VERSION "HNNBNNNYNNNNNNNNNNNNNNNNNNNNNNNNNNNNNNNNNN/4/%%%/4/'%**4NNN///"

NS_ :

BS_:

BU_: BAP_Tester BedienDisp_vo BedienSG_hi CGS DDA Gateway Gateway_PAG GurtMikrofon OTA_FC ZR_High ZR_LIMU ZR_MIB_TOP_ab_Gen3 ZR_Standard

BO_ 1891 ISO_Gurtmikro_Req: 8 Gateway
 SG_ ISO_Gurtmikro_Req_Data : 0|64@1+ (1.0,0.0) [0.0|18446744073709551615] ""  GurtMikrofon

BO_ 1997 ISO_Gurtmikro_Resp: 8 GurtMikrofon
 SG_ ISO_Gurtmikro_Resp_Data : 0|64@1+ (1.0,0.0) [0.0|18446744073709551615] ""  Gateway,Gateway_PAG

BO_ 1907 ISO_Info_El_Req: 8 Gateway
 SG_ ISO_Info_El_Req_Data : 0|64@1+ (1.0,0.0) [0.0|18446744073709551615] ""  ZR_High,ZR_LIMU,ZR_MIB_TOP_ab_Gen3,ZR_Standard

BO_ 2013 ISO_Info_El_Resp: 8 ZR_High
 SG_ ISO_Info_El_Resp_Data : 0|64@1+ (1.0,0.0) [0.0|18446744073709551615] ""  Gateway,Gateway_PAG

BO_ 1904 ISO_Laufwerke_Req: 8 Gateway
 SG_ ISO_Laufwerke_Req_Data : 0|64@1+ (1.0,0.0) [0.0|18446744073709551615] ""  ZR_High,ZR_MIB_TOP_ab_Gen3,ZR_Standard

BO_ 2010 ISO_Laufwerke_Resp: 8 ZR_High
 SG_ ISO_Laufwerke_Resp_Data : 0|64@1+ (1.0,0.0) [0.0|18446744073709551615] ""  Gateway,Gateway_PAG

BO_ 1901 ISO_TV_Tuner_Req: 8 Gateway
 SG_ ISO_TV_Tuner_Req_Data : 0|64@1+ (1.0,0.0) [0.0|18446744073709551615] ""  ZR_High,ZR_MIB_TOP_ab_Gen3,ZR_Standard

BO_ 2007 ISO_TV_Tuner_Resp: 8 ZR_High
 SG_ ISO_TV_Tuner_Resp_Data : 0|64@1+ (1.0,0.0) [0.0|18446744073709551615] ""  Gateway,Gateway_PAG

BO_ 2549874830 ISOx_BedienDisp_vo_Req: 8 Gateway
 SG_ ISOx_BedienDisp_vo_Req_Data : 0|64@1+ (1.0,0.0) [0.0|18446744073709551615] ""  BedienDisp_vo

BO_ 2550005902 ISOx_BedienDisp_vo_Resp: 8 BedienDisp_vo
 SG_ ISOx_BedienDisp_vo_Resp_Data : 0|64@1+ (1.0,0.0) [0.0|18446744073709551615] ""  Gateway,Gateway_PAG

BO_ 2549874835 ISOx_BedienSG_hi_Req: 8 Gateway
 SG_ ISOx_BedienSG_hi_Req_Data : 0|64@1+ (1.0,0.0) [0.0|18446744073709551615] ""  BedienSG_hi

BO_ 2550005907 ISOx_BedienSG_hi_Resp: 8 BedienSG_hi
 SG_ ISOx_BedienSG_hi_Resp_Data : 0|64@1+ (1.0,0.0) [0.0|18446744073709551615] ""  Gateway,Gateway_PAG

BO_ 2549874874 ISOx_DDA_Req: 8 Gateway
 SG_ ISOx_DDA_Req_Data : 0|64@1+ (1.0,0.0) [0.0|18446744073709551615] ""  DDA

BO_ 2550005946 ISOx_DDA_Resp: 8 DDA
 SG_ ISOx_DDA_Resp_Data : 0|64@1+ (1.0,0.0) [0.0|18446744073709551615] ""  Gateway,Gateway_PAG

BO_ 2549874858 ISOx_SCC1_Req: 8 Gateway
 SG_ ISOx_SCC1_Req_Data : 0|64@1+ (1.0,0.0) [0.0|18446744073709551615] ""  ZR_High,ZR_MIB_TOP_ab_Gen3

BO_ 2550005930 ISOx_SCC1_Resp: 8 ZR_High
 SG_ ISOx_SCC1_Resp_Data : 0|64@1+ (1.0,0.0) [0.0|18446744073709551615] ""  Gateway,Gateway_PAG

BO_ 2549874859 ISOx_SCC2_Req: 8 Gateway
 SG_ ISOx_SCC2_Req_Data : 0|64@1+ (1.0,0.0) [0.0|18446744073709551615] ""  ZR_High,ZR_MIB_TOP_ab_Gen3

BO_ 2550005931 ISOx_SCC2_Resp: 8 ZR_High
 SG_ ISOx_SCC2_Resp_Data : 0|64@1+ (1.0,0.0) [0.0|18446744073709551615] ""  Gateway,Gateway_PAG

BO_ 2549874855 ISOx_SDC1_Req: 8 Gateway
 SG_ ISOx_SDC1_Req_Data : 0|64@1+ (1.0,0.0) [0.0|18446744073709551615] ""  ZR_High,ZR_MIB_TOP_ab_Gen3

BO_ 2550005927 ISOx_SDC1_Resp: 8 ZR_High
 SG_ ISOx_SDC1_Resp_Data : 0|64@1+ (1.0,0.0) [0.0|18446744073709551615] ""  Gateway,Gateway_PAG

BO_ 2549874856 ISOx_SDC2_Req: 8 Gateway
 SG_ ISOx_SDC2_Req_Data : 0|64@1+ (1.0,0.0) [0.0|18446744073709551615] ""  ZR_High,ZR_MIB_TOP_ab_Gen3

BO_ 2550005928 ISOx_SDC2_Resp: 8 ZR_High
 SG_ ISOx_SDC2_Resp_Data : 0|64@1+ (1.0,0.0) [0.0|18446744073709551615] ""  Gateway,Gateway_PAG

BO_ 2549874853 ISOx_WLC1_Req: 8 Gateway
 SG_ ISOx_WLC1_Req_Data : 0|64@1+ (1.0,0.0) [0.0|18446744073709551615] ""  ZR_High,ZR_MIB_TOP_ab_Gen3,ZR_Standard

BO_ 2550005925 ISOx_WLC1_Resp: 8 ZR_High
 SG_ ISOx_WLC1_Resp_Data : 0|64@1+ (1.0,0.0) [0.0|18446744073709551615] ""  Gateway,Gateway_PAG

BO_ 2549874854 ISOx_WLC2_Req: 8 Gateway
 SG_ ISOx_WLC2_Req_Data : 0|64@1+ (1.0,0.0) [0.0|18446744073709551615] ""  ZR_High,ZR_MIB_TOP_ab_Gen3

BO_ 2550005926 ISOx_WLC2_Resp: 8 ZR_High
 SG_ ISOx_WLC2_Resp_Data : 0|64@1+ (1.0,0.0) [0.0|18446744073709551615] ""  Gateway,Gateway_PAG

BO_ 497 Kessy_11: 8 Gateway
 SG_ KY_IDG_in_Reichweite : 12|1@1+ (1.0,0.0) [0.0|1] ""  Vector__XXX
 SG_ KY_Auf_Taste : 13|1@1+ (1.0,0.0) [0.0|1] ""  Vector__XXX
 SG_ KY_HDF_Taste : 14|1@1+ (1.0,0.0) [0.0|1] ""  Vector__XXX
 SG_ KY_Panik_Taste : 15|1@1+ (1.0,0.0) [0.0|1] ""  Vector__XXX
 SG_ KY_Zu_Taste : 16|1@1+ (1.0,0.0) [0.0|1] ""  Vector__XXX
 SG_ KY_FT_Entriegelung_Autorisiert : 17|1@1+ (1.0,0.0) [0.0|1] ""  ZR_High
 SG_ KY_FT_Verriegelung_Autorisiert : 18|1@1+ (1.0,0.0) [0.0|1] ""  ZR_High
 SG_ KY_BT_Entriegelung_Autorisiert : 19|1@1+ (1.0,0.0) [0.0|1] ""  ZR_High
 SG_ KY_BT_Verriegelung_Autorisiert : 20|1@1+ (1.0,0.0) [0.0|1] ""  ZR_High
 SG_ KY_HFS_Entriegelung_Autorisiert : 21|1@1+ (1.0,0.0) [0.0|1] ""  ZR_High
 SG_ KY_HFS_Verriegelung_Autorisiert : 22|1@1+ (1.0,0.0) [0.0|1] ""  ZR_High
 SG_ KY_HBFS_Entriegelung_Autorisiert : 23|1@1+ (1.0,0.0) [0.0|1] ""  ZR_High
 SG_ KY_HBFS_Verriegelung_Autorisiert : 24|1@1+ (1.0,0.0) [0.0|1] ""  ZR_High
 SG_ KY_Front_Entr_Autorisiert : 25|1@1+ (1.0,0.0) [0.0|1] ""  ZR_High
 SG_ KY_Front_Verr_Autorisiert : 26|1@1+ (1.0,0.0) [0.0|1] ""  ZR_High
 SG_ KY_HD_Entriegelung_Autorisiert : 27|1@1+ (1.0,0.0) [0.0|1] ""  ZR_High
 SG_ KY_HD_Verriegelung_Autorisiert : 28|1@1+ (1.0,0.0) [0.0|1] ""  ZR_High
 SG_ KY_Bereich : 29|3@1+ (1.0,0.0) [0.0|7] ""  Vector__XXX
 SG_ KY_Position : 32|3@1+ (1.0,0.0) [0.0|7] ""  Vector__XXX
 SG_ KY_ZV_Signatur : 35|11@1+ (1,0) [0|2047] "Unit_None"  Vector__XXX
 SG_ Schluesselnr_Personalisierung : 46|4@1+ (1.0,0.0) [0.0|15] ""  BedienSG_hi,ZR_High
 SG_ FFB_FDF_Taste : 50|1@1+ (1.0,0.0) [0.0|1] ""  Vector__XXX
 SG_ FFB_Joker_Taste : 51|1@1+ (1.0,0.0) [0.0|1] ""  ZR_High
 SG_ FFB_Park_Taste : 52|1@1+ (1.0,0.0) [0.0|1] ""  Vector__XXX
 SG_ FFB_Remotestart_Taste : 53|1@1+ (1.0,0.0) [0.0|1] ""  Vector__XXX
 SG_ FBS_Aktivierung_Pilot_Parken : 54|1@1+ (1.0,0.0) [0.0|1] ""  ZR_High
 SG_ KY_Schluessel_im_Fzg : 55|1@1+ (1.0,0.0) [0.0|1] ""  Vector__XXX
 SG_ KY_EasyClose_Abbruch : 56|1@1+ (1.0,0.0) [0.0|1] ""  Vector__XXX
 SG_ KY_EasyClose_Status : 57|3@1+ (1.0,0.0) [0.0|7] ""  ZR_High
 SG_ KY_HD_Auffahrt : 60|1@1+ (1.0,0.0) [0.0|1] ""  ZR_High
 SG_ KY_HD_Zufahrt : 61|1@1+ (1.0,0.0) [0.0|1] ""  ZR_High
 SG_ KY_LKL_1_Autorisierung : 62|1@1+ (1.0,0.0) [0.0|1] ""  Vector__XXX
 SG_ KY_LKL_2_Autorisierung : 63|1@1+ (1.0,0.0) [0.0|1] ""  Vector__XXX

BO_ 1424 Kessy_12: 8 Gateway
 SG_ FBS_Warn_Schluessel_Batt : 12|1@1+ (1.0,0.0) [0.0|1] ""  Vector__XXX
 SG_ KY_FFB_Frequenz : 13|2@1+ (1.0,0.0) [0.0|3] ""  Vector__XXX
 SG_ KY_HF_Aktiv : 15|1@1+ (1.0,0.0) [0.0|1] ""  Vector__XXX
 SG_ KY_LF_Aktiv : 16|1@1+ (1.0,0.0) [0.0|1] ""  ZR_High,ZR_LIMU,ZR_MIB_TOP_ab_Gen3,ZR_Standard
 SG_ KY_KYL_Fahrer_Hinweise : 17|3@1+ (1.0,0.0) [0.0|7] ""  Vector__XXX
 SG_ KY_StartStopp_Info : 20|2@1+ (1.0,0.0) [0.0|3] ""  Vector__XXX
 SG_ KY_Keyless_Verbau : 22|1@1+ (1.0,0.0) [0.0|1] ""  ZR_High
 SG_ KY_Keyless_Go_Verbau : 23|1@1+ (1.0,0.0) [0.0|1] ""  ZR_High
 SG_ KY_Transponder_aktiv : 24|1@1+ (1.0,0.0) [0.0|1] ""  Vector__XXX
 SG_ KYL_Warn_kein_Schluessel : 25|1@1+ (1.0,0.0) [0.0|1] ""  Vector__XXX
 SG_ KYL_Warn_Kessy_defekt : 26|1@1+ (1.0,0.0) [0.0|1] ""  Vector__XXX
 SG_ KYL_Warn_Notzuendschloss : 27|1@1+ (1.0,0.0) [0.0|1] ""  Vector__XXX
 SG_ KY_Fzg_Verlassen_erkannt : 28|1@1+ (1.0,0.0) [0.0|1] ""  Vector__XXX
 SG_ KY_Fzg_Zugang_erkannt : 29|1@1+ (1.0,0.0) [0.0|1] ""  Vector__XXX
 SG_ KY_Indikator_Mehrere_Schluessel : 30|1@1+ (1.0,0.0) [0.0|1] ""  ZR_High
 SG_ KY_NFC_Fahrer_Hinweise : 41|3@1+ (1.0,0.0) [0.0|7] ""  Vector__XXX
 SG_ KST_Wegstrecke_Challenge : 44|20@1+ (1.0,0.0) [0.0|1048575] ""  Vector__XXX

BO_ 960 Klemmen_Status_01: 4 Gateway
 SG_ Klemmen_Status_01_CRC : 0|8@1+ (1,0) [0|255] ""  ZR_High,ZR_LIMU,ZR_MIB_TOP_ab_Gen3,ZR_Standard
 SG_ Klemmen_Status_01_BZ : 8|4@1+ (1,0) [0|15] ""  ZR_High,ZR_LIMU,ZR_MIB_TOP_ab_Gen3,ZR_Standard
 SG_ RSt_Fahrerhinweise : 12|4@1+ (1.0,0.0) [0.0|15] ""  ZR_High,ZR_LIMU,ZR_MIB_TOP_ab_Gen3,ZR_Standard
 SG_ ZAS_Kl_S : 16|1@1+ (1.0,0.0) [0.0|1] ""  BedienDisp_vo,BedienSG_hi,GurtMikrofon,OTA_FC,ZR_High,ZR_LIMU,ZR_MIB_TOP_ab_Gen3,ZR_Standard
 SG_ ZAS_Kl_15 : 17|1@1+ (1.0,0.0) [0.0|1] ""  BedienDisp_vo,BedienSG_hi,DDA,GurtMikrofon,OTA_FC,ZR_High,ZR_LIMU,ZR_MIB_TOP_ab_Gen3,ZR_Standard
 SG_ ZAS_Kl_X : 18|1@1+ (1.0,0.0) [0.0|1] ""  ZR_High,ZR_LIMU,ZR_MIB_TOP_ab_Gen3,ZR_Standard
 SG_ ZAS_Kl_50_Startanforderung : 19|1@1+ (1.0,0.0) [0.0|1] ""  BedienDisp_vo,BedienSG_hi,OTA_FC,ZR_High,ZR_LIMU,ZR_MIB_TOP_ab_Gen3,ZR_Standard
 SG_ BCM_Remotestart_Betrieb : 20|1@1+ (1.0,0.0) [0.0|1] ""  BedienSG_hi,ZR_High,ZR_LIMU,ZR_MIB_TOP_ab_Gen3,ZR_Standard
 SG_ ZAS_Kl_Infotainment : 21|1@1+ (1.0,0.0) [0.0|1] ""  BedienDisp_vo,BedienSG_hi,ZR_High,ZR_LIMU,ZR_MIB_TOP_ab_Gen3,ZR_Standard
 SG_ BCM_Remotestart_KL15_Anf : 22|1@1+ (1.0,0.0) [0.0|1] ""  ZR_High,ZR_LIMU,ZR_MIB_TOP_ab_Gen3,ZR_Standard
 SG_ BCM_Remotestart_MO_Start : 23|1@1+ (1.0,0.0) [0.0|1] ""  ZR_High,ZR_LIMU,ZR_MIB_TOP_ab_Gen3,ZR_Standard
 SG_ KST_Warn_P1_ZST_def : 24|1@1+ (1.0,0.0) [0.0|1] ""  ZR_High,ZR_LIMU,ZR_MIB_TOP_ab_Gen3,ZR_Standard
 SG_ KST_Warn_P2_ZST_def : 25|1@1+ (1.0,0.0) [0.0|1] ""  ZR_High,ZR_LIMU,ZR_MIB_TOP_ab_Gen3,ZR_Standard
 SG_ KST_Fahrerhinweis_1 : 26|1@1+ (1.0,0.0) [0.0|1] ""  ZR_High,ZR_LIMU,ZR_MIB_TOP_ab_Gen3,ZR_Standard
 SG_ KST_Fahrerhinweis_2 : 27|1@1+ (1.0,0.0) [0.0|1] ""  ZR_High,ZR_LIMU,ZR_MIB_TOP_ab_Gen3,ZR_Standard
 SG_ BCM_Ausparken_Betrieb : 28|1@1+ (1.0,0.0) [0.0|1] ""  ZR_High,ZR_LIMU,ZR_MIB_TOP_ab_Gen3,ZR_Standard
 SG_ KST_Fahrerhinweis_4 : 29|1@1+ (1.0,0.0) [0.0|1] ""  ZR_High,ZR_LIMU,ZR_MIB_TOP_ab_Gen3,ZR_Standard
 SG_ KST_Fahrerhinweis_5 : 30|1@1+ (1.0,0.0) [0.0|1] ""  ZR_High,ZR_LIMU,ZR_MIB_TOP_ab_Gen3,ZR_Standard
 SG_ KST_Fahrerhinweis_6 : 31|1@1+ (1.0,0.0) [0.0|1] ""  ZR_High,ZR_LIMU,ZR_MIB_TOP_ab_Gen3,ZR_Standard

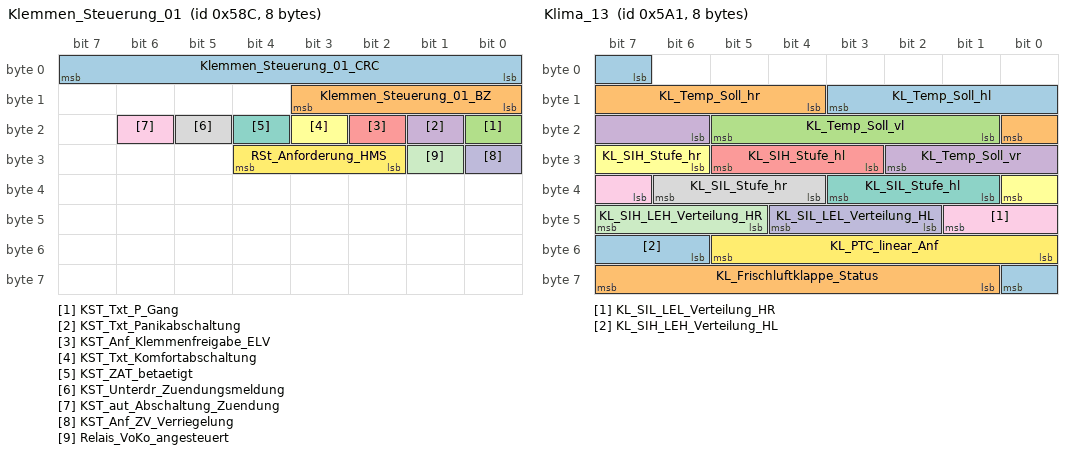
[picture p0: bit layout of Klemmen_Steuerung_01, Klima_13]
BO_ 1420 Klemmen_Steuerung_01: 8 Gateway
 SG_ Klemmen_Steuerung_01_CRC : 0|8@1+ (1,0) [0|255] ""  Vector__XXX
 SG_ Klemmen_Steuerung_01_BZ : 8|4@1+ (1,0) [0|15] ""  Vector__XXX
 SG_ KST_Txt_P_Gang : 16|1@1+ (1.0,0.0) [0.0|1] ""  Vector__XXX
 SG_ KST_Txt_Panikabschaltung : 17|1@1+ (1.0,0.0) [0.0|1] ""  Vector__XXX
 SG_ KST_Anf_Klemmenfreigabe_ELV : 18|1@1+ (1.0,0.0) [0.0|1] ""  Vector__XXX
 SG_ KST_Txt_Komfortabschaltung : 19|1@1+ (1.0,0.0) [0.0|1] ""  Vector__XXX
 SG_ KST_ZAT_betaetigt : 20|1@1+ (1.0,0.0) [0.0|1] ""  ZR_High
 SG_ KST_Unterdr_Zuendungsmeldung : 21|1@1+ (1.0,0.0) [0.0|1] ""  Vector__XXX
 SG_ KST_aut_Abschaltung_Zuendung : 22|1@1+ (1.0,0.0) [0.0|1] ""  Vector__XXX
 SG_ KST_Anf_ZV_Verriegelung : 24|1@1+ (1.0,0.0) [0.0|1] ""  Vector__XXX
 SG_ Relais_VoKo_angesteuert : 25|1@1+ (1.0,0.0) [0.0|1] ""  Vector__XXX
 SG_ RSt_Anforderung_HMS : 26|3@1+ (1.0,0.0) [0.0|7] ""  Vector__XXX

BO_ 1646 Klima_03: 8 Gateway
 SG_ KL_STL_aktiv : 0|1@1+ (1.0,0.0) [0.0|1] ""  ZR_High
 SG_ KL_STH_aktiv : 1|1@1+ (1.0,0.0) [0.0|1] ""  ZR_High
 SG_ KL_Solarluefter_aktiv : 2|1@1+ (1.0,0.0) [0.0|1] ""  ZR_High
 SG_ KL_Umluft_Taste : 3|1@1+ (1.0,0.0) [0.0|1] ""  OTA_FC,ZR_High
 SG_ KL_Geblaese_Fond_Status : 4|4@1+ (1.0,0.0) [0.0|15] ""  ZR_High
 SG_ KL_STH_Ansteuerung : 8|2@1+ (1.0,0.0) [0.0|3] ""  ZR_High
 SG_ KL_STH_Betriebsdauer : 10|6@1+ (1,0) [0|60] "Unit_Minut"  ZR_High
 SG_ KL_Magnetventil : 16|1@1+ (1.0,0.0) [0.0|1] ""  Vector__XXX
 SG_ KL_WaPu : 17|1@1+ (1.0,0.0) [0.0|1] ""  Vector__XXX
 SG_ KL_Geblaese_Status : 18|4@1+ (1.0,0.0) [0.0|15] ""  OTA_FC,ZR_High
 SG_ KL_Restwaerme_aktiv : 22|1@1+ (1.0,0.0) [0.0|1] ""  Vector__XXX
 SG_ KL_Kompressorkupplung : 23|1@1+ (1.0,0.0) [0.0|1] ""  Vector__XXX
 SG_ KL_BCmE_Livetip_Freigabe : 24|1@1+ (1.0,0.0) [0.0|1] ""  Vector__XXX
 SG_ KL_HYB_ASV_hinten_schliessen_Anf : 25|1@1+ (1.0,0.0) [0.0|1] ""  Vector__XXX
 SG_ KL_HYB_ASV_vorne_schliessen_Anf : 26|1@1+ (1.0,0.0) [0.0|1] ""  Vector__XXX
 SG_ KL_ErwVK_Zusatzrelais : 27|1@1+ (1.0,0.0) [0.0|1] ""  Vector__XXX
 SG_ KL_Status_Beduftung : 28|1@1+ (1.0,0.0) [0.0|1] ""  Vector__XXX
 SG_ KL_Status_Ionisator_Front : 29|1@1+ (1.0,0.0) [0.0|1] ""  Vector__XXX
 SG_ KL_STH_Timer_Status : 30|1@1+ (1.0,0.0) [0.0|1] ""  Vector__XXX
 SG_ KL_ErwVK_Anf : 31|1@1+ (1.0,0.0) [0.0|1] ""  OTA_FC
 SG_ KL_Innen_Temp : 32|8@1+ (0.5,-50) [-50.0|76.0] "Unit_DegreCelsi"  BedienSG_hi,OTA_FC,ZR_High
 SG_ KL_I_Geblaese_Fond : 40|8@1+ (0.25,0) [0.00|63.50] "Unit_Amper"  Vector__XXX
 SG_ KL_Anf_AussenspiegelHzg : 48|1@1+ (1.0,0.0) [0.0|1] ""  ZR_High
 SG_ KL_Heizkreisventilstellung : 49|2@1+ (1.0,0.0) [0.0|3] ""  Vector__XXX
 SG_ KL_FSH_Automatikbetrieb : 51|1@1+ (1.0,0.0) [0.0|1] ""  Vector__XXX
 SG_ KL_SIH_LEH_Verteilung_VL : 52|3@1+ (1.0,0.0) [0.0|7] ""  ZR_High
 SG_ KL_SIH_LEL_Verteilung_VL : 55|3@1+ (1.0,0.0) [0.0|7] ""  ZR_High
 SG_ KL_SIH_LEH_Verteilung_VR : 58|3@1+ (1.0,0.0) [0.0|7] ""  ZR_High
 SG_ KL_SIH_LEL_Verteilung_VR : 61|3@1+ (1.0,0.0) [0.0|7] ""  ZR_High

BO_ 1663 Klima_05: 8 Gateway
 SG_ KL_Mod_Display_li : 0|4@1+ (1.0,0.0) [0.0|15] ""  ZR_High
 SG_ KL_Mod_Display_re : 4|4@1+ (1.0,0.0) [0.0|15] ""  ZR_High
 SG_ KL_Fondbed_vorne_aktiv : 8|1@1+ (1.0,0.0) [0.0|1] ""  Vector__XXX
 SG_ KL_Fond_re_reduziert : 9|1@1+ (1.0,0.0) [0.0|1] ""  Vector__XXX
 SG_ KL_Fond_li_reduziert : 10|1@1+ (1.0,0.0) [0.0|1] ""  Vector__XXX
 SG_ KL_Absperrventil_Fond : 11|1@1+ (1.0,0.0) [0.0|1] ""  Vector__XXX
 SG_ KL_SH_HL_Lastabschaltung : 12|2@1+ (1.0,0.0) [0.0|3] ""  Vector__XXX
 SG_ KL_SH_HR_Lastabschaltung : 14|2@1+ (1.0,0.0) [0.0|3] ""  Vector__XXX
 SG_ KL_Sollausblastemp_HL : 16|10@1+ (0.1,0) [0.0|102.2] "Unit_DegreCelsi"  Vector__XXX
 SG_ KL_Einheiten : 26|1@1+ (1.0,0.0) [0.0|1] ""  ZR_High
 SG_ KL_Kindersicherung : 27|1@1+ (1.0,0.0) [0.0|1] ""  Vector__XXX
 SG_ KL_Heizverbraucher_aus : 28|1@1+ (1.0,0.0) [0.0|1] ""  Vector__XXX
 SG_ KL_Heizverbraucher_Notaus : 29|1@1+ (1.0,0.0) [0.0|1] ""  Vector__XXX
 SG_ KL_Gebl_Verst_Abs_Modus : 30|1@1+ (1.0,0.0) [0.0|1] ""  Vector__XXX
 SG_ KL_Sollausblastemp_HR : 32|10@1+ (0.1,0) [0.0|102.2] "Unit_DegreCelsi"  Vector__XXX
 SG_ KL_ICO2_Sensor_defekt : 42|2@1+ (1.0,0.0) [0.0|3] ""  ZR_High
 SG_ KL_Umluft : 48|8@1+ (0.5,0) [0.0|100.0] "Unit_PerCent"  ZR_High
 SG_ KL_Geblaesespg_Fond : 56|8@1+ (0.1,0) [0.0|25.5] "Unit_Volt"  Vector__XXX

BO_ 1608 Klima_07: 8 Gateway
 SG_ KL_AUTO_HL_Soll : 0|1@1+ (1.0,0.0) [0.0|1] ""  ZR_High
 SG_ KL_AUTO_HR_Soll : 1|1@1+ (1.0,0.0) [0.0|1] ""  ZR_High
 SG_ KL_AC_Fond_Soll : 2|1@1+ (1.0,0.0) [0.0|1] ""  Vector__XXX
 SG_ KL_Fondbedienung_aktiv : 3|1@1+ (1.0,0.0) [0.0|1] ""  ZR_High
 SG_ KL_Status_Soll : 4|1@1+ (1.0,0.0) [0.0|1] ""  ZR_High
 SG_ KL_Befehlszaehler_FH : 5|3@1+ (1,0) [0|7] ""  ZR_High
 SG_ KL_Luftmenge_HR_Soll : 8|4@1+ (1,0) [0|12] ""  ZR_High
 SG_ KL_Luftmenge_HL_Soll : 12|4@1+ (1,0) [0|12] ""  ZR_High
 SG_ KL_Luftverteilung_HR_Soll : 16|4@1+ (1.0,0.0) [0.0|15] ""  ZR_High
 SG_ KL_Luftverteilung_HL_Soll : 20|4@1+ (1.0,0.0) [0.0|15] ""  ZR_High
 SG_ KL_SL_HL_Soll : 24|3@1+ (1,0) [0|6] ""  ZR_High
 SG_ KL_SL_HR_Soll : 27|3@1+ (1,0) [0|6] ""  ZR_High
 SG_ KL_SH_HR_Soll : 30|3@1+ (1,0) [0|6] ""  ZR_High
 SG_ KL_SH_HL_Soll : 33|3@1+ (1,0) [0|6] ""  ZR_High
 SG_ KL_Temp_HL_Soll : 36|5@1+ (0.5,15.5) [15.5|30.0] "Unit_DegreCelsi"  ZR_High
 SG_ KL_Temp_HR_Soll : 41|5@1+ (0.5,15.5) [15.5|30.0] "Unit_DegreCelsi"  ZR_High
 SG_ KL_Luftmenge_HR_max : 46|4@1+ (1,0) [0|12] ""  ZR_High
 SG_ KL_Luftmenge_HL_max : 50|4@1+ (1,0) [0|12] ""  ZR_High
 SG_ KL_Luftmenge_HR_offset : 54|5@1+ (1,-12) [-12|12] ""  ZR_High
 SG_ KL_Luftmenge_HL_offset : 59|5@1+ (1,-12) [-12|12] ""  ZR_High

BO_ 949 Klima_11: 8 Gateway
 SG_ KL_Drehz_Anh : 0|1@1+ (1.0,0.0) [0.0|1] ""  Vector__XXX
 SG_ KL_Vorwarn_Komp_ein : 1|1@1+ (1.0,0.0) [0.0|1] ""  Vector__XXX
 SG_ KL_AC_Schalter : 2|1@1+ (1.0,0.0) [0.0|1] ""  OTA_FC,ZR_High
 SG_ KL_Komp_Moment_alt : 3|1@1+ (1.0,0.0) [0.0|1] ""  Vector__XXX
 SG_ KL_Vorwarn_Zuheizer_ein : 6|1@1+ (1.0,0.0) [0.0|1] ""  Vector__XXX
 SG_ KL_Zustand : 7|1@1+ (1.0,0.0) [0.0|1] ""  OTA_FC
 SG_ KL_Kompressorkupplung_linear : 8|8@1+ (20,0) [0|4000] "Unit_MilliAmper"  Vector__XXX
 SG_ KL_Charisma_FahrPr : 16|4@1+ (1.0,0.0) [0.0|15] ""  OTA_FC
 SG_ KL_Charisma_Status : 20|2@1+ (1.0,0.0) [0.0|3] ""  Vector__XXX
 SG_ KL_nachtr_Stopp_Anf : 22|1@1+ (1.0,0.0) [0.0|1] ""  Vector__XXX
 SG_ KL_T_Charge : 23|1@1+ (1.0,0.0) [0.0|1] ""  Vector__XXX
 SG_ KL_Last_Kompr : 24|8@1+ (0.25,0) [0.00|63.50] "Unit_NewtoMeter"  Vector__XXX
 SG_ KL_Spannungs_Anf : 32|2@1+ (1.0,0.0) [0.0|3] ""  Vector__XXX
 SG_ KL_Thermomanagement : 34|2@1+ (1.0,0.0) [0.0|3] ""  Vector__XXX
 SG_ KL_StartStopp_Info : 36|2@1+ (1.0,0.0) [0.0|3] ""  Vector__XXX
 SG_ KL_Freilauf_Info : 38|2@1+ (1.0,0.0) [0.0|3] ""  Vector__XXX
 SG_ KL_Anf_KL : 40|8@1+ (0.4,0) [0.0|101.6] "Unit_PerCent"  Vector__XXX
 SG_ KL_el_Zuheizer_Stufe : 48|3@1+ (1.0,0.0) [0.0|7] ""  Vector__XXX
 SG_ KL_Ausstattung_Klima : 51|3@1+ (1.0,0.0) [0.0|7] ""  Vector__XXX
 SG_ KL_Variante_Standheizung : 54|2@1+ (1.0,0.0) [0.0|3] ""  Vector__XXX

BO_ 1640 Klima_12: 8 Gateway
 SG_ KL_LRH_Taster : 0|1@1+ (1.0,0.0) [0.0|1] ""  OTA_FC,ZR_High
 SG_ KL_LRH_Stufe : 1|2@1+ (1.0,0.0) [0.0|3] ""  ZR_High
 SG_ HSH_Taster : 3|2@1+ (1.0,0.0) [0.0|3] ""  OTA_FC,ZR_High
 SG_ FSH_Taster : 5|1@1+ (1.0,0.0) [0.0|1] ""  OTA_FC,ZR_High
 SG_ KL_Zuheizer_Freigabe : 6|1@1+ (1.0,0.0) [0.0|1] ""  ZR_High
 SG_ KL_Beschlagsgefahr : 7|1@1+ (1.0,0.0) [0.0|1] ""  OTA_FC,ZR_High
 SG_ KL_SIH_Soll_li : 8|3@1+ (1,0) [0|6] ""  OTA_FC,ZR_High
 SG_ KL_SIH_Soll_re : 11|3@1+ (1,0) [0|6] ""  OTA_FC,ZR_High
 SG_ KRH_Soll_li : 14|2@1+ (1.0,0.0) [0.0|3] ""  ZR_High
 SG_ KL_SIL_Soll_li : 16|3@1+ (1,0) [0|6] ""  OTA_FC,ZR_High
 SG_ KL_SIL_Soll_re : 19|3@1+ (1,0) [0|6] ""  OTA_FC,ZR_High
 SG_ KRH_Soll_re : 22|2@1+ (1.0,0.0) [0.0|3] ""  ZR_High
 SG_ KL_Geblspng_Soll : 24|8@1+ (0.05,1.45) [1.50|14.00] "Unit_Volt"  Vector__XXX
 SG_ KL_Geblspng_Fond_Soll : 32|8@1+ (0.05,1.45) [1.50|14.00] "Unit_Volt"  Vector__XXX
 SG_ KL_I_Geblaese : 40|8@1+ (0.25,0) [0.00|63.50] "Unit_Amper"  ZR_High,ZR_LIMU,ZR_MIB_TOP_ab_Gen3,ZR_Standard
 SG_ KL_Kompressorstrom_soll : 48|10@1+ (1,0) [0|1021] ""  Vector__XXX
 SG_ KL_Umluftklappe_Status : 58|4@1+ (1.0,0.0) [0.0|15] ""  OTA_FC,ZR_High
 SG_ KL_PTC_Verbauinfo : 62|2@1+ (1.0,0.0) [0.0|3] ""  Vector__XXX

BO_ 1441 Klima_13: 8 Gateway
 SG_ KL_Temp_Soll_hl : 7|5@1+ (0.5,15.5) [15.5|30.0] "Unit_DegreCelsi"  ZR_High
 SG_ KL_Temp_Soll_hr : 12|5@1+ (0.5,15.5) [15.5|30.0] "Unit_DegreCelsi"  ZR_High
 SG_ KL_Temp_Soll_vl : 17|5@1+ (0.5,15.5) [15.5|30.0] "Unit_DegreCelsi"  ZR_High
 SG_ KL_Temp_Soll_vr : 22|5@1+ (0.5,15.5) [15.5|30.0] "Unit_DegreCelsi"  ZR_High
 SG_ KL_SIH_Stufe_hl : 27|3@1+ (1,0) [0|6] ""  BedienDisp_vo,ZR_High
 SG_ KL_SIH_Stufe_hr : 30|3@1+ (1,0) [0|6] ""  BedienDisp_vo,ZR_High
 SG_ KL_SIL_Stufe_hl : 33|3@1+ (1,0) [0|6] ""  BedienDisp_vo,ZR_High
 SG_ KL_SIL_Stufe_hr : 36|3@1+ (1,0) [0|6] ""  BedienDisp_vo,ZR_High
 SG_ KL_SIL_LEL_Verteilung_HR : 39|3@1+ (1.0,0.0) [0.0|7] ""  ZR_High
 SG_ KL_SIL_LEL_Verteilung_HL : 42|3@1+ (1.0,0.0) [0.0|7] ""  ZR_High
 SG_ KL_SIH_LEH_Verteilung_HR : 45|3@1+ (1.0,0.0) [0.0|7] ""  ZR_High
 SG_ KL_PTC_linear_Anf : 48|6@1+ (50,0) [0|3100] "Unit_Watt"  Vector__XXX
 SG_ KL_SIH_LEH_Verteilung_HL : 54|3@1+ (1.0,0.0) [0.0|7] ""  ZR_High
 SG_ KL_Frischluftklappe_Status : 57|7@1+ (1,0) [0|100] "Unit_PerCent"  ZR_High

BO_ 2589283621 Klima_17: 8 Gateway
 SG_ KL_NV_Energie_Anf : 12|8@1+ (10,0) [0|2530] "Unit_WattHour"  Vector__XXX
 SG_ KL_FlHz_Soll_VL : 20|3@1+ (1,0) [0|6] "Unit_None"  ZR_High
 SG_ KL_FlHz_Soll_HL : 23|3@1+ (1,0) [0|6] "Unit_None"  ZR_High
 SG_ KL_FlHz_Soll_VR : 26|3@1+ (1,0) [0|6] "Unit_None"  ZR_High
 SG_ KL_FlHz_Soll_HR : 29|3@1+ (1,0) [0|6] "Unit_None"  ZR_High
 SG_ KL_Umluft_Connect_status : 32|3@1+ (1.0,0.0) [0.0|7] ""  OTA_FC,ZR_High,ZR_Standard
 SG_ KL_ECO_PRO_Aktiv : 35|1@1+ (1.0,0.0) [0.0|1] ""  OTA_FC,ZR_High
 SG_ KL_QBit_Sonnenintensitaet : 36|1@1+ (1.0,0.0) [0.0|1] ""  OTA_FC
 SG_ KL_ZR_Anforderung : 37|2@1+ (1.0,0.0) [0.0|3] ""  OTA_FC,ZR_High,ZR_LIMU,ZR_MIB_TOP_ab_Gen3,ZR_Standard
 SG_ KL_ACmax_Aktiv : 39|1@1+ (1.0,0.0) [0.0|1] ""  OTA_FC,ZR_High
 SG_ KL_Defrost_Aktiv : 40|1@1+ (1.0,0.0) [0.0|1] ""  OTA_FC,ZR_High
 SG_ KL_ECO_Aktiv : 41|1@1+ (1.0,0.0) [0.0|1] ""  OTA_FC,ZR_High
 SG_ KL_Status_Klimastil : 42|2@1+ (1.0,0.0) [0.0|3] ""  OTA_FC,ZR_High
 SG_ KL_Kundeneingriff_Geblaese : 44|1@1+ (1.0,0.0) [0.0|1] ""  OTA_FC,ZR_High
 SG_ KL_Thermischer_Bedarf : 45|3@1+ (1.0,0.0) [0.0|7] ""  OTA_FC
 SG_ KL_Eps_Innen : 48|8@1+ (0.5,-50) [-50.0|50.0] "Unit_DegreCelsi"  OTA_FC,ZR_High
 SG_ KL_Sonnenintensitaet : 56|8@1+ (10,0) [0|1000] "Unit_WattPerMeterSquar"  OTA_FC,ZR_High

BO_ 992 Klima_hinten_01: 8 Gateway
 SG_ KL_Fond_Fuss_Temp_hl : 0|10@1+ (0.1,-5) [-5.0|97.1] "Unit_DegreCelsi"  ZR_High
 SG_ KL_SL_Soll_hl : 10|3@1+ (1.0,0.0) [0.0|7] ""  ZR_High
 SG_ KL_SL_Soll_hr : 13|3@1+ (1.0,0.0) [0.0|7] ""  ZR_High
 SG_ KL_Fond_Fuss_Temp_hr : 16|10@1+ (0.1,-5) [-5.0|97.1] "Unit_DegreCelsi"  ZR_High
 SG_ KL_SH_Soll_hl : 26|3@1+ (1.0,0.0) [0.0|7] ""  ZR_High
 SG_ KL_SH_Soll_hr : 29|3@1+ (1.0,0.0) [0.0|7] ""  ZR_High
 SG_ KL_MA_Temp_hl : 32|10@1+ (0.1,-5) [-5.0|97.1] "Unit_DegreCelsi"  ZR_High
 SG_ KL_SIH_Takt_hl : 42|1@1+ (1.0,0.0) [0.0|1] ""  Vector__XXX
 SG_ KL_SIH_Takt_hr : 43|1@1+ (1.0,0.0) [0.0|1] ""  Vector__XXX
 SG_ KL_Fehler_Umluft : 44|1@1+ (1.0,0.0) [0.0|1] ""  ZR_High
 SG_ KL_RAB : 45|1@1+ (1.0,0.0) [0.0|1] ""  Vector__XXX
 SG_ KL_Fond_Absperrventil : 46|1@1+ (1.0,0.0) [0.0|1] ""  Vector__XXX
 SG_ KL_Fond_KD_Fehler : 47|1@1+ (1.0,0.0) [0.0|1] ""  Vector__XXX
 SG_ KL_MA_Temp_hr : 48|10@1+ (0.1,-5) [-5.0|97.1] "Unit_DegreCelsi"  ZR_High
 SG_ KL_Fehler_Fussraum_Klappen : 58|2@1+ (1.0,0.0) [0.0|3] ""  ZR_High
 SG_ KL_Fehler_Temp_Klappen : 60|2@1+ (1.0,0.0) [0.0|3] ""  ZR_High
 SG_ KL_Fehler_Temp_MA_Klappen : 62|2@1+ (1.0,0.0) [0.0|3] ""  ZR_High

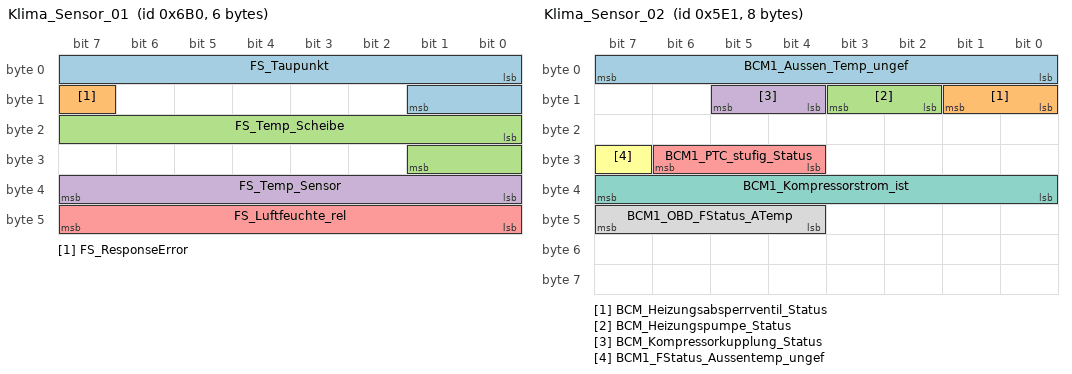
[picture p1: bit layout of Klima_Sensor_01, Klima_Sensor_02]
BO_ 1712 Klima_Sensor_01: 6 Gateway
 SG_ FS_Taupunkt : 0|10@1+ (0.1,-39.6) [-39.5|60.4] "Unit_DegreCelsi"  OTA_FC,ZR_High
 SG_ FS_ResponseError : 15|1@1+ (1.0,0.0) [0.0|1] ""  Vector__XXX
 SG_ FS_Temp_Scheibe : 16|10@1+ (0.1,-39.6) [-39.5|60.4] "Unit_DegreCelsi"  OTA_FC,ZR_High
 SG_ FS_Temp_Sensor : 32|8@1+ (0.5,-40) [-39.5|87.0] "Unit_DegreCelsi"  OTA_FC,ZR_High
 SG_ FS_Luftfeuchte_rel : 40|8@1+ (0.5,-0.5) [0.0|100.0] "Unit_PerCent"  OTA_FC

BO_ 1505 Klima_Sensor_02: 8 Gateway
 SG_ BCM1_Aussen_Temp_ungef : 0|8@1+ (0.5,-50) [-50.0|76.0] "Unit_DegreCelsi"  ZR_LIMU,ZR_MIB_TOP_ab_Gen3
 SG_ BCM_Heizungsabsperrventil_Status : 8|2@1+ (1.0,0.0) [0.0|3] ""  Vector__XXX
 SG_ BCM_Heizungspumpe_Status : 10|2@1+ (1.0,0.0) [0.0|3] ""  Vector__XXX
 SG_ BCM_Kompressorkupplung_Status : 12|2@1+ (1.0,0.0) [0.0|3] ""  Vector__XXX
 SG_ BCM1_PTC_stufig_Status : 28|3@1+ (1.0,0.0) [0.0|7] ""  Vector__XXX
 SG_ BCM1_FStatus_Aussentemp_ungef : 31|1@1+ (1.0,0.0) [0.0|1] ""  Vector__XXX
 SG_ BCM1_Kompressorstrom_ist : 32|8@1+ (4,0) [0|1000] "Unit_MilliAmper"  Vector__XXX
 SG_ BCM1_OBD_FStatus_ATemp : 44|4@1+ (1.0,0.0) [0.0|15] ""  Vector__XXX

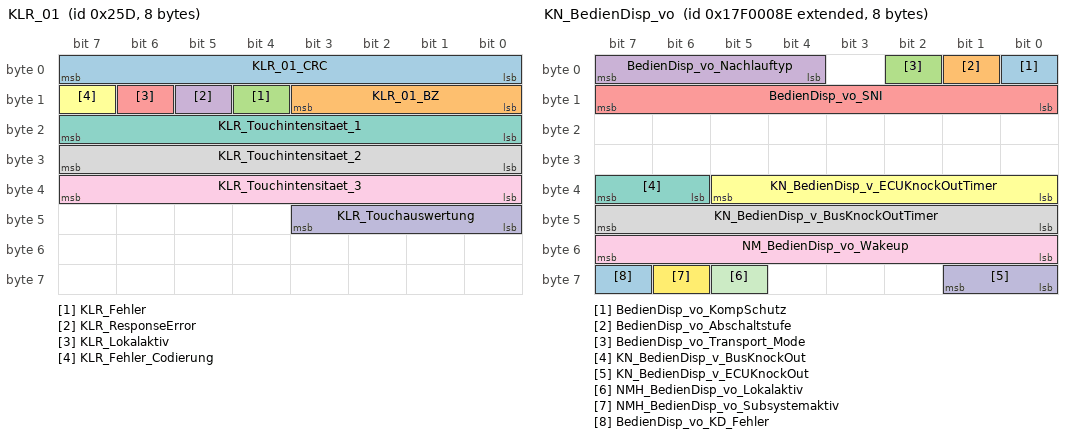
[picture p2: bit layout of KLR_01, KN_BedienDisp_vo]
BO_ 605 KLR_01: 8 Gateway
 SG_ KLR_01_CRC : 0|8@1+ (1,0) [0|255] ""  Vector__XXX
 SG_ KLR_01_BZ : 8|4@1+ (1,0) [0|15] ""  Vector__XXX
 SG_ KLR_Fehler : 12|1@1+ (1.0,0.0) [0.0|1] ""  Vector__XXX
 SG_ KLR_ResponseError : 13|1@1+ (1.0,0.0) [0.0|1] ""  Vector__XXX
 SG_ KLR_Lokalaktiv : 14|1@1+ (1.0,0.0) [0.0|1] ""  Vector__XXX
 SG_ KLR_Fehler_Codierung : 15|1@1+ (1.0,0.0) [0.0|1] ""  Vector__XXX
 SG_ KLR_Touchintensitaet_1 : 16|8@1+ (1,0) [0|250] "Unit_None"  Vector__XXX
 SG_ KLR_Touchintensitaet_2 : 24|8@1+ (1,0) [0|250] "Unit_None"  Vector__XXX
 SG_ KLR_Touchintensitaet_3 : 32|8@1+ (1,0) [0|250] "Unit_None"  Vector__XXX
 SG_ KLR_Touchauswertung : 40|4@1+ (1.0,0.0) [0.0|15] ""  ZR_High

BO_ 2549088398 KN_BedienDisp_vo: 8 BedienDisp_vo
 SG_ BedienDisp_vo_KompSchutz : 0|1@1+ (1.0,0.0) [0.0|1] ""  Vector__XXX
 SG_ BedienDisp_vo_Abschaltstufe : 1|1@1+ (1.0,0.0) [0.0|1] ""  Vector__XXX
 SG_ BedienDisp_vo_Transport_Mode : 2|1@1+ (1.0,0.0) [0.0|1] ""  Vector__XXX
 SG_ BedienDisp_vo_Nachlauftyp : 4|4@1+ (1.0,0.0) [0.0|15] ""  Gateway,Gateway_PAG
 SG_ BedienDisp_vo_SNI : 8|8@1+ (1.0,0.0) [0.0|255] ""  Gateway,Gateway_PAG
 SG_ KN_BedienDisp_v_ECUKnockOutTimer : 32|6@1+ (1,0) [0|62] "Unit_Minut"  Gateway,Gateway_PAG
 SG_ KN_BedienDisp_v_BusKnockOut : 38|2@1+ (1.0,0.0) [0.0|3] ""  Gateway,Gateway_PAG
 SG_ KN_BedienDisp_v_BusKnockOutTimer : 40|8@1+ (1,0) [0|62] "Unit_Minut"  Gateway,Gateway_PAG
 SG_ NM_BedienDisp_vo_Wakeup : 48|8@1+ (1.0,0.0) [0.0|255] ""  Vector__XXX
 SG_ KN_BedienDisp_v_ECUKnockOut : 56|2@1+ (1.0,0.0) [0.0|3] ""  Gateway,Gateway_PAG
 SG_ NMH_BedienDisp_vo_Lokalaktiv : 61|1@1+ (1.0,0.0) [0.0|1] ""  Gateway,Gateway_PAG
 SG_ NMH_BedienDisp_vo_Subsystemaktiv : 62|1@1+ (1.0,0.0) [0.0|1] ""  Vector__XXX
 SG_ BedienDisp_vo_KD_Fehler : 63|1@1+ (1.0,0.0) [0.0|1] ""  Gateway,Gateway_PAG

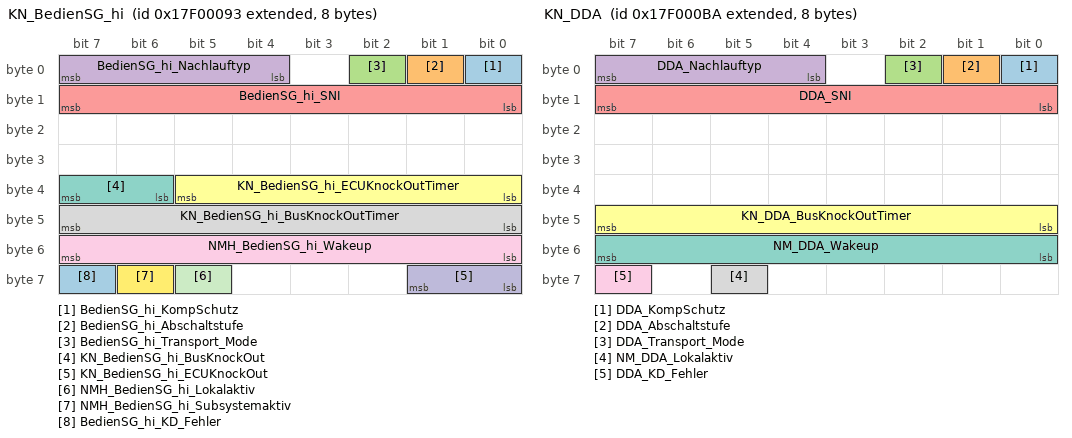
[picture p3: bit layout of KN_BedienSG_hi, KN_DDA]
BO_ 2549088403 KN_BedienSG_hi: 8 BedienSG_hi
 SG_ BedienSG_hi_KompSchutz : 0|1@1+ (1.0,0.0) [0.0|1] ""  Vector__XXX
 SG_ BedienSG_hi_Abschaltstufe : 1|1@1+ (1.0,0.0) [0.0|1] ""  Vector__XXX
 SG_ BedienSG_hi_Transport_Mode : 2|1@1+ (1.0,0.0) [0.0|1] ""  Vector__XXX
 SG_ BedienSG_hi_Nachlauftyp : 4|4@1+ (1.0,0.0) [0.0|15] ""  Gateway,Gateway_PAG
 SG_ BedienSG_hi_SNI : 8|8@1+ (1.0,0.0) [0.0|255] ""  Gateway,Gateway_PAG
 SG_ KN_BedienSG_hi_ECUKnockOutTimer : 32|6@1+ (1,0) [0|62] "Unit_Minut"  Gateway,Gateway_PAG
 SG_ KN_BedienSG_hi_BusKnockOut : 38|2@1+ (1.0,0.0) [0.0|3] ""  Gateway,Gateway_PAG
 SG_ KN_BedienSG_hi_BusKnockOutTimer : 40|8@1+ (1,0) [0|62] "Unit_Minut"  Gateway,Gateway_PAG
 SG_ NMH_BedienSG_hi_Wakeup : 48|8@1+ (1.0,0.0) [0.0|255] ""  Vector__XXX
 SG_ KN_BedienSG_hi_ECUKnockOut : 56|2@1+ (1.0,0.0) [0.0|3] ""  Gateway,Gateway_PAG
 SG_ NMH_BedienSG_hi_Lokalaktiv : 61|1@1+ (1.0,0.0) [0.0|1] ""  Gateway,Gateway_PAG
 SG_ NMH_BedienSG_hi_Subsystemaktiv : 62|1@1+ (1.0,0.0) [0.0|1] ""  Gateway,Gateway_PAG
 SG_ BedienSG_hi_KD_Fehler : 63|1@1+ (1.0,0.0) [0.0|1] ""  Gateway,Gateway_PAG

BO_ 2549088442 KN_DDA: 8 DDA
 SG_ DDA_KompSchutz : 0|1@1+ (1.0,0.0) [0.0|1] ""  Vector__XXX
 SG_ DDA_Abschaltstufe : 1|1@1+ (1.0,0.0) [0.0|1] ""  Vector__XXX
 SG_ DDA_Transport_Mode : 2|1@1+ (1.0,0.0) [0.0|1] ""  Vector__XXX
 SG_ DDA_Nachlauftyp : 4|4@1+ (1.0,0.0) [0.0|15] ""  Gateway,Gateway_PAG
 SG_ DDA_SNI : 8|8@1+ (1.0,0.0) [0.0|255] ""  Gateway,Gateway_PAG
 SG_ KN_DDA_BusKnockOutTimer : 40|8@1+ (1,0) [0|254] ""  Gateway,Gateway_PAG
 SG_ NM_DDA_Wakeup : 48|8@1+ (1.0,0.0) [0.0|255] ""  Vector__XXX
 SG_ NM_DDA_Lokalaktiv : 61|1@1+ (1.0,0.0) [0.0|1] ""  Gateway,Gateway_PAG
 SG_ DDA_KD_Fehler : 63|1@1+ (1.0,0.0) [0.0|1] ""  Gateway,Gateway_PAG

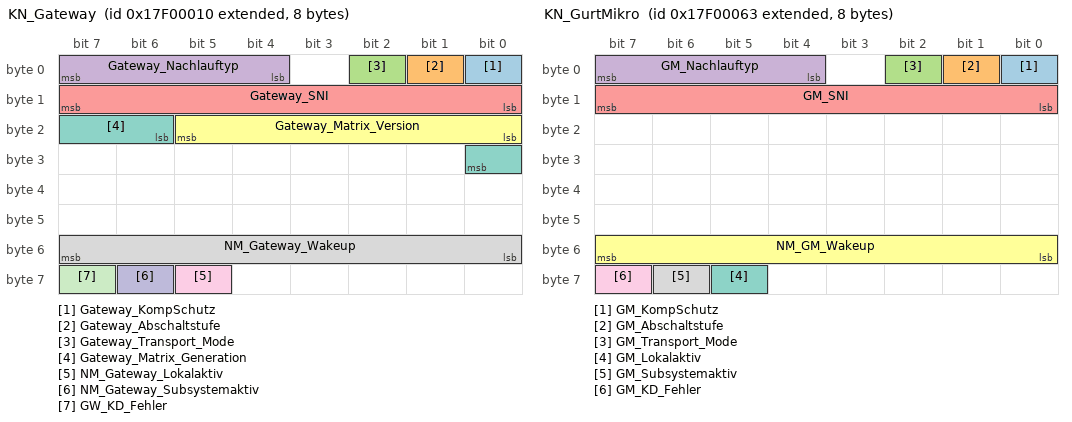
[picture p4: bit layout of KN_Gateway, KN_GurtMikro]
BO_ 2549088272 KN_Gateway: 8 Gateway
 SG_ Gateway_KompSchutz : 0|1@1+ (1.0,0.0) [0.0|1] ""  Vector__XXX
 SG_ Gateway_Abschaltstufe : 1|1@1+ (1.0,0.0) [0.0|1] ""  Vector__XXX
 SG_ Gateway_Transport_Mode : 2|1@1+ (1.0,0.0) [0.0|1] ""  Vector__XXX
 SG_ Gateway_Nachlauftyp : 4|4@1+ (1.0,0.0) [0.0|15] ""  Vector__XXX
 SG_ Gateway_SNI : 8|8@1+ (1.0,0.0) [0.0|255] ""  Vector__XXX
 SG_ Gateway_Matrix_Version : 16|6@1+ (1,0) [0|63] "Unit_None"  Vector__XXX
 SG_ Gateway_Matrix_Generation : 22|3@1+ (1,0) [0|7] "Unit_None"  Vector__XXX
 SG_ NM_Gateway_Wakeup : 48|8@1+ (1.0,0.0) [0.0|255] ""  Vector__XXX
 SG_ NM_Gateway_Lokalaktiv : 61|1@1+ (1.0,0.0) [0.0|1] ""  Vector__XXX
 SG_ NM_Gateway_Subsystemaktiv : 62|1@1+ (1.0,0.0) [0.0|1] ""  Vector__XXX
 SG_ GW_KD_Fehler : 63|1@1+ (1.0,0.0) [0.0|1] ""  Vector__XXX

BO_ 2549088355 KN_GurtMikro: 8 GurtMikrofon
 SG_ GM_KompSchutz : 0|1@1+ (1.0,0.0) [0.0|1] ""  Vector__XXX
 SG_ GM_Abschaltstufe : 1|1@1+ (1.0,0.0) [0.0|1] ""  Vector__XXX
 SG_ GM_Transport_Mode : 2|1@1+ (1.0,0.0) [0.0|1] ""  Vector__XXX
 SG_ GM_Nachlauftyp : 4|4@1+ (1.0,0.0) [0.0|15] ""  Gateway
 SG_ GM_SNI : 8|8@1+ (1.0,0.0) [0.0|255] ""  Gateway
 SG_ NM_GM_Wakeup : 48|8@1+ (1.0,0.0) [0.0|255] ""  Vector__XXX
 SG_ GM_Lokalaktiv : 61|1@1+ (1.0,0.0) [0.0|1] ""  Gateway
 SG_ GM_Subsystemaktiv : 62|1@1+ (1.0,0.0) [0.0|1] ""  Vector__XXX
 SG_ GM_KD_Fehler : 63|1@1+ (1.0,0.0) [0.0|1] ""  Gateway

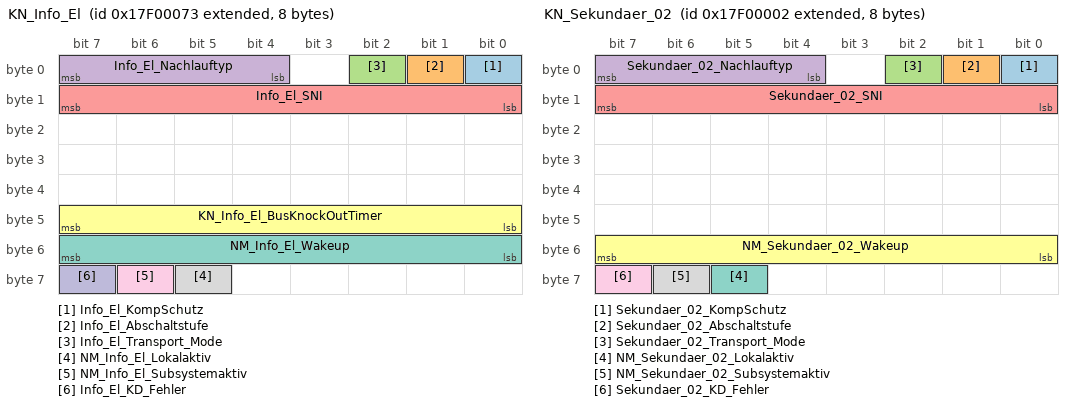
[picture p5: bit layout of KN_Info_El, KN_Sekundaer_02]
BO_ 2549088371 KN_Info_El: 8 ZR_High
 SG_ Info_El_KompSchutz : 0|1@1+ (1.0,0.0) [0.0|1] ""  Vector__XXX
 SG_ Info_El_Abschaltstufe : 1|1@1+ (1.0,0.0) [0.0|1] ""  Vector__XXX
 SG_ Info_El_Transport_Mode : 2|1@1+ (1.0,0.0) [0.0|1] ""  Vector__XXX
 SG_ Info_El_Nachlauftyp : 4|4@1+ (1.0,0.0) [0.0|15] ""  Gateway,Gateway_PAG
 SG_ Info_El_SNI : 8|8@1+ (1.0,0.0) [0.0|255] ""  Gateway,Gateway_PAG
 SG_ KN_Info_El_BusKnockOutTimer : 40|8@1+ (1,0) [0|254] "Unit_Minut"  Gateway
 SG_ NM_Info_El_Wakeup : 48|8@1+ (1.0,0.0) [0.0|255] ""  Vector__XXX
 SG_ NM_Info_El_Lokalaktiv : 61|1@1+ (1.0,0.0) [0.0|1] ""  Gateway,Gateway_PAG
 SG_ NM_Info_El_Subsystemaktiv : 62|1@1+ (1.0,0.0) [0.0|1] ""  Gateway,Gateway_PAG
 SG_ Info_El_KD_Fehler : 63|1@1+ (1.0,0.0) [0.0|1] ""  Gateway,Gateway_PAG

BO_ 2549088258 KN_Sekundaer_02: 8 OTA_FC
 SG_ Sekundaer_02_KompSchutz : 0|1@1+ (1.0,0.0) [0.0|1] ""  Vector__XXX
 SG_ Sekundaer_02_Abschaltstufe : 1|1@1+ (1.0,0.0) [0.0|1] ""  Vector__XXX
 SG_ Sekundaer_02_Transport_Mode : 2|1@1+ (1.0,0.0) [0.0|1] ""  Vector__XXX
 SG_ Sekundaer_02_Nachlauftyp : 4|4@1+ (1.0,0.0) [0.0|15] ""  Gateway_PAG
 SG_ Sekundaer_02_SNI : 8|8@1+ (1.0,0.0) [0.0|255] ""  Gateway_PAG
 SG_ NM_Sekundaer_02_Wakeup : 48|8@1+ (1.0,0.0) [0.0|255] ""  Vector__XXX
 SG_ NM_Sekundaer_02_Lokalaktiv : 61|1@1+ (1.0,0.0) [0.0|1] ""  Vector__XXX
 SG_ NM_Sekundaer_02_Subsystemaktiv : 62|1@1+ (1.0,0.0) [0.0|1] ""  Vector__XXX
 SG_ Sekundaer_02_KD_Fehler : 63|1@1+ (1.0,0.0) [0.0|1] ""  Gateway_PAG

BO_ 779 Kombi_01: 8 Gateway
 SG_ KBI_ABS_Lampe : 0|1@1+ (1.0,0.0) [0.0|1] ""  ZR_High
 SG_ KBI_ESP_Lampe : 1|1@1+ (1.0,0.0) [0.0|1] ""  ZR_High
 SG_ KBI_BKL_Lampe : 2|1@1+ (1.0,0.0) [0.0|1] ""  ZR_High
 SG_ KBI_Airbag_Lampe : 3|1@1+ (1.0,0.0) [0.0|1] ""  ZR_High
 SG_ KBI_SILA_gueltig : 4|1@1+ (1.0,0.0) [0.0|1] ""  Vector__XXX
 SG_ KBI_Lenkung_Lampe : 5|1@1+ (1,0) [0|1] ""  Vector__XXX
 SG_ KBI_Vorglueh_System_Lampe : 6|1@1+ (1.0,0.0) [0.0|1] ""  ZR_High
 SG_ KBI_NV_in_Anzeige : 7|1@1+ (1.0,0.0) [0.0|1] ""  ZR_High
 SG_ Kombi_01_BZ : 8|4@1+ (1,0) [0|15] ""  Vector__XXX
 SG_ KBI_Anzeigestatus_ACC : 12|1@1+ (1.0,0.0) [0.0|1] ""  ZR_High
 SG_ KBI_Anzeigestatus_GRA : 13|2@1+ (1.0,0.0) [0.0|3] ""  ZR_High
 SG_ KBI_Tankwarnung : 16|1@1+ (1.0,0.0) [0.0|1] ""  ZR_High,ZR_LIMU,ZR_MIB_TOP_ab_Gen3,ZR_Standard
 SG_ KBI_MFA_v_Einheit_01 : 17|1@1+ (1.0,0.0) [0.0|1] ""  BedienSG_hi,ZR_High,ZR_LIMU,ZR_MIB_TOP_ab_Gen3,ZR_Standard
 SG_ KBI_im_Stellgliedtest : 18|1@1+ (1.0,0.0) [0.0|1] ""  Vector__XXX
 SG_ KBI_Anzeigefehler_LDW : 19|2@1+ (1.0,0.0) [0.0|3] ""  Vector__XXX
 SG_ KBI_Tankwarnung_ungueltig : 21|1@1+ (1.0,0.0) [0.0|1] ""  ZR_High,ZR_LIMU,ZR_MIB_TOP_ab_Gen3,ZR_Standard
 SG_ KBI_Handbremse : 23|1@1+ (1.0,0.0) [0.0|1] ""  Vector__XXX
 SG_ KBI_V_Digital : 24|9@1+ (1,0) [0|511] ""  BedienSG_hi,ZR_High,ZR_LIMU,ZR_MIB_TOP_ab_Gen3,ZR_Standard
 SG_ KBI_PLA_in_Anzeige : 33|1@1+ (1.0,0.0) [0.0|1] ""  ZR_High
 SG_ KBI_Anzeigefehler_NV : 34|1@1+ (1.0,0.0) [0.0|1] ""  Vector__XXX
 SG_ KBI_Anzeigestatus_LIM : 35|2@1+ (1.0,0.0) [0.0|3] ""  Vector__XXX
 SG_ KBI_ARA_in_Anzeige : 37|1@1+ (1.0,0.0) [0.0|1] ""  ZR_High
 SG_ KBI_Taster_Lift : 38|1@1+ (1.0,0.0) [0.0|1] ""  Vector__XXX
 SG_ KBI_Taster_Fahrwerk : 39|1@1+ (1.0,0.0) [0.0|1] ""  Vector__XXX
 SG_ KBI_GRA_Hauptschalter : 40|2@1+ (1.0,0.0) [0.0|3] ""  Vector__XXX
 SG_ KBI_angez_Geschw : 48|10@1+ (0.32,0) [0.00|325.12] "Unit_KiloMeterPerHour"  BedienSG_hi,OTA_FC,ZR_High,ZR_LIMU,ZR_MIB_TOP_ab_Gen3,ZR_Standard
 SG_ KBI_Einheit_Tacho : 58|1@1+ (1.0,0.0) [0.0|1] ""  BedienSG_hi,ZR_High
 SG_ KBI_Konsistenz_ACC : 59|1@1+ (1.0,0.0) [0.0|1] ""  Vector__XXX
 SG_ KBI_Fehler_Anzeige_ACC : 60|1@1+ (1.0,0.0) [0.0|1] ""  ZR_High
 SG_ KBI_Anzeigefehler_SWA : 61|2@1+ (1.0,0.0) [0.0|3] ""  ZR_High
 SG_ KBI_Systemstatus : 63|1@1+ (1.0,0.0) [0.0|1] ""  Vector__XXX

BO_TX_BU_ 1891 :Gateway,Gateway_PAG;
BO_TX_BU_ 1907 :Gateway,Gateway_PAG;
BO_TX_BU_ 2013 :ZR_High,ZR_LIMU,ZR_MIB_TOP_ab_Gen3,ZR_Standard;
BO_TX_BU_ 1904 :Gateway,Gateway_PAG;
BO_TX_BU_ 2010 :ZR_High,ZR_MIB_TOP_ab_Gen3,ZR_Standard;
BO_TX_BU_ 1901 :Gateway,Gateway_PAG;
BO_TX_BU_ 2007 :ZR_High,ZR_MIB_TOP_ab_Gen3,ZR_Standard;
BO_TX_BU_ 2549874830 :Gateway,Gateway_PAG;
BO_TX_BU_ 2549874835 :Gateway,Gateway_PAG;
BO_TX_BU_ 2549874874 :Gateway,Gateway_PAG;
BO_TX_BU_ 2549874858 :Gateway,Gateway_PAG;
BO_TX_BU_ 2550005930 :ZR_High,ZR_MIB_TOP_ab_Gen3;
BO_TX_BU_ 2549874859 :Gateway,Gateway_PAG;
BO_TX_BU_ 2550005931 :ZR_High,ZR_MIB_TOP_ab_Gen3;
BO_TX_BU_ 2549874855 :Gateway,Gateway_PAG;
BO_TX_BU_ 2550005927 :ZR_High,ZR_MIB_TOP_ab_Gen3;
BO_TX_BU_ 2549874856 :Gateway,Gateway_PAG;
BO_TX_BU_ 2550005928 :ZR_High,ZR_MIB_TOP_ab_Gen3;
BO_TX_BU_ 2549874853 :Gateway,Gateway_PAG;
BO_TX_BU_ 2550005925 :ZR_High,ZR_MIB_TOP_ab_Gen3,ZR_Standard;
BO_TX_BU_ 2549874854 :Gateway,Gateway_PAG;
BO_TX_BU_ 2550005926 :ZR_High,ZR_MIB_TOP_ab_Gen3;
BO_TX_BU_ 497 :Gateway,Gateway_PAG;
BO_TX_BU_ 1424 :Gateway,Gateway_PAG;
BO_TX_BU_ 960 :Gateway,Gateway_PAG;
BO_TX_BU_ 1420 :Gateway,Gateway_PAG;
BO_TX_BU_ 1646 :Gateway,Gateway_PAG;
BO_TX_BU_ 1663 :Gateway,Gateway_PAG;
BO_TX_BU_ 1608 :Gateway,Gateway_PAG;
BO_TX_BU_ 949 :Gateway,Gateway_PAG;
BO_TX_BU_ 1640 :Gateway,Gateway_PAG;
BO_TX_BU_ 1441 :Gateway,Gateway_PAG;
BO_TX_BU_ 2589283621 :Gateway,Gateway_PAG;
BO_TX_BU_ 992 :Gateway,Gateway_PAG;
BO_TX_BU_ 1712 :Gateway,Gateway_PAG;
BO_TX_BU_ 1505 :Gateway,Gateway_PAG;
BO_TX_BU_ 605 :Gateway,Gateway_PAG;
BO_TX_BU_ 2549088272 :Gateway,Gateway_PAG;
BO_TX_BU_ 2549088371 :ZR_High,ZR_LIMU,ZR_MIB_TOP_ab_Gen3,ZR_Standard;
BO_TX_BU_ 779 :Gateway,Gateway_PAG;
CM_ BO_ 960 "MQB";
CM_ BO_ 1646 "ab MQB 7.3";
CM_ BO_ 1663 "Klima";
CM_ BO_ 949 "ab MQB 7.4";
CM_ BO_ 1640 "ab MQB IS-4";
CM_ BO_ 1712 "D4 und B8-PA

1:1 LIN-CAN Botschaft, nur bei Kl.15 EIN gesendet";
CM_ BO_ 1505 "ab MQB 7.3";
CM_ BO_ 779 "MQB";

CM_ SG_ 1891 ISO_Gurtmikro_Req_Data "Diagnose Request Gurtmicrophon";

CM_ SG_ 1997 ISO_Gurtmikro_Resp_Data "Diagnose Response Gurtmicrophon";

CM_ SG_ 1907 ISO_Info_El_Req_Data "OffBoard Tester Diagnose Request Info_El";

CM_ SG_ 2013 ISO_Info_El_Resp_Data "OffBoard Tester Diagnose Response <SG-Name>";

CM_ SG_ 1904 ISO_Laufwerke_Req_Data "Diagnose Request DVD-Wechsler";

CM_ SG_ 2010 ISO_Laufwerke_Resp_Data "Diagnose Response DVD-Wechsler";

CM_ SG_ 1901 ISO_TV_Tuner_Req_Data "Diagnose Request TV-Tuner";

CM_ SG_ 2007 ISO_TV_Tuner_Resp_Data "Diagnose Response TV-Tuner";

CM_ SG_ 2549874874 ISOx_DDA_Req_Data "Diagnose Request DDA";

CM_ SG_ 2550005946 ISOx_DDA_Resp_Data "Diagnose Response CAN HS";

CM_ SG_ 2549874858 ISOx_SCC1_Req_Data "Diagnose Request SDC1";

CM_ SG_ 2550005930 ISOx_SCC1_Resp_Data "Diagnose Response SDC1";

CM_ SG_ 2549874859 ISOx_SCC2_Req_Data "Diagnose Request SDC1";

CM_ SG_ 2550005931 ISOx_SCC2_Resp_Data "Diagnose Response SDC1";

CM_ SG_ 2549874855 ISOx_SDC1_Req_Data "Diagnose Request SDC1";

CM_ SG_ 2550005927 ISOx_SDC1_Resp_Data "Diagnose Response SDC1";

CM_ SG_ 2549874856 ISOx_SDC2_Req_Data "Diagnosekanal SDC2";

CM_ SG_ 2550005928 ISOx_SDC2_Resp_Data "Diagnosekanal SDC2";

CM_ SG_ 2549874853 ISOx_WLC1_Req_Data "Diagnose Request WLC1";

CM_ SG_ 2550005925 ISOx_WLC1_Resp_Data "Diagnose Response WLC1";

CM_ SG_ 2549874854 ISOx_WLC2_Req_Data "OffBoard Tester Diagnose Request WLC2";

CM_ SG_ 2550005926 ISOx_WLC2_Resp_Data "Diagnose Response WLC2";

CM_ SG_ 497 FBS_Aktivierung_Pilot_Parken "Aktivierung der Funktion pilotiertes Parken";
CM_ SG_ 497 FFB_FDF_Taste "FDF Taste am Funkschluessel";
CM_ SG_ 497 FFB_Joker_Taste "Frei konfigurierbare Taste auf der Funkfernbedienung (für Verdecktaste, UGDO Taste).
";
CM_ SG_ 497 FFB_Park_Taste "Parktaste Funkschluessel";
CM_ SG_ 497 FFB_Remotestart_Taste "Remotestart Taste Funkschluessel";
CM_ SG_ 497 KY_Auf_Taste "Auf-Taste Funkschluessel";
CM_ SG_ 497 KY_Bereich "Schlüsselentfernung für Funktionen Annäherungslicht, automatisches Entriegeln";
CM_ SG_ 497 KY_BT_Entriegelung_Autorisiert "Erkennung / Authorisierung Keyless BT
";
CM_ SG_ 497 KY_BT_Verriegelung_Autorisiert "Authorisierung Verriegelungssensor Keyless BT
";
CM_ SG_ 497 KY_EasyClose_Abbruch "ID-Geber während HD-Zufahrt im Nahbereich EasyClose erkannt";
CM_ SG_ 497 KY_EasyClose_Status "Signal zur LED Ansteuerung im HD-Verriegelungstaster für die Funktion EasyClose.";
CM_ SG_ 497 KY_Front_Entr_Autorisiert "Erkennung / Authorisierung Keyless Front";
CM_ SG_ 497 KY_Front_Verr_Autorisiert "Authorisierung Verriegelungssensor Keyless Front";
CM_ SG_ 497 KY_FT_Entriegelung_Autorisiert "Erkennung / Authorisierung Keyless FT
";
CM_ SG_ 497 KY_FT_Verriegelung_Autorisiert "Authorisierung Verriegelungssensor Keyless FT
";
CM_ SG_ 497 KY_HBFS_Entriegelung_Autorisiert "Erkennung / Authorisierung Keyless HBFS
";
CM_ SG_ 497 KY_HBFS_Verriegelung_Autorisiert "Authorisierung Verriegelungssensor Keyless HBFS


";
CM_ SG_ 497 KY_HD_Auffahrt "Auffahrt HD nach Wiedereintritt ID-Geber in EasyClose Nahbereich";
CM_ SG_ 497 KY_HD_Entriegelung_Autorisiert "Erkennung / Authorisierung Keyless Heck
";
CM_ SG_ 497 KY_HD_Verriegelung_Autorisiert "Autorisierung der Schließanforderung über Verriegelungsinnentaster";
CM_ SG_ 497 KY_HD_Zufahrt "Zufahrt HD nach erfolgreicher Funktion EasyClose";
CM_ SG_ 497 KY_HDF_Taste "HDF Taste am Funkschluessel";
CM_ SG_ 497 KY_HFS_Entriegelung_Autorisiert "Erkennung / Authorisierung Keyless HFS
";
CM_ SG_ 497 KY_HFS_Verriegelung_Autorisiert "Authorisierung Verriegelungssensor Keyless HFS

";
CM_ SG_ 497 KY_IDG_in_Reichweite "Für elektrisch betätigte Türen und Klappen muss für eine Betätigung über Funk eine Reichweitenbegrenzung eingeführt werden. Diese Bit zeigt an, dass sich der Funkschlüssel innerhalb der geforderten Reichweite befindet";
CM_ SG_ 497 KY_LKL_1_Autorisierung "Schlüsselstatus für Anfragen der Ladeklappe 1";
CM_ SG_ 497 KY_LKL_2_Autorisierung "Schlüsselstatus für Anfragen der Ladeklappe 2";
CM_ SG_ 497 KY_Panik_Taste "Panik Taste Funkschluessel";
CM_ SG_ 497 KY_Position "Schlüsselposition für Funktionen Annäherungslicht, automatisches Entriegeln";
CM_ SG_ 497 KY_Schluessel_im_Fzg "Zeigt einen erkannten Schlüssel im Fzg an.";
CM_ SG_ 497 KY_Zu_Taste "Zu-Taste Funkschluessel";
CM_ SG_ 497 KY_ZV_Signatur "Signatur der ZV";
CM_ SG_ 497 Schluesselnr_Personalisierung "Signal gibt die jewels aktuelle Schlüsselnummer für die Personalisierung wieder";

CM_ SG_ 1424 FBS_Warn_Schluessel_Batt "Kombi Prio Warnung Schluessel Batterie
'Bitte Schlüsselbatterie wechseln!'";
CM_ SG_ 1424 KST_Wegstrecke_Challenge "Wegstreckenchallenge ans Kombi und ESC";
CM_ SG_ 1424 KY_FFB_Frequenz "Frequenz FFB";
CM_ SG_ 1424 KY_Fzg_Verlassen_erkannt "Fahrer/Schlüssel hat das Fahrzeug verlassen und FT wurde geschlossen";
CM_ SG_ 1424 KY_Fzg_Zugang_erkannt "Fahrer/Schlüssel hat Fahrzeug betreten und die FT geschlossen";
CM_ SG_ 1424 KY_HF_Aktiv "HF Funkempfang
";
CM_ SG_ 1424 KY_Indikator_Mehrere_Schluessel "Indikator für u.a. Sitzmemory, dass sich mehr als ein Schlüssel im Fahrzeug befinden.";
CM_ SG_ 1424 KY_Keyless_Go_Verbau "Verbauinfo Keyless Go
";
CM_ SG_ 1424 KY_Keyless_Verbau "Verbauinfo Keyless 
";
CM_ SG_ 1424 KY_KYL_Fahrer_Hinweise "Kombi Fahrer Hinweise Keyless";
CM_ SG_ 1424 KY_LF_Aktiv "LF Schluesselkommunikation
";
CM_ SG_ 1424 KY_NFC_Fahrer_Hinweise "Kombi Fahrer Hinweise Keyless / NFC";
CM_ SG_ 1424 KY_StartStopp_Info "Stopp-Freigabe und Start-Anforderung an den Start-Stopp-Koordinator";
CM_ SG_ 1424 KY_Transponder_aktiv "Notspule bzw, Nottransponder wird angesteuert";
CM_ SG_ 1424 KYL_Warn_kein_Schluessel "Kombi Prio Warnung Keyless 
'Schlüssel nicht im Fahrzeug!'
";
CM_ SG_ 1424 KYL_Warn_Kessy_defekt "Kombi Prio Warnung Keyless
'Keyless Go defekt, Zündschloß benutzen'";
CM_ SG_ 1424 KYL_Warn_Notzuendschloss "Aufforderung an den Benutzer, den Schlüsssel an die Notspule zu halten, wenn Kessy den Schlüssel nicht finden kann
'Keyless Go defekt. Zum Starten den Schlüssel vor das Symbol halten!'";

CM_ SG_ 960 BCM_Ausparken_Betrieb "Anforderung zur erneuten Lampenaufprüfung und Anzeige von Warnhinweisen nach einem pilotierten Ausparkvorgang (Trigger: fallende Flanke)";
CM_ SG_ 960 BCM_Remotestart_Betrieb "Zeigt den Status des RemoteStarts an, d.h. KL15_RSt ist aktiviert und der Motorlauf ist im RSt-Betrieb aktiv.";
CM_ SG_ 960 BCM_Remotestart_KL15_Anf "Zeigt den Status der Aktivierung der KL15_RST durch das BCM an.";
CM_ SG_ 960 BCM_Remotestart_MO_Start "Nachdem das BCM die Remotestart MSG Freigabe sicher erkannt hat, fordert das BCM wiederum über dieses Signal vom MSG einen Motorstart durchzuführen.";
CM_ SG_ 960 Klemmen_Status_01_BZ "4bit Botschaftszaehler; wird in jeder Sendebotschaft inkrementiert";
CM_ SG_ 960 Klemmen_Status_01_CRC "Für MLB:
'Berechnung siehe Lastenheft 'Kommunikationsabsicherung für FlexRay und CAN''

Ab MQB und MLBevo:
'Berechnung siehe Lastenheft 'End-to-End Kommunikationsabsicherung''

Endwerte siehe Begleitdokument 'S-PDU Kennungsfolgen'";
CM_ SG_ 960 KST_Fahrerhinweis_1 "Signalisierung Fahrerhinweis 1 der Klemmensteuerung an das Kombi";
CM_ SG_ 960 KST_Fahrerhinweis_2 "Signalisierung Fahrerhinweis 2 der Klemmensteuerung an das Kombi";
CM_ SG_ 960 KST_Fahrerhinweis_4 "Signalisierung Fahrerhinweis 4 der Klemmensteuerung an das Kombi";
CM_ SG_ 960 KST_Fahrerhinweis_5 "Anzeigesignal für RemoteStart";
CM_ SG_ 960 KST_Fahrerhinweis_6 "Signal aktiviert die Kombi-Anzeigeinstrumente (Drehzahl, Tankinhalt, Kühlmitteltemperatur) während aktiviertem RemoteStart-Betrieb";
CM_ SG_ 960 KST_Warn_P1_ZST_def "Kombi Prio Warnung Klemmensteuerung 
Zündschloß defekt, Service aufsuchen!";
CM_ SG_ 960 KST_Warn_P2_ZST_def "Kombi Prio Warnung Klemmensteuerung
Zündschloß defekt!
";
CM_ SG_ 960 RSt_Fahrerhinweise "Über das Signal fordert das BCM Fahrerhinweise im Kombi für die Funktion RemoteStart an.";
CM_ SG_ 960 ZAS_Kl_15 "Klemme 15: Zuendung (SW-Kl.15)
";
CM_ SG_ 960 ZAS_Kl_50_Startanforderung "Klemme 50: Startwunsch Fahrer
";
CM_ SG_ 960 ZAS_Kl_Infotainment "Separate Klemmeninformation für das Infotainment. Signal entspricht im wesentlichen einer Klemme S Information, kann aber über einen Vor - bzw. Nachlauf zu Klemme S verfügen. 
Ein konkreter Anwendungsfall für einen Nachlauf ist die Abschaltung der Klemme";
CM_ SG_ 960 ZAS_Kl_S "Klemme S: S-Kontakt (Schluessel steckt)
";
CM_ SG_ 960 ZAS_Kl_X "Klemme 75
";

CM_ SG_ 1420 Klemmen_Steuerung_01_BZ "4bit Botschaftszaehler; wird in jeder Sendebotschaft inkrementiert";
CM_ SG_ 1420 Klemmen_Steuerung_01_CRC "Ab MQB und MLBevo:
'Berechnung siehe Lastenheft 'End-to-End Kommunikationsabsicherung''

Endwerte siehe Begleitdokument 'S-PDU Kennungsfolgen'";
CM_ SG_ 1420 KST_Anf_Klemmenfreigabe_ELV "Klemmensteuerung fordert Klemmen-Freigabe durch die ELV an.";
CM_ SG_ 1420 KST_Anf_ZV_Verriegelung "Neuer Verriegelungstrigger für die ZV nach der automatischen Klemmenabschaltung.

Wird bei Kessyfahrzeugen mit StartStop ein aktiver Stop-Mode und Fahrerverlassen erkannt, startet ein 30 Sekunden-Timer. Innerhalb dieser 30 Sekunden hat der Fahrer die Mö";
CM_ SG_ 1420 KST_aut_Abschaltung_Zuendung "Falls bei eingeschalteter Zündung das Abblendlicht aktiv war, muss nach der automatischen Abschaltung der Kl_15 & Kl_S, dass Standlicht aktiv bleiben. Das Signal sendet die Information, dass eine automatische Abschaltung der Kl_15 und Kl_S erfogt.";
CM_ SG_ 1420 KST_Txt_Komfortabschaltung "Dieses Signal fordert im Kombi die Meldung an, die den Fahrer über die ausgeführte automatische Zündungsabschaltung informiert. Signal wird für10s gesendet.";
CM_ SG_ 1420 KST_Txt_P_Gang "Text: 'Wählhebel in Position P bringen!'";
CM_ SG_ 1420 KST_Txt_Panikabschaltung "Text: 'Notabschaltung''";
CM_ SG_ 1420 KST_Unterdr_Zuendungsmeldung "Bei aktivem Signal soll die Zündungsmeldung durch das Kombi unterdrückt werden.";
CM_ SG_ 1420 KST_ZAT_betaetigt "Zündanlass-Taster (ZAT) betätigt";
CM_ SG_ 1420 Relais_VoKo_angesteuert "Signal zur Rückmeldung, ob das Relais für die Verbraucher von erweiterte Voko / RemoteStart angesteuert wird.";
CM_ SG_ 1420 RSt_Anforderung_HMS "Anforderung vom RSt (Remote Start) an das HMS (Haltemanagement System)";

CM_ SG_ 1646 KL_Anf_AussenspiegelHzg "Anforderung Außenspiegelheizung seitens Klimafunktion (z.B. bei Erweiterter VoKo)";
CM_ SG_ 1646 KL_BCmE_Livetip_Freigabe "Status der Klimaanlage. 
Zeigt an, ob der Livetip 'Fenster schließen wegen Ineffizienz Klimaanlage' sinvollerweise angezeigt werden soll";
CM_ SG_ 1646 KL_ErwVK_Anf "Erweiterte Voko angefordertert / aktiv";
CM_ SG_ 1646 KL_ErwVK_Zusatzrelais "Steuerung Zusatzrelais für Erweiterte Voko";
CM_ SG_ 1646 KL_FSH_Automatikbetrieb "Ermöglicht eine Unterscheidung von Anforderung FSH durch Kundenwunsch und Anforderung FSH durch Regelung des Klimasteuergeräts.
Das Signal liegt als Pegel an.";
CM_ SG_ 1646 KL_Geblaese_Fond_Status "Status Geblaese









";
CM_ SG_ 1646 KL_Geblaese_Status "Status Geblaese









";
CM_ SG_ 1646 KL_Heizkreisventilstellung "Bei MQB PHEV: Stellung Heizkreisventil Motor";
CM_ SG_ 1646 KL_HYB_ASV_hinten_schliessen_Anf "Anforderung der Klima an das BMS, das Absperrventil des Kältemittelkreislaufs zur Batteriekühlung zu schliessen";
CM_ SG_ 1646 KL_HYB_ASV_vorne_schliessen_Anf "Anforderung der Klima an das BMS, das Absperrventil des Kältemittelkreislaufs der Klimaanlage zu schliessen";
CM_ SG_ 1646 KL_I_Geblaese_Fond "Stromaufnahme Gebläse Heck";
CM_ SG_ 1646 KL_Innen_Temp "Innentemperatur

";
CM_ SG_ 1646 KL_Kompressorkupplung "Signal zur Aktivierung/Deaktivierung der Kompressorkupplung";
CM_ SG_ 1646 KL_Magnetventil "Anforderung des Bypassventils.";
CM_ SG_ 1646 KL_Restwaerme_aktiv "Signal zur Aktivierung/Deaktivierung der Wasserpumpe bei Restwärme; 
reduzierte IRÜ Empfindlichkeit";
CM_ SG_ 1646 KL_SIH_LEH_Verteilung_VL "Vom Kunden eingestellte Aufteilung der Heizleistung auf Sitzfläche und Lehnefläche für Sitz vorne links";
CM_ SG_ 1646 KL_SIH_LEH_Verteilung_VR "Vom Kunden eingestellte Aufteilung der Heizleistung auf Sitzfläche und Lehnefläche für Sitz vorne rechts";
CM_ SG_ 1646 KL_SIH_LEL_Verteilung_VL "Vom Kunden eingestellte Aufteilung der Lüftungsleistung auf Sitzfläche und Lehnenfläche für Sitz vorne links";
CM_ SG_ 1646 KL_SIH_LEL_Verteilung_VR "Vom Kunden eingestellte Aufteilung der Lüftungsleistung auf Sitzfläche und Lehnenfläche für Sitz vorne rechts";
CM_ SG_ 1646 KL_Solarluefter_aktiv "Betriebsstatus Solarluefter
";
CM_ SG_ 1646 KL_Status_Beduftung "Status der Beduftung";
CM_ SG_ 1646 KL_Status_Ionisator_Front "Status des Ionisator Front";
CM_ SG_ 1646 KL_STH_aktiv "Betriebsstatus Standheizung
";
CM_ SG_ 1646 KL_STH_Ansteuerung "Ansteuerung STH

";
CM_ SG_ 1646 KL_STH_Betriebsdauer "Betriebsdauer STH";
CM_ SG_ 1646 KL_STH_Timer_Status "Status des Standheizungstimers (für VW621 initial zur Übermittelung der Information von KlimaMSB zu Kombi)
Zur Anzeige im Kombi für 10 Sekunden nach Kl.15 aus;";
CM_ SG_ 1646 KL_STL_aktiv "Betriebsstatus Standlueftung
";
CM_ SG_ 1646 KL_Umluft_Taste "Betaetigung Umlufttaste
";
CM_ SG_ 1646 KL_WaPu "Ansteuerung der Standheizungswasserpumpe";

CM_ SG_ 1663 KL_Absperrventil_Fond "nur im D4 verwendet";
CM_ SG_ 1663 KL_Fond_li_reduziert "Vorhalt fuer VW, nicht B8";
CM_ SG_ 1663 KL_Fond_re_reduziert "Vorhalt fuer VW, nicht B8";
CM_ SG_ 1663 KL_Fondbed_vorne_aktiv "Fondbedienung von vorne
Im D4 nicht unterstützt    siehe Klima_07, Synchronisierunganforderung
";
CM_ SG_ 1663 KL_Gebl_Verst_Abs_Modus "Gebläseverstellung im Absolutmodus";
CM_ SG_ 1663 KL_Geblaesespg_Fond "Geläsespannung Fond";
CM_ SG_ 1663 KL_Heizverbraucher_aus "Signal ans Fondgerät, alle Heizverbraucher zu deaktivieren";
CM_ SG_ 1663 KL_Heizverbraucher_Notaus "Signal ans Fondgerät, alle Heizverbraucher zu deaktivieren";
CM_ SG_ 1663 KL_ICO2_Sensor_defekt "Funktionszustand vom CO2 Sensor";
CM_ SG_ 1663 KL_Mod_Display_li "Modus des Display links";
CM_ SG_ 1663 KL_Mod_Display_re "Modus des Display rechts
";
CM_ SG_ 1663 KL_SH_HL_Lastabschaltung "Abschaltung der Sitzheizung hinten links wegen BEM, auch Taktung möglich
";
CM_ SG_ 1663 KL_SH_HR_Lastabschaltung "Abschaltung der Sitzheizung hinten rechts wegen BEM, auch Taktung möglich
";
CM_ SG_ 1663 KL_Sollausblastemp_HL "Sollausblastemperatur hinten links (0°C .. 85°C)

Vorhalt";
CM_ SG_ 1663 KL_Sollausblastemp_HR "Sollausblastemperatur hinten rechts (0°C .. 85°C)

Vorhalt";
CM_ SG_ 1663 KL_Umluft "Sollwert für Umluftklappe Fondraum";

CM_ SG_ 1608 KL_Befehlszaehler_FH "Befehlszähler zur Synchronisation Front & Fond";
CM_ SG_ 1608 KL_Luftmenge_HL_max "Vorgabe der maximal auswählbaren Gebläsestufe für Zone HL";
CM_ SG_ 1608 KL_Luftmenge_HL_offset "Abweichung der Gebläsespannung bei manueller Gebläsevorgabe zum Arbeitspunkt im Auto-Modus für Zone HL";
CM_ SG_ 1608 KL_Luftmenge_HL_Soll "Sollwertvorgabe für Luftmenge hinten links";
CM_ SG_ 1608 KL_Luftmenge_HR_max "Vorgabe der maximal auswählbaren Gebläsestufe für Zone HR";
CM_ SG_ 1608 KL_Luftmenge_HR_offset "Abweichung der Gebläsespannung bei manueller Gebläsevorgabe zum Arbeitspunkt im Auto-Modus für Zone HR";
CM_ SG_ 1608 KL_Luftmenge_HR_Soll "Sollwertvorgabe für Luftmenge hinten rechts";
CM_ SG_ 1608 KL_SH_HL_Soll "Sollwertvorgabe für Sitzheizung hinten links";
CM_ SG_ 1608 KL_SH_HR_Soll "Sollwertvorgabe für Sitzheizung hinten rechts";
CM_ SG_ 1608 KL_SL_HL_Soll "Sollwertvorgabe für Sitzlüftung hinten links";
CM_ SG_ 1608 KL_SL_HR_Soll "Sollwertvorgabe für Sitzlüftung hinten rechts";
CM_ SG_ 1608 KL_Temp_HL_Soll "Audi  bis   28°C
VW    bis   29,5°C";
CM_ SG_ 1608 KL_Temp_HR_Soll "Audi  bis   28°C
VW    bis   29,5°C";

CM_ SG_ 949 KL_AC_Schalter "AC Schalter
";
CM_ SG_ 949 KL_Anf_KL "Anforderung Kühlerlüfter der Klimaanlage in Prozent

";
CM_ SG_ 949 KL_Ausstattung_Klima "Austtattungsart der Klimabedienung";
CM_ SG_ 949 KL_Charisma_FahrPr "MLBevo: Aktuelles Fahrprogramm des Charisma-Teilnehmers (siehe Systemlastenheft Drive Select)
MQB: Istwert der Kennlinie (siehe Systemlastenheft MQB FPA)";
CM_ SG_ 949 KL_Charisma_Status "Charisma Systemstatus des Charisma-Teilnehmers

Wert 0x3 ist nur für Fahrzeuge ab MQB relevant";
CM_ SG_ 949 KL_Drehz_Anh "Drehzahlanhebung vom Motor angefordert

";
CM_ SG_ 949 KL_el_Zuheizer_Stufe "Vorgabe für Motorsteuergeraet PTC-Stufe; im MLB-B8 und MQB nur Stufe 0...3

";
CM_ SG_ 949 KL_Freilauf_Info "Freilauf Informationssignal von Klima zum Freilaufkoordinator. Klima kann über dieses Signal den Freilauf freigeben, verhindern bzw. explizit anfordern.";
CM_ SG_ 949 KL_Kompressorkupplung_linear "Sollwert zur Ansteuerung der Kompressorkupplung";
CM_ SG_ 949 KL_Last_Kompr "Aktuelles Verlustmoment der Klimaanlage bezogen auf die Kurbelwelle. Wird der Klimakompressor nicht angesteuert, ist das Schleppmoment bezogen auf die Kurbelwelle zu senden.";
CM_ SG_ 949 KL_nachtr_Stopp_Anf "Dieses Signal dient dem Motor als Trigger, dass ein nachträglicher Motorstopp eingeleitet werden kann, wenn es die Bedingungen des StSt Koordinators dies zulassen. ";
CM_ SG_ 949 KL_Spannungs_Anf "Forderung des Klima-SG's zur Spannungsanhebung.";
CM_ SG_ 949 KL_StartStopp_Info "Stopp-Freigabe und Start-Anforderung an den Start-Stopp-Koordinator";
CM_ SG_ 949 KL_T_Charge "Signal für Tastenbetätigung Charge-Taste (SOC Increasing)";
CM_ SG_ 949 KL_Thermomanagement "Stufen des Thermomanagements;
Bei Klemme 15 AUS und erkannten Timeout zum Klimabedienteil (z.B. Klimabedienteil während des Motorsteuergeräte-Kommunikations-Nachlaufs bereits im NM-Zustand ¿Bus Sleep¿)
erfolgt keine Ansteuerung der Wasserpumpe durch die";
CM_ SG_ 949 KL_Variante_Standheizung "Identifikation der Variante der Standheizungen zur Berechnung der energetischen Zielzeit";
CM_ SG_ 949 KL_Vorwarn_Komp_ein "Vorwarnung Kompressor ein; 140ms vorher; Information für Motor zum Aufbau Momentenreserve";
CM_ SG_ 949 KL_Vorwarn_Zuheizer_ein "Vorwarnung Zuheizerbetrieb
";
CM_ SG_ 949 KL_Zustand "Beschreibt den Zustand des Klima-/Heizungsbedienteils. (OFF-Mode Bedienteil)

PAG (MLB): Beschreibt den Zustand des Kompressors";

CM_ SG_ 1640 FSH_Taster "Tasterbetätigung Frontscheibenheizung
";
CM_ SG_ 1640 HSH_Taster "An-/Abforderung Heckscheibenheizung über spezielles Tastersignal
";
CM_ SG_ 1640 KL_Beschlagsgefahr "Beschlagsgefahr auf der Frontscheibe im Bereich des Spiegelfusses. Dient zur präventiven Ansteuerung der  Kamera-Scheibenheizung, um Kamera-Blindheit zu vermeiden
PHEV: volle Leistungsfreigabe 
HV Heizer und HV EKK bei Scheibenbeschlag ";
CM_ SG_ 1640 KL_Geblspng_Fond_Soll "Ausgabe des Sollwertes für die Spannung des Klimagebläsemotores hinten.






";
CM_ SG_ 1640 KL_Geblspng_Soll "Ausgabe des Sollwertes für die Spannung des Klimagebläsemotores vorne.







";
CM_ SG_ 1640 KL_I_Geblaese "Stromaufnahme Gebläse";
CM_ SG_ 1640 KL_Kompressorstrom_soll "Sollvorgabe Klima-Kompressorstrom";
CM_ SG_ 1640 KL_LRH_Stufe "Eingestellte Temperaturstufe der Lenkradheizung";
CM_ SG_ 1640 KL_LRH_Taster "Tasterbetätigung Lenkradheizung";
CM_ SG_ 1640 KL_PTC_Verbauinfo "Im Klima- bzw. Heizungsbedienteil wird der Verbau eines PTCs und dessen elektr. Leistungsklasse codiert";
CM_ SG_ 1640 KL_SIH_Soll_li "Einstellung Sitzheizung Fahrer (0...6)";
CM_ SG_ 1640 KL_SIH_Soll_re "Einstellung Sitzheizung Beifahrer (0...6)";
CM_ SG_ 1640 KL_SIL_Soll_li "Einstellung Sitzlüftung Fahrer (0...6)";
CM_ SG_ 1640 KL_SIL_Soll_re "Einstellung Sitzlüftung Beifahrer (0...6)";
CM_ SG_ 1640 KL_Umluftklappe_Status "Status Umluftklappe";
CM_ SG_ 1640 KL_Zuheizer_Freigabe "Freigabe Zuheizer
";
CM_ SG_ 1640 KRH_Soll_li "Ausgabe des Sollwertes für die Kopfraumheizung links.";
CM_ SG_ 1640 KRH_Soll_re "Ausgabe des Sollwertes für die Kopfraumheizung rechts.";

CM_ SG_ 1441 KL_Frischluftklappe_Status "Aktuelle Position der Frischluftklappe";
CM_ SG_ 1441 KL_PTC_linear_Anf "Kundenanforderung des PTC (linear)";
CM_ SG_ 1441 KL_SIH_LEH_Verteilung_HL "Vom Kunden eingestellte Aufteilung der Heizleistung auf Sitz und Lehne für Sitz hinten links";
CM_ SG_ 1441 KL_SIH_LEH_Verteilung_HR "Vom Kunden eingestellte Aufteilung der Heizleistung auf Sitz und Lehne für Sitz hinten rechts.";
CM_ SG_ 1441 KL_SIH_Stufe_hl "Eingestellte Sitzheizungsstufe hinten links für verteilte Komfortfunktionen";
CM_ SG_ 1441 KL_SIH_Stufe_hr "Eingestellte Sitzheizungsstufe hinten rechts für verteilte Komfortfunktionen";
CM_ SG_ 1441 KL_SIL_LEL_Verteilung_HL "Vom Kunden eingestellte Aufteilung der Lüftungsleistung auf Sitzfläche und Lehnenfläche für Sitz hinten links";
CM_ SG_ 1441 KL_SIL_LEL_Verteilung_HR "Vom Kunden eingestellte Aufteilung der Lüftungsleistung auf Sitzfläche und Lehnenfläche für Sitz hinten rechts";
CM_ SG_ 1441 KL_SIL_Stufe_hl "Eingestellte Sitzlüftungsstufe hinten links für verteilte Komfortfunktionen";
CM_ SG_ 1441 KL_SIL_Stufe_hr "Eingestellte Sitzlüftungsstufe hinten rechts für verteilte Komfortfunktionen";
CM_ SG_ 1441 KL_Temp_Soll_hl "Eingestellte Solltemperatur hinten links für verteilte Komfortfunktionen";
CM_ SG_ 1441 KL_Temp_Soll_hr "Eingestellte Solltemperatur hinten rechts für verteilte Komfortfunktionen";
CM_ SG_ 1441 KL_Temp_Soll_vl "Eingestellte Solltemperatur vorne links für verteilte Komfortfunktionen";
CM_ SG_ 1441 KL_Temp_Soll_vr "Eingestellte Solltemperatur vorne rechts für verteilte Komfortfunktionen";

CM_ SG_ 2589283621 KL_ACmax_Aktiv "Funktion ACmax durch Kundeneingriff aktiviert";
CM_ SG_ 2589283621 KL_Defrost_Aktiv "Funktion Defrost durch Kundeneingriff aktiviert";
CM_ SG_ 2589283621 KL_ECO_Aktiv "Funktion Eco durch Kundeneingriff aktiviert";
CM_ SG_ 2589283621 KL_ECO_PRO_Aktiv "Funktion ECO-PRO durch Kundeneingriff aktiviert";
CM_ SG_ 2589283621 KL_Eps_Innen "mittlerer Wert der Klima Regelabweichung";
CM_ SG_ 2589283621 KL_FlHz_Soll_HL "Sollwertvorgabe für Flächenheizung hinten links";
CM_ SG_ 2589283621 KL_FlHz_Soll_HR "Sollwertvorgabe für Flächenheizung hinten rechts";
CM_ SG_ 2589283621 KL_FlHz_Soll_VL "Sollwertvorgabe für Flächenheizung vorne links";
CM_ SG_ 2589283621 KL_FlHz_Soll_VR "Sollwertvorgabe für Flächenheizung vorne rechts";
CM_ SG_ 2589283621 KL_Kundeneingriff_Geblaese "Manueller Kundeneingriff in die Geblaeseregelung";
CM_ SG_ 2589283621 KL_NV_Energie_Anf "Benötigte Energie (12V) für die Erweiterte Vorkonditionierung";
CM_ SG_ 2589283621 KL_QBit_Sonnenintensitaet "Gültigkeitsbit für Signal KL_Sonenintensität
Gesetzt bei Ersatzwert, Init oder Fehler.";
CM_ SG_ 2589283621 KL_Sonnenintensitaet "gemittelte eingestrahlte Leistung in W/m2";
CM_ SG_ 2589283621 KL_Status_Klimastil "Signal für aktuelles Programm des KBT";
CM_ SG_ 2589283621 KL_Thermischer_Bedarf "Temperierungsbedarf zur Innenraumklimatisierung";
CM_ SG_ 2589283621 KL_Umluft_Connect_status "Umluft Status zum Backend Server";
CM_ SG_ 2589283621 KL_ZR_Anforderung "Anforderung an MIB die Displays zu aktivieren";

CM_ SG_ 992 KL_Fehler_Fussraum_Klappen "Fehler in den Fußraumklappen werden gemeldet";
CM_ SG_ 992 KL_Fehler_Temp_Klappen "Fehler in den Temperaturklappen werden gemeldet";
CM_ SG_ 992 KL_Fehler_Temp_MA_Klappen "Fehler in den MA-Klappen werden gemeldet";
CM_ SG_ 992 KL_Fehler_Umluft "Status Umluftklappe";
CM_ SG_ 992 KL_Fond_Absperrventil "Absperrventil";
CM_ SG_ 992 KL_Fond_Fuss_Temp_hl "Fussraumtemperatur hinten links";
CM_ SG_ 992 KL_Fond_Fuss_Temp_hr "Fussraumtemperatur hinten rechts";
CM_ SG_ 992 KL_Fond_KD_Fehler "Status Kundendienstfehlerspeichereinträge

";
CM_ SG_ 992 KL_MA_Temp_hl "Mannanstroemer hinten links Temperatur";
CM_ SG_ 992 KL_MA_Temp_hr "Mannanstroemer hinten rechts Temperatur";
CM_ SG_ 992 KL_RAB "Risiko-Abschätzungs- und Bewertungs-Bit";
CM_ SG_ 992 KL_SH_Soll_hl "Einstellung Sitzheizung hinten links (0...6)";
CM_ SG_ 992 KL_SH_Soll_hr "Einstellung Sitzheizung hinten rechts (0...6)";
CM_ SG_ 992 KL_SIH_Takt_hl "Ein-Aus Taktung Sitzheizung hinten links";
CM_ SG_ 992 KL_SIH_Takt_hr "Ein-Aus Taktung Sitzheizung hinten rechts";
CM_ SG_ 992 KL_SL_Soll_hl "Einstellung Sitzlüftung hinten links (0...6)";
CM_ SG_ 992 KL_SL_Soll_hr "Einstellung Sitzlüftung hinten rechts (0...6)";

CM_ SG_ 1712 FS_ResponseError "siehe LIN2.0-Specification
(Darf nicht über ein Fehlergueltigkeitsbit abgesichtert werden!)";

CM_ SG_ 1505 BCM1_Aussen_Temp_ungef "ungefilterter Wert des Aussentemperatursensors
";
CM_ SG_ 1505 BCM1_FStatus_Aussentemp_ungef "Fehlerstatus für Aussentemperatur (Kombianzeige)";
CM_ SG_ 1505 BCM1_Kompressorstrom_ist "IST-Strom vom Klima-Kompressor";
CM_ SG_ 1505 BCM1_OBD_FStatus_ATemp "Fehlerstatus Umgebungstemperatursensor (OBD relevanter Sensor)
";
CM_ SG_ 1505 BCM1_PTC_stufig_Status "Status des BCM1-Heizverbrauchers PTC (stufig)";
CM_ SG_ 1505 BCM_Heizungsabsperrventil_Status "Das Signal beschreibt den Zustand des Heizungsabsperrventils, welches als Portexpander vom BCM1 elektrisch angesteuert wird.";
CM_ SG_ 1505 BCM_Heizungspumpe_Status "Das Signal beschreibt den Zustand der Heizungspumpe, welche als Portexpander vom BCM1 elektrisch angesteuert wird.";
CM_ SG_ 1505 BCM_Kompressorkupplung_Status "Das Signal beschreibt den Zustand der Klimakompressorkupplung, welche als Portexpander vom BCM1 elektrisch angesteuert wird.";

CM_ SG_ 605 KLR_01_BZ "Botschaftszähler
Botschaft asynchron geroutet. Zählerwert kann springen.";
CM_ SG_ 605 KLR_01_CRC "'Berechnung siehe Lastenheft 'End-to-End Kommunikationsabsicherung''

Endwerte siehe Begleitdokument 'S-PDU Kennungsfolgen'";
CM_ SG_ 605 KLR_Fehler "Fehler im KLR System";
CM_ SG_ 605 KLR_Fehler_Codierung "Erkennung eines Fehlers in der Codierung der Datensatzauswahl im KLR";
CM_ SG_ 605 KLR_Lokalaktiv "Zeigt an ob das SG nach Klemme15 AUS und nach entsprechender MAX Aktivzeit noch aktiv war";
CM_ SG_ 605 KLR_ResponseError "siehe LIN2.0-Specification
(Darf nicht über ein Fehlergueltigkeitsbit abgesichtert werden!)";
CM_ SG_ 605 KLR_Touchauswertung "Touchauswertung der KLR-Elektronik";
CM_ SG_ 605 KLR_Touchintensitaet_1 "Diskreter Wert der Touchintensität von 0 bis 250 für Sensor 1";
CM_ SG_ 605 KLR_Touchintensitaet_2 "Diskreter Wert der Touchintensität von 0 bis 250 für Sensor 2";
CM_ SG_ 605 KLR_Touchintensitaet_3 "Diskreter Wert der Touchintensität von 0 bis 250 für Sensor 3";

CM_ SG_ 2549088398 BedienDisp_vo_Abschaltstufe "Funktionseinschränkung aufgrund aktiver Abschaltstufe";
CM_ SG_ 2549088398 BedienDisp_vo_KD_Fehler "Status Kundendienstfehlerspeichereinträge";
CM_ SG_ 2549088398 BedienDisp_vo_KompSchutz "Funktionseinschränkung aufgrund Komponentenschutz aktiv";
CM_ SG_ 2549088398 BedienDisp_vo_Nachlauftyp "Abgebildet wird die von der Hardware vorgegebene Möglichkeit, die Kommunikation nach Klemme 15 = AUS aufrecht zu erhalten. Es wird ein Init-Wert gesendet.
0 = Kommunikation nur bei KL15=EIN (kein Nachlauf, nicht weckfähig)
1 = Kommunikation nach KL15=AU";
CM_ SG_ 2549088398 BedienDisp_vo_SNI "Das Signal beinhaltet den Source Node Identifier (Knotenadresse, die auch in der Abbildungsvorschrift zur CAN-ID für die NM-High Botschaft verwendet wird).";
CM_ SG_ 2549088398 BedienDisp_vo_Transport_Mode "Funktionseinschränkung aufgrund aktivem Transport Mode und/oder Transport Schutz";
CM_ SG_ 2549088398 KN_BedienDisp_v_BusKnockOut "Ausgabe des BusKnockout-Status in der Knotenbotschaft";
CM_ SG_ 2549088398 KN_BedienDisp_v_BusKnockOutTimer "Ausgabe des BusKnockOut-Timer in der Knotenbotschaft";
CM_ SG_ 2549088398 KN_BedienDisp_v_ECUKnockOut "Ausgabe des ECUKnockout-Status in der Knotenbotschaft";
CM_ SG_ 2549088398 KN_BedienDisp_v_ECUKnockOutTimer "Ausgabe des ECUKnockOut-Timer in der Knotenbotschaft";
CM_ SG_ 2549088398 NM_BedienDisp_vo_Wakeup "enthält die Weckursache; stehen mehrere Weckursachen parallel an, dann muss der kleinste Wert übertragen werden";
CM_ SG_ 2549088398 NMH_BedienDisp_vo_Lokalaktiv "Zeigt an ob das SG nach Klemme15 AUS und nach entsprechender MAX Aktivzeit noch aktiv war";
CM_ SG_ 2549088398 NMH_BedienDisp_vo_Subsystemaktiv "Zeigt an ob ein Subsystem des SGs nach Klemme15 AUS und nach entsprechender MAX Aktivzeit noch aktiv war";

CM_ SG_ 2549088403 BedienSG_hi_Abschaltstufe "Funktionseinschränkung aufgrund aktiver Abschaltstufe";
CM_ SG_ 2549088403 BedienSG_hi_KD_Fehler "Status Kundendienstfehlerspeichereinträge";
CM_ SG_ 2549088403 BedienSG_hi_KompSchutz "Funktionseinschränkung aufgrund Komponentenschutz aktiv";
CM_ SG_ 2549088403 BedienSG_hi_Nachlauftyp "Abgebildet wird die von der Hardware vorgegebene Möglichkeit, die Kommunikation nach Klemme 15 = AUS aufrecht zu erhalten. Es wird ein Init-Wert gesendet.
0 = Kommunikation nur bei KL15=EIN (kein Nachlauf, nicht weckfähig)
1 = Kommunikation nach KL15=AU";
CM_ SG_ 2549088403 BedienSG_hi_SNI "Das Signal beinhaltet den Source Node Identifier (Knotenadresse, die auch in der Abbildungsvorschrift zur CAN-ID für die NM-High Botschaft verwendet wird).";
CM_ SG_ 2549088403 BedienSG_hi_Transport_Mode "Funktionseinschränkung aufgrund aktivem Transport Mode und/oder Transport Schutz";
CM_ SG_ 2549088403 KN_BedienSG_hi_BusKnockOut "Ausgabe des BusKnockout-Status in der Knotenbotschaft";
CM_ SG_ 2549088403 KN_BedienSG_hi_BusKnockOutTimer "Ausgabe des BusKnockOut-Timer in der Knotenbotschaft";
CM_ SG_ 2549088403 KN_BedienSG_hi_ECUKnockOut "Ausgabe des ECUKnockout-Status in der Knotenbotschaft";
CM_ SG_ 2549088403 KN_BedienSG_hi_ECUKnockOutTimer "Ausgabe des ECUKnockOut-Timer in der Knotenbotschaft";
CM_ SG_ 2549088403 NMH_BedienSG_hi_Lokalaktiv "Zeigt an ob das SG nach Klemme15 AUS und nach entsprechender MAX Aktivzeit noch aktiv war";
CM_ SG_ 2549088403 NMH_BedienSG_hi_Subsystemaktiv "Zeigt an ob ein Subsystem des SGs nach Klemme15 AUS und nach entsprechender MAX Aktivzeit noch aktiv war";
CM_ SG_ 2549088403 NMH_BedienSG_hi_Wakeup "enthält die Weckursache; stehen mehrere Weckursachen parallel an, dann muss der kleinste Wert übertragen werden";

CM_ SG_ 2549088442 DDA_Abschaltstufe "Funktionseinschränkung aufgrund aktiver Abschaltstufe";
CM_ SG_ 2549088442 DDA_KD_Fehler "Bei gesetztem Bit ist mindestens ein Kundendienstfehler eingetragen";
CM_ SG_ 2549088442 DDA_KompSchutz "Funktionseinschränkung aufgrund Komponentenschutz aktiv";
CM_ SG_ 2549088442 DDA_Nachlauftyp "Abgebildet wird die von der Hardware vorgegebene Möglichkeit, die Kommunikation nach Klemme 15 = AUS aufrecht zu erhalten. Es wird ein Init-Wert gesendet.
0 = Kommunikation nur bei KL15=EIN (kein Nachlauf, nicht weckfähig)
1 = Kommunikation nach KL15=AU";
CM_ SG_ 2549088442 DDA_SNI "Das Signal beinhaltet den Source Node Identifier (Knotenadresse, die auch in der Abbildungsvorschrift zur CAN-ID für die NM-High Botschaft verwendet wird).";
CM_ SG_ 2549088442 DDA_Transport_Mode "Funktionseinschränkung aufgrund aktivem Transport Mode und/oder Transport Schutz";
CM_ SG_ 2549088442 KN_DDA_BusKnockOutTimer "Ausgabe des BusKnockOut-Timer in der Knotenbotschaft";
CM_ SG_ 2549088442 NM_DDA_Lokalaktiv "Zeigt an, ob das SG nach Klemme15 AUS noch aktiv war. LAH.DUM.907.T.1_Abschaltungen Ruhestrommgm MLBevo";
CM_ SG_ 2549088442 NM_DDA_Wakeup "enthält die Weckursache; stehen mehrere Weckursachen parallel an, dann muss der kleinste Wert übertragen werden";

CM_ SG_ 2549088272 Gateway_Abschaltstufe "Funktionseinschränkung aufgrund aktiver Abschaltstufe";
CM_ SG_ 2549088272 Gateway_KompSchutz "Funktionseinschränkung aufgrund Komponentenschutz aktiv";
CM_ SG_ 2549088272 Gateway_Matrix_Generation "Signal gibt an welche Matrix-Generation umgesetzt ist";
CM_ SG_ 2549088272 Gateway_Matrix_Version "Signal gibt an welche Matrix-Version des Baukasten umgesetzt ist.
z.B. V.08.xx, das Signal gibt den Wert für xx an";
CM_ SG_ 2549088272 Gateway_Nachlauftyp "Abgebildet wird die von der Hardware vorgegebene Möglichkeit, die Kommunikation nach Klemme 15 = AUS aufrecht zu erhalten. Es wird ein Init-Wert gesendet.";
CM_ SG_ 2549088272 Gateway_SNI "Das Signal beinhaltet den Source Node Identifier (Knotenadresse, die auch in der Abbildungsvorschrift zur CAN-ID für die NM-High Botschaft verwendet wird).";
CM_ SG_ 2549088272 Gateway_Transport_Mode "Funktionseinschränkung aufgrund aktivem Transport Mode und/oder Transport Schutz";
CM_ SG_ 2549088272 GW_KD_Fehler "Kundendienstfehlerbit Gateway zur Anzeige eines im Gateway abgelegten Fehlerspeichereintrages.";
CM_ SG_ 2549088272 NM_Gateway_Lokalaktiv "Zeigt an ob das SG nach Klemme15 AUS und nach entsprechender MAX Aktivzeit noch aktiv war.";
CM_ SG_ 2549088272 NM_Gateway_Subsystemaktiv "Zeigt an ob ein Subsystem des SGs nach Klemme15 AUS und nach entsprechender MAX Aktivzeit noch aktiv war";
CM_ SG_ 2549088272 NM_Gateway_Wakeup "enthält die Weckursache; stehen mehrere Weckursachen parallel an, dann muss der kleinste Wert übertragen werden";

CM_ SG_ 2549088355 GM_Abschaltstufe "Funktionseinschränkung aufgrund aktiver Abschaltstufe";
CM_ SG_ 2549088355 GM_KD_Fehler "Bei gesetztem Bit ist mindestens ein Kundendienstfehler eingetragen
";
CM_ SG_ 2549088355 GM_KompSchutz "Funktionseinschränkung aufgrund Komponentenschutz aktiv";
CM_ SG_ 2549088355 GM_Lokalaktiv "Zeigt an ob das SG nach Klemme15 AUS und nach entsprechender MAX Aktivzeit noch aktiv war";
CM_ SG_ 2549088355 GM_Nachlauftyp "Abgebildet wird die von der Hardware vorgegebene Möglichkeit, die Kommunikation nach Klemme 15 = AUS aufrecht zu erhalten. Es wird ein Init-Wert gesendet.
0 = Kommunikation nur bei KL15=EIN (kein Nachlauf, nicht weckfähig)
1 = Kommunikation nach KL15=AU";
CM_ SG_ 2549088355 GM_SNI "Das Signal beinhaltet den Source Node Identifier (Knotenadresse, die auch in der Abbildungsvorschrift zur CAN-ID für die NM-High Botschaft verwendet wird).";
CM_ SG_ 2549088355 GM_Subsystemaktiv "Zeigt an ob ein Subsystem des SGs nach Klemme15 AUS und nach entsprechender MAX Aktivzeit noch aktiv war";
CM_ SG_ 2549088355 GM_Transport_Mode "Funktionseinschränkung aufgrund aktivem Transport Mode und/oder Transport Schutz";
CM_ SG_ 2549088355 NM_GM_Wakeup "enthält die Weckursache; stehen mehrere Weckursachen parallel an, dann muss der kleinste Wert übertragen werden";

CM_ SG_ 2549088371 Info_El_Abschaltstufe "Funktionseinschränkung aufgrund aktiver Abschaltstufe";
CM_ SG_ 2549088371 Info_El_KD_Fehler "Bei gesetztem Bit ist mindestens ein Kundendienstfehler eingetragen";
CM_ SG_ 2549088371 Info_El_KompSchutz "Funktionseinschränkung aufgrund Komponentenschutz aktiv";
CM_ SG_ 2549088371 Info_El_Nachlauftyp "Abgebildet wird die von der Hardware vorgegebene Möglichkeit, die Kommunikation nach Klemme 15 = AUS aufrecht zu erhalten. Es wird ein Init-Wert gesendet.";
CM_ SG_ 2549088371 Info_El_SNI "Das Signal beinhaltet den Source Node Identifier (Knotenadresse, die auch in der Abbildungsvorschrift zur CAN-ID für die NM-High Botschaft verwendet wird).";
CM_ SG_ 2549088371 Info_El_Transport_Mode "Funktionseinschränkung aufgrund aktivem Transport Mode und/oder Transport Schutz";
CM_ SG_ 2549088371 KN_Info_El_BusKnockOutTimer "Ausgabe des BusKnockOut-Timer";
CM_ SG_ 2549088371 NM_Info_El_Lokalaktiv "Zeigt an ob das SG nach Klemme15 AUS und nach entsprechender MAX Aktivzeit noch aktiv war.";
CM_ SG_ 2549088371 NM_Info_El_Subsystemaktiv "Zeigt an ob ein Subsystem des SGs nach Klemme15 AUS und nach entsprechender MAX Aktivzeit noch aktiv war";
CM_ SG_ 2549088371 NM_Info_El_Wakeup "enthält die Weckursache; stehen mehrere Weckursachen parallel an, dann muss der kleinste Wert übertragen werden";

CM_ SG_ 2549088258 NM_Sekundaer_02_Lokalaktiv "Zeigt an ob das SG nach Klemme15 AUS und nach entsprechender MAX Aktivzeit noch aktiv war";
CM_ SG_ 2549088258 NM_Sekundaer_02_Subsystemaktiv "Zeigt an ob ein Subsystem des SGs nach Klemme15 AUS und nach entsprechender MAX Aktivzeit noch aktiv war";
CM_ SG_ 2549088258 NM_Sekundaer_02_Wakeup "enthält die Weckursache; stehen mehrere Weckursachen parallel an, dann muss der kleinste Wert übertragen werden";
CM_ SG_ 2549088258 Sekundaer_02_Abschaltstufe "Funktionseinschränkung aufgrund aktiver Abschaltstufe";
CM_ SG_ 2549088258 Sekundaer_02_KD_Fehler "Status Kundendienst-Fehlerspeicher";
CM_ SG_ 2549088258 Sekundaer_02_KompSchutz "Funktionseinschränkung aufgrund Komponentenschutz aktiv";
CM_ SG_ 2549088258 Sekundaer_02_Nachlauftyp "Abgebildet wird die von der Hardware vorgegebene Möglichkeit, die Kommunikation nach Klemme 15 = AUS aufrecht zu erhalten. Es wird ein Init-Wert gesendet.
0 = Kommunikation nur bei KL15=EIN (kein Nachlauf, nicht weckfähig)
1 = Kommunikation nach KL15=AU";
CM_ SG_ 2549088258 Sekundaer_02_SNI "Das Signal beinhaltet den Source Node Identifier (Knotenadresse, die auch in der Abbildungsvorschrift zur CAN-ID für die NM-High Botschaft verwendet wird).";
CM_ SG_ 2549088258 Sekundaer_02_Transport_Mode "Funktionseinschränkung aufgrund aktivem Transport Mode und/oder Transport Schutz";

CM_ SG_ 779 KBI_ABS_Lampe "ABS-Sicherheits-Lampe wurde eingeschaltet.";
CM_ SG_ 779 KBI_Airbag_Lampe "Airbag Sicherheits-Lampe wurde eingeschaltet ";
CM_ SG_ 779 KBI_angez_Geschw "Im Tacho angezeigte Geschwindigkeit inklusive der Voreilung

";
CM_ SG_ 779 KBI_Anzeigefehler_NV "Über dieses Signal teilt das Kombiinstrument dem Nightvision-Steuergerät mit, dass ein Fehler vom Kombiinstrument diagnostiziert wurde, der zur Abschaltung der Nightvision-Funktion führen muss.";
CM_ SG_ 779 KBI_Anzeigefehler_SWA "Signal bezieht sich nur auf die SWA-Lampe, Vorhalt für Kombis mit SWA-Lampe. ";
CM_ SG_ 779 KBI_Anzeigestatus_ACC "Status der ACC-Anzeige im nicht permanenten Displaybereich";
CM_ SG_ 779 KBI_Anzeigestatus_GRA "Anzeigestatus der GRA High Wunschgeschwindigkeitsanzeige im Kombiinstrument.
Bei VW bedeutet 'nicht vorhanden' GRA-low fähig (LED immer verbaut).
0 = nicht vorhanden
1 = Wunschgeschwindigkeits-Anzeigemöglichkeit vorhanden
2 = reserviert
3 = Fehler (B";
CM_ SG_ 779 KBI_Anzeigestatus_LIM "Anzeigestatus der Speedlimiter Wunschgeschwindigkeitsanzeige im Kombiinstrument (permanenter Anzeigebereich)
0 = nicht vorhanden
1 = Wunschgeschwindigkeits-Anzeigemöglichkeit vorhanden
2 = reserviert
3 = Fehler (Botschaftsüberwachung, Timeout, Akustik";
CM_ SG_ 779 KBI_ARA_in_Anzeige "Anzeige von ARA im Kombi aktiv";
CM_ SG_ 779 KBI_BKL_Lampe "Sicherheits-Lampe Bremskontrolle wurde eingeschaltet;
";
CM_ SG_ 779 KBI_Einheit_Tacho "Information, ob es sich um Meilen- oder Kmh-Kombi handelt, Einheit des Tachos entspricht dem Zifferblatt, Grösse ist nicht veränderlich";
CM_ SG_ 779 KBI_ESP_Lampe "ESP-Sicherheits-Lampe wurde eingeschaltet ";
CM_ SG_ 779 KBI_Fehler_Anzeige_ACC "Rückmeldung an ACC, dass mindestens eine der ACC-relevanten Anzeigen -rote Fahrerübernahme, Mitteldisplay, Gong - fehlerhaft sind.";
CM_ SG_ 779 KBI_GRA_Hauptschalter "Hauptschalter der Fahrerassistenzsysteme basierend auf dem FAS-Menu im Kombi.";
CM_ SG_ 779 KBI_Handbremse "Handbremsen-Information vom Kombi.
Das Signal bezieht sich ausschließlich auf den Zustand der konventionellen Handbremse.";
CM_ SG_ 779 KBI_im_Stellgliedtest "Kombi im Stellgliedtest, Signal muss eingelesen werden, um Fehlfunktion aufgrund der Bewegung der Stellglieder (Drehzahlmesser, Tacho) des Kombis zu verhindern";
CM_ SG_ 779 KBI_Konsistenz_ACC "Rückmeldung an ACC, dass die Botschaften zur Ansteuerung von Anzeigen nicht bzw. nicht konsistent empfangen wurden (Timeout-, BZ-, CHK- und DLC-Fehler)                                                                                                        ";
CM_ SG_ 779 KBI_Lenkung_Lampe "Sicherheits-Lampe der Lenkung (Lenkhilfe EPS, Audi-Dynamic-Steering ...) wurde eingeschaltet.

0x0 = Lenkungs-Lampe aus
0x1 = Lenkungs-Lampe ein";
CM_ SG_ 779 KBI_MFA_v_Einheit_01 "Einheit der Geschwindigkeit, die vom Fahrer im Car-Menü gewählt wurde. Veränderliche Grösse, im Gegensatz zur Einheit des Tachokranzes.";
CM_ SG_ 779 KBI_NV_in_Anzeige "Das Bit gibt dem NV die Information, ob NV-Bild im Kombi in der Anzeige ist. (Information ist notwendig um Kontrasverstellungen nur dann zuzulassen, wenn der Fahrer das Feedback über das  Kombidisplay bekommt.)";
CM_ SG_ 779 KBI_PLA_in_Anzeige "Das Signal wird als aktive Rückmeldung genutzt, ob die Info des PLA im Kombi angezeigt wird. Wenn nach Anforderung des Displays das Signal zweimal auf 0 ist, wird der Parkvorgang abgebrochen.
Ein Kombi, dass PLA Anzeige nicht unterstützt, schickt dauerha";
CM_ SG_ 779 KBI_SILA_gueltig "Rückmeldeinformation (Bit 1-6) ist gültig";
CM_ SG_ 779 KBI_Systemstatus "Signalisiert erkannte FuSi-relevante Fehler im Kombi
(keinen Ausfall der Akustik oder des Displays)";
CM_ SG_ 779 KBI_Tankwarnung "Fahrer wird gewarnt, dass er den Reservebereich erreicht hat. Fzg.spezifische Warnschwelle";
CM_ SG_ 779 KBI_Tankwarnung_ungueltig "Validiert den Inhalt des Signales KBI_Tankwarnung";
CM_ SG_ 779 KBI_Taster_Fahrwerk "Betätigung Taster 'Fahrwerk' im Kombi";
CM_ SG_ 779 KBI_Taster_Lift "Betätigung Taster 'Lift' im Kombi J1 zur Verarbeitung im Porsche EFP Steuergerät";
CM_ SG_ 779 KBI_V_Digital "Ausgabe der im Kombi angezeigten digitalen Geschwindigkeit.

Einheit ist im KBI_MFA_v_Einheit_01 definiert";
CM_ SG_ 779 KBI_Vorglueh_System_Lampe "Rückmeldung der Vorglühlampe bzw. Motor Systemlampe (MO_Systemlampe) an den Motor (bei Diesel und Otto!). Hardwaremässig gleiche LED im Kombi (EPC- oder Glühwendel), Unterscheidung nur über Ziffernblatt.";
BA_DEF_REL_ BU_SG_REL_  "GenSigTimeoutTime" INT 0 65535;
BA_DEF_ BO_  "DiagRequest" ENUM "No", "Yes";
BA_DEF_ BO_  "DiagResponse" ENUM "No", "Yes";
BA_DEF_ BO_  "DiagState" ENUM "No", "Yes";
BA_DEF_ BO_  "GenMsgChkConstant" HEX 0 4095;
BA_DEF_ BO_  "GenMsgCycleTime" INT 0 65535;
BA_DEF_ BO_  "GenMsgCycleTimeFast" INT 0 65535;
BA_DEF_ BO_  "GenMsgDelayTime" INT 0 100000;
BA_DEF_ BO_  "GenMsgILSupport" ENUM "No", "Yes";
BA_DEF_ BO_  "GenMsgNrOfRepetition" INT 0 100;
BA_DEF_ BO_  "GenMsgPDUConstants" STRING;
BA_DEF_ BO_  "GenMsgSendType" ENUM "Cyclic", "not_used", "not_used", "not_used", "not_used", "not_used", "not_used", "IfActive", "NoMsgSendType";
BA_DEF_ BO_  "GenMsgStartDelayTime" INT 0 100000;
BA_DEF_ BO_  "NmMessage" ENUM "No", "Yes";
BA_DEF_ BO_  "NmhMessage" ENUM "No", "Yes";
BA_DEF_ BO_  "MsgType" ENUM "Application", "NM ", "NMH", "TP2.0", "ISO-TP ", "BAP", "EID", "KS", "XCP_PRE_CONFIGURED", "XCP_RUNTIME_CONFIGURED";
BA_DEF_ BO_  "VAGTP20_API" HEX 0 255;
BA_DEF_ BO_  "VAGTP20_DynConnection" ENUM "No", "Yes";
BA_DEF_ BO_  "VAGTP20_DynSetup" ENUM "No", "Yes";
BA_DEF_ BO_  "VAGTP20_StatConnection" ENUM "No", "Yes";
BA_DEF_ SG_  "GenSigActiveRepetitions" INT -2147483648 2147483647;
BA_DEF_ SG_  "GenSigInactiveValue" INT -2147483648 2147483647;
BA_DEF_ SG_  "GenSigSendType" ENUM "Cyclic", "OnWrite", "OnWriteWithRepetition", "OnChange", "OnChangeWithRepetition", "IfActive", "IfActiveWithRepetition", "NoSigSendType", "OnChangeAndIfActive", "OnChangeAndIfActiveWithRepetition";
BA_DEF_ SG_  "GenSigStartValue" INT -2147483648 2147483647;
BA_DEF_ SG_  "NWM-WakeupAllowed" ENUM "No", "Yes";
BA_DEF_ SG_  "GenSigFuncType" ENUM "NoFunction", "MsgCounter", "CRC-8", "XOR", "XOR-2", "DatedBit", "SW-Kl15", "CHK", "Constant", "Protocol", "CRC-8-SAE_J1850", "CRC-32", "DataLength", "DataID", "MsgCounter16", "SOK-Signatur", "Cluster";
BA_DEF_ SG_  "GenSigSwitchedByIgnition" ENUM "No", "Yes";
BA_DEF_ SG_  "Fehlerwert" HEX 0 2147483647;
BA_DEF_ SG_  "GenSigMissingSourceValue" HEX 0 2147483647;
BA_DEF_DEF_REL_  "GenSigTimeoutTime" 0;
BA_DEF_DEF_  "DiagRequest" "No";
BA_DEF_DEF_  "DiagResponse" "No";
BA_DEF_DEF_  "DiagState" "No";
BA_DEF_DEF_  "GenMsgChkConstant" 0;
BA_DEF_DEF_  "GenMsgCycleTime" 0;
BA_DEF_DEF_  "GenMsgCycleTimeFast" 0;
BA_DEF_DEF_  "GenMsgDelayTime" 0;
BA_DEF_DEF_  "GenMsgILSupport" "No";
BA_DEF_DEF_  "GenMsgNrOfRepetition" 0;
BA_DEF_DEF_  "GenMsgPDUConstants" "";
BA_DEF_DEF_  "GenMsgSendType" "NoMsgSendType";
BA_DEF_DEF_  "GenMsgStartDelayTime" 0;
BA_DEF_DEF_  "NmMessage" "No";
BA_DEF_DEF_  "NmhMessage" "No";
BA_DEF_DEF_  "MsgType" "Application";
BA_DEF_DEF_  "VAGTP20_API" 0;
BA_DEF_DEF_  "VAGTP20_DynConnection" "No";
BA_DEF_DEF_  "VAGTP20_DynSetup" "No";
BA_DEF_DEF_  "VAGTP20_StatConnection" "No";
BA_DEF_DEF_  "GenSigActiveRepetitions" 0;
BA_DEF_DEF_  "GenSigInactiveValue" 0;
BA_DEF_DEF_  "GenSigSendType" "NoSigSendType";
BA_DEF_DEF_  "GenSigStartValue" 0;
BA_DEF_DEF_  "NWM-WakeupAllowed" "No";
BA_DEF_DEF_  "GenSigFuncType" "NoFunction";
BA_DEF_DEF_  "GenSigSwitchedByIgnition" "Yes";
BA_DEF_DEF_  "Fehlerwert" 0;
BA_DEF_DEF_  "GenSigMissingSourceValue" 0;
BA_ "DiagRequest" BO_ 1891 1;
BA_ "MsgType" BO_ 1891 4;
BA_ "DiagResponse" BO_ 1997 1;
BA_ "MsgType" BO_ 1997 4;
BA_ "DiagRequest" BO_ 1907 1;
BA_ "MsgType" BO_ 1907 4;
BA_ "DiagResponse" BO_ 2013 1;
BA_ "MsgType" BO_ 2013 4;
BA_ "DiagRequest" BO_ 1904 1;
BA_ "MsgType" BO_ 1904 4;
BA_ "DiagResponse" BO_ 2010 1;
BA_ "MsgType" BO_ 2010 4;
BA_ "DiagRequest" BO_ 1901 1;
BA_ "MsgType" BO_ 1901 4;
BA_ "DiagResponse" BO_ 2007 1;
BA_ "MsgType" BO_ 2007 4;
BA_ "DiagRequest" BO_ 2549874830 1;
BA_ "MsgType" BO_ 2549874830 4;
BA_ "DiagResponse" BO_ 2550005902 1;
BA_ "MsgType" BO_ 2550005902 4;
BA_ "DiagRequest" BO_ 2549874835 1;
BA_ "MsgType" BO_ 2549874835 4;
BA_ "DiagResponse" BO_ 2550005907 1;
BA_ "MsgType" BO_ 2550005907 4;
BA_ "DiagRequest" BO_ 2549874874 1;
BA_ "MsgType" BO_ 2549874874 4;
BA_ "DiagResponse" BO_ 2550005946 1;
BA_ "MsgType" BO_ 2550005946 4;
BA_ "DiagRequest" BO_ 2549874858 1;
BA_ "MsgType" BO_ 2549874858 4;
BA_ "DiagResponse" BO_ 2550005930 1;
BA_ "MsgType" BO_ 2550005930 4;
BA_ "DiagRequest" BO_ 2549874859 1;
BA_ "MsgType" BO_ 2549874859 4;
BA_ "DiagResponse" BO_ 2550005931 1;
BA_ "MsgType" BO_ 2550005931 4;
BA_ "DiagRequest" BO_ 2549874855 1;
BA_ "MsgType" BO_ 2549874855 4;
BA_ "DiagResponse" BO_ 2550005927 1;
BA_ "MsgType" BO_ 2550005927 4;
BA_ "DiagRequest" BO_ 2549874856 1;
BA_ "MsgType" BO_ 2549874856 4;
BA_ "DiagResponse" BO_ 2550005928 1;
BA_ "MsgType" BO_ 2550005928 4;
BA_ "DiagRequest" BO_ 2549874853 1;
BA_ "MsgType" BO_ 2549874853 4;
BA_ "DiagResponse" BO_ 2550005925 1;
BA_ "MsgType" BO_ 2550005925 4;
BA_ "DiagRequest" BO_ 2549874854 1;
BA_ "MsgType" BO_ 2549874854 4;
BA_ "DiagResponse" BO_ 2550005926 1;
BA_ "MsgType" BO_ 2550005926 4;
BA_ "GenMsgCycleTime" BO_ 497 500;
BA_ "GenMsgCycleTimeFast" BO_ 497 40;
BA_ "GenMsgDelayTime" BO_ 497 20;
BA_ "GenMsgILSupport" BO_ 497 1;
BA_ "GenMsgNrOfRepetition" BO_ 497 7;
BA_ "GenMsgSendType" BO_ 497 0;
BA_ "GenMsgCycleTime" BO_ 1424 200;
BA_ "GenMsgDelayTime" BO_ 1424 50;
BA_ "GenMsgILSupport" BO_ 1424 1;
BA_ "GenMsgSendType" BO_ 1424 0;
BA_ "GenMsgChkConstant" BO_ 960 195;
BA_ "GenMsgCycleTime" BO_ 960 100;
BA_ "GenMsgDelayTime" BO_ 960 10;
BA_ "GenMsgILSupport" BO_ 960 1;
BA_ "GenMsgPDUConstants" BO_ 960 "0xc3,0xc3,0xc3,0xc3,0xc3,0xc3,0xc3,0xc3,0xc3,0xc3,0xc3,0xc3,0xc3,0xc3,0xc3,0xc3";
BA_ "GenMsgSendType" BO_ 960 0;
BA_ "GenMsgCycleTime" BO_ 1420 1000;
BA_ "GenMsgCycleTimeFast" BO_ 1420 100;
BA_ "GenMsgDelayTime" BO_ 1420 50;
BA_ "GenMsgILSupport" BO_ 1420 1;
BA_ "GenMsgNrOfRepetition" BO_ 1420 3;
BA_ "GenMsgPDUConstants" BO_ 1420 "0x9b,0xb5,0x9d,0x06,0x01,0xe7,0x8f,0xc1,0xd0,0x10,0x47,0xe9,0xd3,0xca,0x05,0xf0";
BA_ "GenMsgSendType" BO_ 1420 0;
BA_ "GenMsgCycleTime" BO_ 1646 2000;
BA_ "GenMsgDelayTime" BO_ 1646 200;
BA_ "GenMsgILSupport" BO_ 1646 1;
BA_ "GenMsgSendType" BO_ 1646 0;
BA_ "GenMsgCycleTime" BO_ 1663 1000;
BA_ "GenMsgDelayTime" BO_ 1663 50;
BA_ "GenMsgILSupport" BO_ 1663 1;
BA_ "GenMsgSendType" BO_ 1663 0;
BA_ "GenMsgCycleTime" BO_ 1608 1000;
BA_ "GenMsgDelayTime" BO_ 1608 50;
BA_ "GenMsgILSupport" BO_ 1608 1;
BA_ "GenMsgSendType" BO_ 1608 0;
BA_ "GenMsgCycleTime" BO_ 949 1000;
BA_ "GenMsgILSupport" BO_ 949 1;
BA_ "GenMsgSendType" BO_ 949 0;
BA_ "GenMsgStartDelayTime" BO_ 949 380;
BA_ "GenMsgCycleTime" BO_ 1640 200;
BA_ "GenMsgCycleTimeFast" BO_ 1640 100;
BA_ "GenMsgDelayTime" BO_ 1640 25;
BA_ "GenMsgILSupport" BO_ 1640 1;
BA_ "GenMsgNrOfRepetition" BO_ 1640 5;
BA_ "GenMsgSendType" BO_ 1640 0;
BA_ "GenMsgCycleTime" BO_ 1441 500;
BA_ "GenMsgILSupport" BO_ 1441 1;
BA_ "GenMsgSendType" BO_ 1441 0;
BA_ "GenMsgCycleTime" BO_ 2589283621 1000;
BA_ "GenMsgDelayTime" BO_ 2589283621 100;
BA_ "GenMsgILSupport" BO_ 2589283621 1;
BA_ "GenMsgSendType" BO_ 2589283621 0;
BA_ "GenMsgCycleTime" BO_ 992 100;
BA_ "GenMsgILSupport" BO_ 992 1;
BA_ "GenMsgSendType" BO_ 992 0;
BA_ "GenMsgCycleTime" BO_ 1712 500;
BA_ "GenMsgILSupport" BO_ 1712 1;
BA_ "GenMsgSendType" BO_ 1712 0;
BA_ "GenMsgCycleTime" BO_ 1505 1000;
BA_ "GenMsgILSupport" BO_ 1505 1;
BA_ "GenMsgSendType" BO_ 1505 0;
BA_ "GenMsgStartDelayTime" BO_ 1505 410;
BA_ "GenMsgCycleTime" BO_ 605 1000;
BA_ "GenMsgILSupport" BO_ 605 1;
BA_ "GenMsgPDUConstants" BO_ 605 "0xda,0x6b,0x0e,0xb2,0x78,0xbd,0x5a,0x81,0x7b,0xd6,0x41,0x39,0x76,0xb6,0xd7,0x35";
BA_ "GenMsgSendType" BO_ 605 0;
BA_ "GenMsgStartDelayTime" BO_ 605 420;
BA_ "GenMsgCycleTime" BO_ 2549088398 500;
BA_ "GenMsgILSupport" BO_ 2549088398 1;
BA_ "GenMsgSendType" BO_ 2549088398 0;
BA_ "GenMsgCycleTime" BO_ 2549088403 500;
BA_ "GenMsgILSupport" BO_ 2549088403 1;
BA_ "GenMsgSendType" BO_ 2549088403 0;
BA_ "GenMsgCycleTime" BO_ 2549088442 500;
BA_ "GenMsgILSupport" BO_ 2549088442 1;
BA_ "GenMsgSendType" BO_ 2549088442 0;
BA_ "GenMsgCycleTime" BO_ 2549088272 500;
BA_ "GenMsgILSupport" BO_ 2549088272 1;
BA_ "GenMsgSendType" BO_ 2549088272 0;
BA_ "GenMsgStartDelayTime" BO_ 2549088272 75;
BA_ "GenMsgCycleTime" BO_ 2549088355 500;
BA_ "GenMsgILSupport" BO_ 2549088355 1;
BA_ "GenMsgSendType" BO_ 2549088355 0;
BA_ "GenMsgCycleTime" BO_ 2549088371 500;
BA_ "GenMsgILSupport" BO_ 2549088371 1;
BA_ "GenMsgSendType" BO_ 2549088371 0;
BA_ "GenMsgCycleTime" BO_ 2549088258 500;
BA_ "GenMsgILSupport" BO_ 2549088258 1;
BA_ "GenMsgSendType" BO_ 2549088258 0;
BA_ "GenMsgCycleTime" BO_ 779 50;
BA_ "GenMsgILSupport" BO_ 779 1;
BA_ "GenMsgSendType" BO_ 779 0;
BA_ "GenSigSendType" SG_ 1891 ISO_Gurtmikro_Req_Data 3;
BA_ "GenSigFuncType" SG_ 1891 ISO_Gurtmikro_Req_Data 9;
BA_ "GenSigSendType" SG_ 1997 ISO_Gurtmikro_Resp_Data 3;
BA_ "GenSigFuncType" SG_ 1997 ISO_Gurtmikro_Resp_Data 9;
BA_ "GenSigSendType" SG_ 1907 ISO_Info_El_Req_Data 3;
BA_ "GenSigFuncType" SG_ 1907 ISO_Info_El_Req_Data 9;
BA_ "GenSigSwitchedByIgnition" SG_ 1907 ISO_Info_El_Req_Data 0;
BA_ "GenSigSendType" SG_ 2013 ISO_Info_El_Resp_Data 3;
BA_ "GenSigFuncType" SG_ 2013 ISO_Info_El_Resp_Data 9;
BA_ "GenSigSwitchedByIgnition" SG_ 2013 ISO_Info_El_Resp_Data 0;
BA_ "GenSigSendType" SG_ 1904 ISO_Laufwerke_Req_Data 3;
BA_ "GenSigFuncType" SG_ 1904 ISO_Laufwerke_Req_Data 9;
BA_ "GenSigSwitchedByIgnition" SG_ 1904 ISO_Laufwerke_Req_Data 0;
BA_ "GenSigSendType" SG_ 2010 ISO_Laufwerke_Resp_Data 3;
BA_ "GenSigFuncType" SG_ 2010 ISO_Laufwerke_Resp_Data 9;
BA_ "GenSigSwitchedByIgnition" SG_ 2010 ISO_Laufwerke_Resp_Data 0;
BA_ "GenSigSendType" SG_ 1901 ISO_TV_Tuner_Req_Data 3;
BA_ "GenSigFuncType" SG_ 1901 ISO_TV_Tuner_Req_Data 9;
BA_ "GenSigSwitchedByIgnition" SG_ 1901 ISO_TV_Tuner_Req_Data 0;
BA_ "GenSigSendType" SG_ 2007 ISO_TV_Tuner_Resp_Data 3;
BA_ "GenSigFuncType" SG_ 2007 ISO_TV_Tuner_Resp_Data 9;
BA_ "GenSigSwitchedByIgnition" SG_ 2007 ISO_TV_Tuner_Resp_Data 0;
BA_ "GenSigSendType" SG_ 2549874830 ISOx_BedienDisp_vo_Req_Data 3;
BA_ "GenSigFuncType" SG_ 2549874830 ISOx_BedienDisp_vo_Req_Data 9;
BA_ "GenSigSwitchedByIgnition" SG_ 2549874830 ISOx_BedienDisp_vo_Req_Data 0;
BA_ "GenSigSendType" SG_ 2550005902 ISOx_BedienDisp_vo_Resp_Data 3;
BA_ "GenSigFuncType" SG_ 2550005902 ISOx_BedienDisp_vo_Resp_Data 9;
BA_ "GenSigSwitchedByIgnition" SG_ 2550005902 ISOx_BedienDisp_vo_Resp_Data 0;
BA_ "GenSigSendType" SG_ 2549874835 ISOx_BedienSG_hi_Req_Data 3;
BA_ "GenSigFuncType" SG_ 2549874835 ISOx_BedienSG_hi_Req_Data 9;
BA_ "GenSigSwitchedByIgnition" SG_ 2549874835 ISOx_BedienSG_hi_Req_Data 0;
BA_ "GenSigSendType" SG_ 2550005907 ISOx_BedienSG_hi_Resp_Data 3;
BA_ "GenSigFuncType" SG_ 2550005907 ISOx_BedienSG_hi_Resp_Data 9;
BA_ "GenSigSwitchedByIgnition" SG_ 2550005907 ISOx_BedienSG_hi_Resp_Data 0;
BA_ "GenSigSendType" SG_ 2549874874 ISOx_DDA_Req_Data 3;
BA_ "GenSigFuncType" SG_ 2549874874 ISOx_DDA_Req_Data 9;
BA_ "GenSigSwitchedByIgnition" SG_ 2549874874 ISOx_DDA_Req_Data 0;
BA_ "GenSigSendType" SG_ 2550005946 ISOx_DDA_Resp_Data 3;
BA_ "GenSigFuncType" SG_ 2550005946 ISOx_DDA_Resp_Data 9;
BA_ "GenSigSwitchedByIgnition" SG_ 2550005946 ISOx_DDA_Resp_Data 0;
BA_ "GenSigSendType" SG_ 2549874858 ISOx_SCC1_Req_Data 3;
BA_ "GenSigFuncType" SG_ 2549874858 ISOx_SCC1_Req_Data 9;
BA_ "GenSigSwitchedByIgnition" SG_ 2549874858 ISOx_SCC1_Req_Data 0;
BA_ "GenSigSendType" SG_ 2550005930 ISOx_SCC1_Resp_Data 3;
BA_ "GenSigFuncType" SG_ 2550005930 ISOx_SCC1_Resp_Data 9;
BA_ "GenSigSwitchedByIgnition" SG_ 2550005930 ISOx_SCC1_Resp_Data 0;
BA_ "GenSigSendType" SG_ 2549874859 ISOx_SCC2_Req_Data 3;
BA_ "GenSigFuncType" SG_ 2549874859 ISOx_SCC2_Req_Data 9;
BA_ "GenSigSwitchedByIgnition" SG_ 2549874859 ISOx_SCC2_Req_Data 0;
BA_ "GenSigSendType" SG_ 2550005931 ISOx_SCC2_Resp_Data 3;
BA_ "GenSigFuncType" SG_ 2550005931 ISOx_SCC2_Resp_Data 9;
BA_ "GenSigSwitchedByIgnition" SG_ 2550005931 ISOx_SCC2_Resp_Data 0;
BA_ "GenSigSendType" SG_ 2549874855 ISOx_SDC1_Req_Data 3;
BA_ "GenSigFuncType" SG_ 2549874855 ISOx_SDC1_Req_Data 9;
BA_ "GenSigSwitchedByIgnition" SG_ 2549874855 ISOx_SDC1_Req_Data 0;
BA_ "GenSigSendType" SG_ 2550005927 ISOx_SDC1_Resp_Data 3;
BA_ "GenSigFuncType" SG_ 2550005927 ISOx_SDC1_Resp_Data 9;
BA_ "GenSigSwitchedByIgnition" SG_ 2550005927 ISOx_SDC1_Resp_Data 0;
BA_ "GenSigSendType" SG_ 2549874856 ISOx_SDC2_Req_Data 3;
BA_ "GenSigFuncType" SG_ 2549874856 ISOx_SDC2_Req_Data 9;
BA_ "GenSigSwitchedByIgnition" SG_ 2549874856 ISOx_SDC2_Req_Data 0;
BA_ "GenSigSendType" SG_ 2550005928 ISOx_SDC2_Resp_Data 3;
BA_ "GenSigFuncType" SG_ 2550005928 ISOx_SDC2_Resp_Data 9;
BA_ "GenSigSwitchedByIgnition" SG_ 2550005928 ISOx_SDC2_Resp_Data 0;
BA_ "GenSigSendType" SG_ 2549874853 ISOx_WLC1_Req_Data 3;
BA_ "GenSigFuncType" SG_ 2549874853 ISOx_WLC1_Req_Data 9;
BA_ "GenSigSwitchedByIgnition" SG_ 2549874853 ISOx_WLC1_Req_Data 0;
BA_ "GenSigSendType" SG_ 2550005925 ISOx_WLC1_Resp_Data 3;
BA_ "GenSigFuncType" SG_ 2550005925 ISOx_WLC1_Resp_Data 9;
BA_ "GenSigSwitchedByIgnition" SG_ 2550005925 ISOx_WLC1_Resp_Data 0;
BA_ "GenSigSendType" SG_ 2549874854 ISOx_WLC2_Req_Data 3;
BA_ "GenSigFuncType" SG_ 2549874854 ISOx_WLC2_Req_Data 9;
BA_ "GenSigSwitchedByIgnition" SG_ 2549874854 ISOx_WLC2_Req_Data 0;
BA_ "GenSigSendType" SG_ 2550005926 ISOx_WLC2_Resp_Data 3;
BA_ "GenSigFuncType" SG_ 2550005926 ISOx_WLC2_Resp_Data 9;
BA_ "GenSigSwitchedByIgnition" SG_ 2550005926 ISOx_WLC2_Resp_Data 0;
BA_ "GenSigActiveRepetitions" SG_ 497 FBS_Aktivierung_Pilot_Parken 7;
BA_ "GenSigSendType" SG_ 497 FBS_Aktivierung_Pilot_Parken 2;
BA_ "GenSigSwitchedByIgnition" SG_ 497 FBS_Aktivierung_Pilot_Parken 0;
BA_ "GenSigActiveRepetitions" SG_ 497 FFB_FDF_Taste 7;
BA_ "GenSigSendType" SG_ 497 FFB_FDF_Taste 2;
BA_ "GenSigSwitchedByIgnition" SG_ 497 FFB_FDF_Taste 0;
BA_ "GenSigActiveRepetitions" SG_ 497 FFB_Joker_Taste 7;
BA_ "GenSigSendType" SG_ 497 FFB_Joker_Taste 2;
BA_ "GenSigSwitchedByIgnition" SG_ 497 FFB_Joker_Taste 0;
BA_ "GenSigActiveRepetitions" SG_ 497 FFB_Park_Taste 7;
BA_ "GenSigSendType" SG_ 497 FFB_Park_Taste 2;
BA_ "GenSigSwitchedByIgnition" SG_ 497 FFB_Park_Taste 0;
BA_ "GenSigActiveRepetitions" SG_ 497 FFB_Remotestart_Taste 7;
BA_ "GenSigSendType" SG_ 497 FFB_Remotestart_Taste 2;
BA_ "GenSigSwitchedByIgnition" SG_ 497 FFB_Remotestart_Taste 0;
BA_ "GenSigActiveRepetitions" SG_ 497 KY_Auf_Taste 7;
BA_ "GenSigSendType" SG_ 497 KY_Auf_Taste 2;
BA_ "GenSigSwitchedByIgnition" SG_ 497 KY_Auf_Taste 0;
BA_ "GenSigActiveRepetitions" SG_ 497 KY_Bereich 7;
BA_ "GenSigSendType" SG_ 497 KY_Bereich 2;
BA_ "GenSigStartValue" SG_ 497 KY_Bereich 7;
BA_ "GenSigSwitchedByIgnition" SG_ 497 KY_Bereich 0;
BA_ "GenSigActiveRepetitions" SG_ 497 KY_BT_Entriegelung_Autorisiert 7;
BA_ "GenSigSendType" SG_ 497 KY_BT_Entriegelung_Autorisiert 2;
BA_ "GenSigSwitchedByIgnition" SG_ 497 KY_BT_Entriegelung_Autorisiert 0;
BA_ "GenSigActiveRepetitions" SG_ 497 KY_BT_Verriegelung_Autorisiert 7;
BA_ "GenSigSendType" SG_ 497 KY_BT_Verriegelung_Autorisiert 2;
BA_ "GenSigSwitchedByIgnition" SG_ 497 KY_BT_Verriegelung_Autorisiert 0;
BA_ "GenSigSendType" SG_ 497 KY_EasyClose_Abbruch 3;
BA_ "GenSigSwitchedByIgnition" SG_ 497 KY_EasyClose_Abbruch 0;
BA_ "GenSigSendType" SG_ 497 KY_EasyClose_Status 3;
BA_ "GenSigSwitchedByIgnition" SG_ 497 KY_EasyClose_Status 0;
BA_ "GenSigActiveRepetitions" SG_ 497 KY_Front_Entr_Autorisiert 7;
BA_ "GenSigSendType" SG_ 497 KY_Front_Entr_Autorisiert 2;
BA_ "GenSigSwitchedByIgnition" SG_ 497 KY_Front_Entr_Autorisiert 0;
BA_ "GenSigActiveRepetitions" SG_ 497 KY_Front_Verr_Autorisiert 7;
BA_ "GenSigSendType" SG_ 497 KY_Front_Verr_Autorisiert 2;
BA_ "GenSigSwitchedByIgnition" SG_ 497 KY_Front_Verr_Autorisiert 0;
BA_ "GenSigActiveRepetitions" SG_ 497 KY_FT_Entriegelung_Autorisiert 7;
BA_ "GenSigSendType" SG_ 497 KY_FT_Entriegelung_Autorisiert 2;
BA_ "GenSigSwitchedByIgnition" SG_ 497 KY_FT_Entriegelung_Autorisiert 0;
BA_ "GenSigActiveRepetitions" SG_ 497 KY_FT_Verriegelung_Autorisiert 7;
BA_ "GenSigSendType" SG_ 497 KY_FT_Verriegelung_Autorisiert 2;
BA_ "GenSigSwitchedByIgnition" SG_ 497 KY_FT_Verriegelung_Autorisiert 0;
BA_ "GenSigActiveRepetitions" SG_ 497 KY_HBFS_Entriegelung_Autorisiert 7;
BA_ "GenSigSendType" SG_ 497 KY_HBFS_Entriegelung_Autorisiert 2;
BA_ "GenSigSwitchedByIgnition" SG_ 497 KY_HBFS_Entriegelung_Autorisiert 0;
BA_ "GenSigActiveRepetitions" SG_ 497 KY_HBFS_Verriegelung_Autorisiert 7;
BA_ "GenSigSendType" SG_ 497 KY_HBFS_Verriegelung_Autorisiert 2;
BA_ "GenSigSwitchedByIgnition" SG_ 497 KY_HBFS_Verriegelung_Autorisiert 0;
BA_ "GenSigActiveRepetitions" SG_ 497 KY_HD_Auffahrt 7;
BA_ "GenSigSendType" SG_ 497 KY_HD_Auffahrt 2;
BA_ "GenSigSwitchedByIgnition" SG_ 497 KY_HD_Auffahrt 0;
BA_ "GenSigActiveRepetitions" SG_ 497 KY_HD_Entriegelung_Autorisiert 7;
BA_ "GenSigSendType" SG_ 497 KY_HD_Entriegelung_Autorisiert 2;
BA_ "GenSigSwitchedByIgnition" SG_ 497 KY_HD_Entriegelung_Autorisiert 0;
BA_ "GenSigActiveRepetitions" SG_ 497 KY_HD_Verriegelung_Autorisiert 7;
BA_ "GenSigSendType" SG_ 497 KY_HD_Verriegelung_Autorisiert 2;
BA_ "GenSigSwitchedByIgnition" SG_ 497 KY_HD_Verriegelung_Autorisiert 0;
BA_ "GenSigActiveRepetitions" SG_ 497 KY_HD_Zufahrt 7;
BA_ "GenSigSendType" SG_ 497 KY_HD_Zufahrt 2;
BA_ "GenSigSwitchedByIgnition" SG_ 497 KY_HD_Zufahrt 0;
BA_ "GenSigActiveRepetitions" SG_ 497 KY_HDF_Taste 7;
BA_ "GenSigSendType" SG_ 497 KY_HDF_Taste 2;
BA_ "GenSigSwitchedByIgnition" SG_ 497 KY_HDF_Taste 0;
BA_ "GenSigActiveRepetitions" SG_ 497 KY_HFS_Entriegelung_Autorisiert 7;
BA_ "GenSigSendType" SG_ 497 KY_HFS_Entriegelung_Autorisiert 2;
BA_ "GenSigSwitchedByIgnition" SG_ 497 KY_HFS_Entriegelung_Autorisiert 0;
BA_ "GenSigActiveRepetitions" SG_ 497 KY_HFS_Verriegelung_Autorisiert 7;
BA_ "GenSigSendType" SG_ 497 KY_HFS_Verriegelung_Autorisiert 2;
BA_ "GenSigSwitchedByIgnition" SG_ 497 KY_HFS_Verriegelung_Autorisiert 0;
BA_ "GenSigActiveRepetitions" SG_ 497 KY_IDG_in_Reichweite 7;
BA_ "GenSigSendType" SG_ 497 KY_IDG_in_Reichweite 2;
BA_ "GenSigSwitchedByIgnition" SG_ 497 KY_IDG_in_Reichweite 0;
BA_ "GenSigActiveRepetitions" SG_ 497 KY_LKL_1_Autorisierung 7;
BA_ "GenSigSendType" SG_ 497 KY_LKL_1_Autorisierung 2;
BA_ "GenSigSwitchedByIgnition" SG_ 497 KY_LKL_1_Autorisierung 0;
BA_ "GenSigActiveRepetitions" SG_ 497 KY_LKL_2_Autorisierung 7;
BA_ "GenSigSendType" SG_ 497 KY_LKL_2_Autorisierung 2;
BA_ "GenSigSwitchedByIgnition" SG_ 497 KY_LKL_2_Autorisierung 0;
BA_ "GenSigActiveRepetitions" SG_ 497 KY_Panik_Taste 7;
BA_ "GenSigSendType" SG_ 497 KY_Panik_Taste 2;
BA_ "GenSigSwitchedByIgnition" SG_ 497 KY_Panik_Taste 0;
BA_ "GenSigActiveRepetitions" SG_ 497 KY_Position 7;
BA_ "GenSigSendType" SG_ 497 KY_Position 2;
BA_ "GenSigStartValue" SG_ 497 KY_Position 7;
BA_ "GenSigSwitchedByIgnition" SG_ 497 KY_Position 0;
BA_ "GenSigActiveRepetitions" SG_ 497 KY_Schluessel_im_Fzg 7;
BA_ "GenSigSendType" SG_ 497 KY_Schluessel_im_Fzg 2;
BA_ "GenSigSwitchedByIgnition" SG_ 497 KY_Schluessel_im_Fzg 0;
BA_ "GenSigActiveRepetitions" SG_ 497 KY_Zu_Taste 7;
BA_ "GenSigSendType" SG_ 497 KY_Zu_Taste 2;
BA_ "GenSigSwitchedByIgnition" SG_ 497 KY_Zu_Taste 0;
BA_ "GenSigActiveRepetitions" SG_ 497 KY_ZV_Signatur 7;
BA_ "GenSigSendType" SG_ 497 KY_ZV_Signatur 2;
BA_ "GenSigSwitchedByIgnition" SG_ 497 KY_ZV_Signatur 0;
BA_ "GenSigActiveRepetitions" SG_ 497 Schluesselnr_Personalisierung 7;
BA_ "GenSigSendType" SG_ 497 Schluesselnr_Personalisierung 2;
BA_ "GenSigStartValue" SG_ 497 Schluesselnr_Personalisierung 14;
BA_ "GenSigSwitchedByIgnition" SG_ 497 Schluesselnr_Personalisierung 0;
BA_ "Fehlerwert" SG_ 497 Schluesselnr_Personalisierung 15;
BA_ "GenSigSendType" SG_ 1424 FBS_Warn_Schluessel_Batt 3;
BA_ "GenSigSwitchedByIgnition" SG_ 1424 FBS_Warn_Schluessel_Batt 0;
BA_ "GenSigSendType" SG_ 1424 KST_Wegstrecke_Challenge 0;
BA_ "GenSigSwitchedByIgnition" SG_ 1424 KST_Wegstrecke_Challenge 0;
BA_ "GenSigSendType" SG_ 1424 KY_FFB_Frequenz 3;
BA_ "GenSigSwitchedByIgnition" SG_ 1424 KY_FFB_Frequenz 0;
BA_ "GenSigSendType" SG_ 1424 KY_Fzg_Verlassen_erkannt 3;
BA_ "GenSigSwitchedByIgnition" SG_ 1424 KY_Fzg_Verlassen_erkannt 0;
BA_ "GenSigSendType" SG_ 1424 KY_Fzg_Zugang_erkannt 3;
BA_ "GenSigSwitchedByIgnition" SG_ 1424 KY_Fzg_Zugang_erkannt 0;
BA_ "GenSigSendType" SG_ 1424 KY_HF_Aktiv 3;
BA_ "GenSigSwitchedByIgnition" SG_ 1424 KY_HF_Aktiv 0;
BA_ "GenSigSendType" SG_ 1424 KY_Indikator_Mehrere_Schluessel 3;
BA_ "GenSigSwitchedByIgnition" SG_ 1424 KY_Indikator_Mehrere_Schluessel 0;
BA_ "GenSigSendType" SG_ 1424 KY_Keyless_Go_Verbau 3;
BA_ "GenSigSwitchedByIgnition" SG_ 1424 KY_Keyless_Go_Verbau 0;
BA_ "GenSigSendType" SG_ 1424 KY_Keyless_Verbau 3;
BA_ "GenSigSwitchedByIgnition" SG_ 1424 KY_Keyless_Verbau 0;
BA_ "GenSigSendType" SG_ 1424 KY_KYL_Fahrer_Hinweise 3;
BA_ "GenSigSwitchedByIgnition" SG_ 1424 KY_KYL_Fahrer_Hinweise 0;
BA_ "GenSigSendType" SG_ 1424 KY_LF_Aktiv 3;
BA_ "GenSigSwitchedByIgnition" SG_ 1424 KY_LF_Aktiv 0;
BA_ "GenSigSendType" SG_ 1424 KY_NFC_Fahrer_Hinweise 0;
BA_ "GenSigSwitchedByIgnition" SG_ 1424 KY_NFC_Fahrer_Hinweise 0;
BA_ "GenSigSendType" SG_ 1424 KY_StartStopp_Info 3;
BA_ "GenSigSwitchedByIgnition" SG_ 1424 KY_StartStopp_Info 0;
BA_ "GenSigSendType" SG_ 1424 KY_Transponder_aktiv 3;
BA_ "GenSigSwitchedByIgnition" SG_ 1424 KY_Transponder_aktiv 0;
BA_ "GenSigSendType" SG_ 1424 KYL_Warn_kein_Schluessel 3;
BA_ "GenSigSwitchedByIgnition" SG_ 1424 KYL_Warn_kein_Schluessel 0;
BA_ "GenSigSendType" SG_ 1424 KYL_Warn_Kessy_defekt 3;
BA_ "GenSigSwitchedByIgnition" SG_ 1424 KYL_Warn_Kessy_defekt 0;
BA_ "GenSigSendType" SG_ 1424 KYL_Warn_Notzuendschloss 3;
BA_ "GenSigSwitchedByIgnition" SG_ 1424 KYL_Warn_Notzuendschloss 0;
BA_ "GenSigSendType" SG_ 960 BCM_Ausparken_Betrieb 3;
BA_ "GenSigSwitchedByIgnition" SG_ 960 BCM_Ausparken_Betrieb 0;
BA_ "GenSigSendType" SG_ 960 BCM_Remotestart_Betrieb 3;
BA_ "GenSigSwitchedByIgnition" SG_ 960 BCM_Remotestart_Betrieb 0;
BA_ "GenSigSendType" SG_ 960 BCM_Remotestart_KL15_Anf 3;
BA_ "GenSigSwitchedByIgnition" SG_ 960 BCM_Remotestart_KL15_Anf 0;
BA_ "GenSigSendType" SG_ 960 BCM_Remotestart_MO_Start 3;
BA_ "GenSigSwitchedByIgnition" SG_ 960 BCM_Remotestart_MO_Start 0;
BA_ "GenSigSendType" SG_ 960 Klemmen_Status_01_BZ 0;
BA_ "GenSigFuncType" SG_ 960 Klemmen_Status_01_BZ 1;
BA_ "GenSigSwitchedByIgnition" SG_ 960 Klemmen_Status_01_BZ 0;
BA_ "GenSigSendType" SG_ 960 Klemmen_Status_01_CRC 0;
BA_ "GenSigFuncType" SG_ 960 Klemmen_Status_01_CRC 2;
BA_ "GenSigSwitchedByIgnition" SG_ 960 Klemmen_Status_01_CRC 0;
BA_ "GenSigSendType" SG_ 960 KST_Fahrerhinweis_1 3;
BA_ "GenSigSwitchedByIgnition" SG_ 960 KST_Fahrerhinweis_1 0;
BA_ "GenSigSendType" SG_ 960 KST_Fahrerhinweis_2 3;
BA_ "GenSigSwitchedByIgnition" SG_ 960 KST_Fahrerhinweis_2 0;
BA_ "GenSigSendType" SG_ 960 KST_Fahrerhinweis_4 3;
BA_ "GenSigSwitchedByIgnition" SG_ 960 KST_Fahrerhinweis_4 0;
BA_ "GenSigSendType" SG_ 960 KST_Fahrerhinweis_5 3;
BA_ "GenSigSwitchedByIgnition" SG_ 960 KST_Fahrerhinweis_5 0;
BA_ "GenSigSendType" SG_ 960 KST_Fahrerhinweis_6 3;
BA_ "GenSigSwitchedByIgnition" SG_ 960 KST_Fahrerhinweis_6 0;
BA_ "GenSigSendType" SG_ 960 KST_Warn_P1_ZST_def 3;
BA_ "GenSigSwitchedByIgnition" SG_ 960 KST_Warn_P1_ZST_def 0;
BA_ "GenSigSendType" SG_ 960 KST_Warn_P2_ZST_def 3;
BA_ "GenSigSwitchedByIgnition" SG_ 960 KST_Warn_P2_ZST_def 0;
BA_ "GenSigSendType" SG_ 960 RSt_Fahrerhinweise 3;
BA_ "GenSigSwitchedByIgnition" SG_ 960 RSt_Fahrerhinweise 0;
BA_ "GenSigSendType" SG_ 960 ZAS_Kl_15 3;
BA_ "NWM-WakeupAllowed" SG_ 960 ZAS_Kl_15 1;
BA_ "GenSigFuncType" SG_ 960 ZAS_Kl_15 6;
BA_ "GenSigSwitchedByIgnition" SG_ 960 ZAS_Kl_15 0;
BA_ "GenSigSendType" SG_ 960 ZAS_Kl_50_Startanforderung 3;
BA_ "GenSigSwitchedByIgnition" SG_ 960 ZAS_Kl_50_Startanforderung 0;
BA_ "GenSigSendType" SG_ 960 ZAS_Kl_Infotainment 3;
BA_ "GenSigSwitchedByIgnition" SG_ 960 ZAS_Kl_Infotainment 0;
BA_ "GenSigSendType" SG_ 960 ZAS_Kl_S 3;
BA_ "GenSigSwitchedByIgnition" SG_ 960 ZAS_Kl_S 0;
BA_ "GenSigSendType" SG_ 960 ZAS_Kl_X 3;
BA_ "GenSigSwitchedByIgnition" SG_ 960 ZAS_Kl_X 0;
BA_ "GenSigSendType" SG_ 1420 Klemmen_Steuerung_01_BZ 0;
BA_ "GenSigFuncType" SG_ 1420 Klemmen_Steuerung_01_BZ 1;
BA_ "GenSigSwitchedByIgnition" SG_ 1420 Klemmen_Steuerung_01_BZ 0;
BA_ "GenSigSendType" SG_ 1420 Klemmen_Steuerung_01_CRC 0;
BA_ "GenSigFuncType" SG_ 1420 Klemmen_Steuerung_01_CRC 2;
BA_ "GenSigSwitchedByIgnition" SG_ 1420 Klemmen_Steuerung_01_CRC 0;
BA_ "GenSigSendType" SG_ 1420 KST_Anf_Klemmenfreigabe_ELV 8;
BA_ "GenSigSwitchedByIgnition" SG_ 1420 KST_Anf_Klemmenfreigabe_ELV 0;
BA_ "GenSigSendType" SG_ 1420 KST_Anf_ZV_Verriegelung 3;
BA_ "GenSigSwitchedByIgnition" SG_ 1420 KST_Anf_ZV_Verriegelung 0;
BA_ "GenSigActiveRepetitions" SG_ 1420 KST_aut_Abschaltung_Zuendung 3;
BA_ "GenSigSendType" SG_ 1420 KST_aut_Abschaltung_Zuendung 4;
BA_ "GenSigSwitchedByIgnition" SG_ 1420 KST_aut_Abschaltung_Zuendung 0;
BA_ "GenSigSendType" SG_ 1420 KST_Txt_Komfortabschaltung 3;
BA_ "GenSigSwitchedByIgnition" SG_ 1420 KST_Txt_Komfortabschaltung 0;
BA_ "GenSigSendType" SG_ 1420 KST_Txt_P_Gang 3;
BA_ "GenSigSwitchedByIgnition" SG_ 1420 KST_Txt_P_Gang 0;
BA_ "GenSigSendType" SG_ 1420 KST_Txt_Panikabschaltung 3;
BA_ "GenSigSwitchedByIgnition" SG_ 1420 KST_Txt_Panikabschaltung 0;
BA_ "GenSigSendType" SG_ 1420 KST_Unterdr_Zuendungsmeldung 3;
BA_ "GenSigSwitchedByIgnition" SG_ 1420 KST_Unterdr_Zuendungsmeldung 0;
BA_ "GenSigSendType" SG_ 1420 KST_ZAT_betaetigt 3;
BA_ "GenSigSwitchedByIgnition" SG_ 1420 KST_ZAT_betaetigt 0;
BA_ "GenSigSendType" SG_ 1420 Relais_VoKo_angesteuert 3;
BA_ "GenSigSwitchedByIgnition" SG_ 1420 Relais_VoKo_angesteuert 0;
BA_ "GenSigSendType" SG_ 1420 RSt_Anforderung_HMS 3;
BA_ "GenSigSwitchedByIgnition" SG_ 1420 RSt_Anforderung_HMS 0;
BA_ "GenSigSendType" SG_ 1646 KL_Anf_AussenspiegelHzg 3;
BA_ "GenSigSwitchedByIgnition" SG_ 1646 KL_Anf_AussenspiegelHzg 0;
BA_ "GenSigSendType" SG_ 1646 KL_BCmE_Livetip_Freigabe 3;
BA_ "GenSigSwitchedByIgnition" SG_ 1646 KL_BCmE_Livetip_Freigabe 0;
BA_ "GenSigSendType" SG_ 1646 KL_ErwVK_Anf 3;
BA_ "GenSigSwitchedByIgnition" SG_ 1646 KL_ErwVK_Anf 0;
BA_ "GenSigSendType" SG_ 1646 KL_ErwVK_Zusatzrelais 3;
BA_ "GenSigSwitchedByIgnition" SG_ 1646 KL_ErwVK_Zusatzrelais 0;
BA_ "GenSigSendType" SG_ 1646 KL_FSH_Automatikbetrieb 3;
BA_ "GenSigSwitchedByIgnition" SG_ 1646 KL_FSH_Automatikbetrieb 0;
BA_ "GenSigSendType" SG_ 1646 KL_Geblaese_Fond_Status 0;
BA_ "GenSigStartValue" SG_ 1646 KL_Geblaese_Fond_Status 14;
BA_ "GenSigSwitchedByIgnition" SG_ 1646 KL_Geblaese_Fond_Status 0;
BA_ "Fehlerwert" SG_ 1646 KL_Geblaese_Fond_Status 15;
BA_ "GenSigSendType" SG_ 1646 KL_Geblaese_Status 0;
BA_ "GenSigStartValue" SG_ 1646 KL_Geblaese_Status 14;
BA_ "GenSigSwitchedByIgnition" SG_ 1646 KL_Geblaese_Status 0;
BA_ "Fehlerwert" SG_ 1646 KL_Geblaese_Status 15;
BA_ "GenSigSendType" SG_ 1646 KL_Heizkreisventilstellung 0;
BA_ "GenSigSwitchedByIgnition" SG_ 1646 KL_Heizkreisventilstellung 0;
BA_ "Fehlerwert" SG_ 1646 KL_Heizkreisventilstellung 3;
BA_ "GenSigSendType" SG_ 1646 KL_HYB_ASV_hinten_schliessen_Anf 3;
BA_ "GenSigSwitchedByIgnition" SG_ 1646 KL_HYB_ASV_hinten_schliessen_Anf 0;
BA_ "GenSigSendType" SG_ 1646 KL_HYB_ASV_vorne_schliessen_Anf 3;
BA_ "GenSigSwitchedByIgnition" SG_ 1646 KL_HYB_ASV_vorne_schliessen_Anf 0;
BA_ "GenSigSendType" SG_ 1646 KL_I_Geblaese_Fond 3;
BA_ "GenSigSwitchedByIgnition" SG_ 1646 KL_I_Geblaese_Fond 0;
BA_ "Fehlerwert" SG_ 1646 KL_I_Geblaese_Fond 255;
BA_ "GenSigSendType" SG_ 1646 KL_Innen_Temp 0;
BA_ "GenSigStartValue" SG_ 1646 KL_Innen_Temp 254;
BA_ "GenSigSwitchedByIgnition" SG_ 1646 KL_Innen_Temp 0;
BA_ "Fehlerwert" SG_ 1646 KL_Innen_Temp 255;
BA_ "GenSigSendType" SG_ 1646 KL_Kompressorkupplung 3;
BA_ "GenSigSwitchedByIgnition" SG_ 1646 KL_Kompressorkupplung 0;
BA_ "GenSigSendType" SG_ 1646 KL_Magnetventil 3;
BA_ "GenSigSwitchedByIgnition" SG_ 1646 KL_Magnetventil 0;
BA_ "GenSigSendType" SG_ 1646 KL_Restwaerme_aktiv 3;
BA_ "GenSigSwitchedByIgnition" SG_ 1646 KL_Restwaerme_aktiv 0;
BA_ "GenSigSendType" SG_ 1646 KL_SIH_LEH_Verteilung_VL 3;
BA_ "GenSigSwitchedByIgnition" SG_ 1646 KL_SIH_LEH_Verteilung_VL 0;
BA_ "GenSigSendType" SG_ 1646 KL_SIH_LEH_Verteilung_VR 3;
BA_ "GenSigSwitchedByIgnition" SG_ 1646 KL_SIH_LEH_Verteilung_VR 0;
BA_ "GenSigSendType" SG_ 1646 KL_SIH_LEL_Verteilung_VL 3;
BA_ "GenSigSwitchedByIgnition" SG_ 1646 KL_SIH_LEL_Verteilung_VL 0;
BA_ "GenSigSendType" SG_ 1646 KL_SIH_LEL_Verteilung_VR 3;
BA_ "GenSigSwitchedByIgnition" SG_ 1646 KL_SIH_LEL_Verteilung_VR 0;
BA_ "GenSigSendType" SG_ 1646 KL_Solarluefter_aktiv 3;
BA_ "GenSigSwitchedByIgnition" SG_ 1646 KL_Solarluefter_aktiv 0;
BA_ "GenSigSendType" SG_ 1646 KL_Status_Beduftung 3;
BA_ "GenSigSwitchedByIgnition" SG_ 1646 KL_Status_Beduftung 0;
BA_ "GenSigSendType" SG_ 1646 KL_Status_Ionisator_Front 3;
BA_ "GenSigSwitchedByIgnition" SG_ 1646 KL_Status_Ionisator_Front 0;
BA_ "GenSigSendType" SG_ 1646 KL_STH_aktiv 3;
BA_ "GenSigSwitchedByIgnition" SG_ 1646 KL_STH_aktiv 0;
BA_ "GenSigSendType" SG_ 1646 KL_STH_Ansteuerung 3;
BA_ "GenSigSwitchedByIgnition" SG_ 1646 KL_STH_Ansteuerung 0;
BA_ "GenSigSendType" SG_ 1646 KL_STH_Betriebsdauer 3;
BA_ "GenSigSwitchedByIgnition" SG_ 1646 KL_STH_Betriebsdauer 0;
BA_ "GenSigSendType" SG_ 1646 KL_STH_Timer_Status 3;
BA_ "GenSigSwitchedByIgnition" SG_ 1646 KL_STH_Timer_Status 0;
BA_ "GenSigSendType" SG_ 1646 KL_STL_aktiv 3;
BA_ "GenSigSwitchedByIgnition" SG_ 1646 KL_STL_aktiv 0;
BA_ "GenSigSendType" SG_ 1646 KL_Umluft_Taste 3;
BA_ "GenSigSwitchedByIgnition" SG_ 1646 KL_Umluft_Taste 0;
BA_ "GenSigSendType" SG_ 1646 KL_WaPu 3;
BA_ "GenSigSwitchedByIgnition" SG_ 1646 KL_WaPu 0;
BA_ "GenSigSendType" SG_ 1663 KL_Absperrventil_Fond 3;
BA_ "GenSigSwitchedByIgnition" SG_ 1663 KL_Absperrventil_Fond 0;
BA_ "GenSigSendType" SG_ 1663 KL_Einheiten 3;
BA_ "GenSigSwitchedByIgnition" SG_ 1663 KL_Einheiten 0;
BA_ "GenSigSendType" SG_ 1663 KL_Fond_li_reduziert 3;
BA_ "GenSigSwitchedByIgnition" SG_ 1663 KL_Fond_li_reduziert 0;
BA_ "GenSigSendType" SG_ 1663 KL_Fond_re_reduziert 3;
BA_ "GenSigSwitchedByIgnition" SG_ 1663 KL_Fond_re_reduziert 0;
BA_ "GenSigSendType" SG_ 1663 KL_Fondbed_vorne_aktiv 3;
BA_ "GenSigSwitchedByIgnition" SG_ 1663 KL_Fondbed_vorne_aktiv 0;
BA_ "GenSigSendType" SG_ 1663 KL_Gebl_Verst_Abs_Modus 0;
BA_ "GenSigSwitchedByIgnition" SG_ 1663 KL_Gebl_Verst_Abs_Modus 0;
BA_ "GenSigSendType" SG_ 1663 KL_Geblaesespg_Fond 3;
BA_ "GenSigStartValue" SG_ 1663 KL_Geblaesespg_Fond 254;
BA_ "GenSigSwitchedByIgnition" SG_ 1663 KL_Geblaesespg_Fond 0;
BA_ "GenSigSendType" SG_ 1663 KL_Heizverbraucher_aus 3;
BA_ "GenSigSwitchedByIgnition" SG_ 1663 KL_Heizverbraucher_aus 0;
BA_ "GenSigSendType" SG_ 1663 KL_Heizverbraucher_Notaus 3;
BA_ "GenSigSwitchedByIgnition" SG_ 1663 KL_Heizverbraucher_Notaus 0;
BA_ "GenSigSendType" SG_ 1663 KL_ICO2_Sensor_defekt 3;
BA_ "GenSigSwitchedByIgnition" SG_ 1663 KL_ICO2_Sensor_defekt 0;
BA_ "GenSigSendType" SG_ 1663 KL_Kindersicherung 3;
BA_ "GenSigSwitchedByIgnition" SG_ 1663 KL_Kindersicherung 0;
BA_ "GenSigSendType" SG_ 1663 KL_Mod_Display_li 3;
BA_ "GenSigSwitchedByIgnition" SG_ 1663 KL_Mod_Display_li 0;
BA_ "GenSigSendType" SG_ 1663 KL_Mod_Display_re 3;
BA_ "GenSigSwitchedByIgnition" SG_ 1663 KL_Mod_Display_re 0;
BA_ "GenSigSendType" SG_ 1663 KL_SH_HL_Lastabschaltung 3;
BA_ "GenSigSwitchedByIgnition" SG_ 1663 KL_SH_HL_Lastabschaltung 0;
BA_ "GenSigSendType" SG_ 1663 KL_SH_HR_Lastabschaltung 3;
BA_ "GenSigSwitchedByIgnition" SG_ 1663 KL_SH_HR_Lastabschaltung 0;
BA_ "GenSigSendType" SG_ 1663 KL_Sollausblastemp_HL 3;
BA_ "GenSigStartValue" SG_ 1663 KL_Sollausblastemp_HL 1022;
BA_ "GenSigSwitchedByIgnition" SG_ 1663 KL_Sollausblastemp_HL 0;
BA_ "Fehlerwert" SG_ 1663 KL_Sollausblastemp_HL 1023;
BA_ "GenSigSendType" SG_ 1663 KL_Sollausblastemp_HR 3;
BA_ "GenSigStartValue" SG_ 1663 KL_Sollausblastemp_HR 1022;
BA_ "GenSigSwitchedByIgnition" SG_ 1663 KL_Sollausblastemp_HR 0;
BA_ "Fehlerwert" SG_ 1663 KL_Sollausblastemp_HR 1023;
BA_ "GenSigSendType" SG_ 1663 KL_Umluft 3;
BA_ "GenSigStartValue" SG_ 1663 KL_Umluft 254;
BA_ "GenSigSwitchedByIgnition" SG_ 1663 KL_Umluft 0;
BA_ "Fehlerwert" SG_ 1663 KL_Umluft 255;
BA_ "GenSigSendType" SG_ 1608 KL_AC_Fond_Soll 3;
BA_ "GenSigSwitchedByIgnition" SG_ 1608 KL_AC_Fond_Soll 0;
BA_ "GenSigSendType" SG_ 1608 KL_AUTO_HL_Soll 3;
BA_ "GenSigSwitchedByIgnition" SG_ 1608 KL_AUTO_HL_Soll 0;
BA_ "GenSigSendType" SG_ 1608 KL_AUTO_HR_Soll 3;
BA_ "GenSigSwitchedByIgnition" SG_ 1608 KL_AUTO_HR_Soll 0;
BA_ "GenSigSendType" SG_ 1608 KL_Befehlszaehler_FH 3;
BA_ "GenSigSwitchedByIgnition" SG_ 1608 KL_Befehlszaehler_FH 0;
BA_ "GenSigSendType" SG_ 1608 KL_Fondbedienung_aktiv 3;
BA_ "GenSigSwitchedByIgnition" SG_ 1608 KL_Fondbedienung_aktiv 0;
BA_ "GenSigSendType" SG_ 1608 KL_Luftmenge_HL_max 3;
BA_ "GenSigSwitchedByIgnition" SG_ 1608 KL_Luftmenge_HL_max 0;
BA_ "GenSigSendType" SG_ 1608 KL_Luftmenge_HL_offset 3;
BA_ "GenSigSwitchedByIgnition" SG_ 1608 KL_Luftmenge_HL_offset 0;
BA_ "GenSigSendType" SG_ 1608 KL_Luftmenge_HL_Soll 3;
BA_ "GenSigSwitchedByIgnition" SG_ 1608 KL_Luftmenge_HL_Soll 0;
BA_ "GenSigSendType" SG_ 1608 KL_Luftmenge_HR_max 3;
BA_ "GenSigSwitchedByIgnition" SG_ 1608 KL_Luftmenge_HR_max 0;
BA_ "GenSigSendType" SG_ 1608 KL_Luftmenge_HR_offset 3;
BA_ "GenSigSwitchedByIgnition" SG_ 1608 KL_Luftmenge_HR_offset 0;
BA_ "GenSigSendType" SG_ 1608 KL_Luftmenge_HR_Soll 3;
BA_ "GenSigSwitchedByIgnition" SG_ 1608 KL_Luftmenge_HR_Soll 0;
BA_ "GenSigSendType" SG_ 1608 KL_Luftverteilung_HL_Soll 3;
BA_ "GenSigSwitchedByIgnition" SG_ 1608 KL_Luftverteilung_HL_Soll 0;
BA_ "GenSigSendType" SG_ 1608 KL_Luftverteilung_HR_Soll 3;
BA_ "GenSigSwitchedByIgnition" SG_ 1608 KL_Luftverteilung_HR_Soll 0;
BA_ "GenSigSendType" SG_ 1608 KL_SH_HL_Soll 3;
BA_ "GenSigSwitchedByIgnition" SG_ 1608 KL_SH_HL_Soll 0;
BA_ "GenSigSendType" SG_ 1608 KL_SH_HR_Soll 3;
BA_ "GenSigSwitchedByIgnition" SG_ 1608 KL_SH_HR_Soll 0;
BA_ "GenSigSendType" SG_ 1608 KL_SL_HL_Soll 3;
BA_ "GenSigSwitchedByIgnition" SG_ 1608 KL_SL_HL_Soll 0;
BA_ "GenSigSendType" SG_ 1608 KL_SL_HR_Soll 3;
BA_ "GenSigSwitchedByIgnition" SG_ 1608 KL_SL_HR_Soll 0;
BA_ "GenSigSendType" SG_ 1608 KL_Status_Soll 3;
BA_ "GenSigSwitchedByIgnition" SG_ 1608 KL_Status_Soll 0;
BA_ "GenSigSendType" SG_ 1608 KL_Temp_HL_Soll 3;
BA_ "GenSigSwitchedByIgnition" SG_ 1608 KL_Temp_HL_Soll 0;
BA_ "GenSigSendType" SG_ 1608 KL_Temp_HR_Soll 3;
BA_ "GenSigSwitchedByIgnition" SG_ 1608 KL_Temp_HR_Soll 0;
BA_ "GenSigSendType" SG_ 949 KL_AC_Schalter 0;
BA_ "GenSigSwitchedByIgnition" SG_ 949 KL_AC_Schalter 0;
BA_ "GenSigSendType" SG_ 949 KL_Anf_KL 0;
BA_ "GenSigSwitchedByIgnition" SG_ 949 KL_Anf_KL 0;
BA_ "Fehlerwert" SG_ 949 KL_Anf_KL 255;
BA_ "GenSigSendType" SG_ 949 KL_Ausstattung_Klima 0;
BA_ "GenSigSwitchedByIgnition" SG_ 949 KL_Ausstattung_Klima 0;
BA_ "GenSigSendType" SG_ 949 KL_Charisma_FahrPr 0;
BA_ "GenSigSwitchedByIgnition" SG_ 949 KL_Charisma_FahrPr 0;
BA_ "GenSigSendType" SG_ 949 KL_Charisma_Status 0;
BA_ "GenSigSwitchedByIgnition" SG_ 949 KL_Charisma_Status 0;
BA_ "GenSigSendType" SG_ 949 KL_Drehz_Anh 0;
BA_ "GenSigSwitchedByIgnition" SG_ 949 KL_Drehz_Anh 0;
BA_ "GenSigSendType" SG_ 949 KL_el_Zuheizer_Stufe 0;
BA_ "GenSigSwitchedByIgnition" SG_ 949 KL_el_Zuheizer_Stufe 0;
BA_ "GenSigSendType" SG_ 949 KL_Freilauf_Info 0;
BA_ "GenSigSwitchedByIgnition" SG_ 949 KL_Freilauf_Info 0;
BA_ "GenSigSendType" SG_ 949 KL_Komp_Moment_alt 0;
BA_ "GenSigFuncType" SG_ 949 KL_Komp_Moment_alt 5;
BA_ "GenSigSwitchedByIgnition" SG_ 949 KL_Komp_Moment_alt 0;
BA_ "GenSigSendType" SG_ 949 KL_Kompressorkupplung_linear 0;
BA_ "GenSigStartValue" SG_ 949 KL_Kompressorkupplung_linear 254;
BA_ "GenSigSwitchedByIgnition" SG_ 949 KL_Kompressorkupplung_linear 0;
BA_ "GenSigSendType" SG_ 949 KL_Last_Kompr 0;
BA_ "GenSigSwitchedByIgnition" SG_ 949 KL_Last_Kompr 0;
BA_ "Fehlerwert" SG_ 949 KL_Last_Kompr 255;
BA_ "GenSigSendType" SG_ 949 KL_nachtr_Stopp_Anf 0;
BA_ "GenSigSwitchedByIgnition" SG_ 949 KL_nachtr_Stopp_Anf 0;
BA_ "GenSigSendType" SG_ 949 KL_Spannungs_Anf 0;
BA_ "GenSigSwitchedByIgnition" SG_ 949 KL_Spannungs_Anf 0;
BA_ "GenSigSendType" SG_ 949 KL_StartStopp_Info 0;
BA_ "GenSigSwitchedByIgnition" SG_ 949 KL_StartStopp_Info 0;
BA_ "GenSigSendType" SG_ 949 KL_T_Charge 0;
BA_ "GenSigSwitchedByIgnition" SG_ 949 KL_T_Charge 0;
BA_ "GenSigSendType" SG_ 949 KL_Thermomanagement 0;
BA_ "GenSigSwitchedByIgnition" SG_ 949 KL_Thermomanagement 0;
BA_ "GenSigSendType" SG_ 949 KL_Variante_Standheizung 0;
BA_ "GenSigSwitchedByIgnition" SG_ 949 KL_Variante_Standheizung 0;
BA_ "GenSigSendType" SG_ 949 KL_Vorwarn_Komp_ein 0;
BA_ "GenSigSwitchedByIgnition" SG_ 949 KL_Vorwarn_Komp_ein 0;
BA_ "GenSigSendType" SG_ 949 KL_Vorwarn_Zuheizer_ein 0;
BA_ "GenSigSwitchedByIgnition" SG_ 949 KL_Vorwarn_Zuheizer_ein 0;
BA_ "GenSigSendType" SG_ 949 KL_Zustand 0;
BA_ "GenSigSwitchedByIgnition" SG_ 949 KL_Zustand 0;
BA_ "GenSigActiveRepetitions" SG_ 1640 FSH_Taster 5;
BA_ "GenSigSendType" SG_ 1640 FSH_Taster 4;
BA_ "GenSigSwitchedByIgnition" SG_ 1640 FSH_Taster 0;
BA_ "GenSigActiveRepetitions" SG_ 1640 HSH_Taster 5;
BA_ "GenSigSendType" SG_ 1640 HSH_Taster 4;
BA_ "GenSigSwitchedByIgnition" SG_ 1640 HSH_Taster 0;
BA_ "GenSigSendType" SG_ 1640 KL_Beschlagsgefahr 3;
BA_ "GenSigSwitchedByIgnition" SG_ 1640 KL_Beschlagsgefahr 0;
BA_ "GenSigSendType" SG_ 1640 KL_Geblspng_Fond_Soll 0;
BA_ "GenSigSwitchedByIgnition" SG_ 1640 KL_Geblspng_Fond_Soll 0;
BA_ "Fehlerwert" SG_ 1640 KL_Geblspng_Fond_Soll 255;
BA_ "GenSigSendType" SG_ 1640 KL_Geblspng_Soll 0;
BA_ "GenSigSwitchedByIgnition" SG_ 1640 KL_Geblspng_Soll 0;
BA_ "Fehlerwert" SG_ 1640 KL_Geblspng_Soll 255;
BA_ "GenSigSendType" SG_ 1640 KL_I_Geblaese 0;
BA_ "GenSigSwitchedByIgnition" SG_ 1640 KL_I_Geblaese 0;
BA_ "Fehlerwert" SG_ 1640 KL_I_Geblaese 255;
BA_ "GenSigSendType" SG_ 1640 KL_Kompressorstrom_soll 0;
BA_ "GenSigStartValue" SG_ 1640 KL_Kompressorstrom_soll 1022;
BA_ "GenSigSwitchedByIgnition" SG_ 1640 KL_Kompressorstrom_soll 0;
BA_ "Fehlerwert" SG_ 1640 KL_Kompressorstrom_soll 1023;
BA_ "GenSigSendType" SG_ 1640 KL_LRH_Stufe 0;
BA_ "GenSigStartValue" SG_ 1640 KL_LRH_Stufe 1;
BA_ "GenSigSwitchedByIgnition" SG_ 1640 KL_LRH_Stufe 0;
BA_ "GenSigActiveRepetitions" SG_ 1640 KL_LRH_Taster 5;
BA_ "GenSigSendType" SG_ 1640 KL_LRH_Taster 4;
BA_ "GenSigSwitchedByIgnition" SG_ 1640 KL_LRH_Taster 0;
BA_ "GenSigSendType" SG_ 1640 KL_PTC_Verbauinfo 0;
BA_ "GenSigSwitchedByIgnition" SG_ 1640 KL_PTC_Verbauinfo 0;
BA_ "GenSigSendType" SG_ 1640 KL_SIH_Soll_li 3;
BA_ "GenSigSwitchedByIgnition" SG_ 1640 KL_SIH_Soll_li 0;
BA_ "GenSigSendType" SG_ 1640 KL_SIH_Soll_re 3;
BA_ "GenSigSwitchedByIgnition" SG_ 1640 KL_SIH_Soll_re 0;
BA_ "GenSigSendType" SG_ 1640 KL_SIL_Soll_li 3;
BA_ "GenSigSwitchedByIgnition" SG_ 1640 KL_SIL_Soll_li 0;
BA_ "GenSigSendType" SG_ 1640 KL_SIL_Soll_re 3;
BA_ "GenSigSwitchedByIgnition" SG_ 1640 KL_SIL_Soll_re 0;
BA_ "GenSigSendType" SG_ 1640 KL_Umluftklappe_Status 0;
BA_ "GenSigStartValue" SG_ 1640 KL_Umluftklappe_Status 14;
BA_ "GenSigSwitchedByIgnition" SG_ 1640 KL_Umluftklappe_Status 0;
BA_ "Fehlerwert" SG_ 1640 KL_Umluftklappe_Status 15;
BA_ "GenSigSendType" SG_ 1640 KL_Zuheizer_Freigabe 3;
BA_ "GenSigSwitchedByIgnition" SG_ 1640 KL_Zuheizer_Freigabe 0;
BA_ "GenSigSendType" SG_ 1640 KRH_Soll_li 3;
BA_ "GenSigSwitchedByIgnition" SG_ 1640 KRH_Soll_li 0;
BA_ "GenSigSendType" SG_ 1640 KRH_Soll_re 3;
BA_ "GenSigSwitchedByIgnition" SG_ 1640 KRH_Soll_re 0;
BA_ "GenSigSendType" SG_ 1441 KL_Frischluftklappe_Status 0;
BA_ "GenSigStartValue" SG_ 1441 KL_Frischluftklappe_Status 126;
BA_ "GenSigSwitchedByIgnition" SG_ 1441 KL_Frischluftklappe_Status 0;
BA_ "Fehlerwert" SG_ 1441 KL_Frischluftklappe_Status 127;
BA_ "GenSigSendType" SG_ 1441 KL_PTC_linear_Anf 0;
BA_ "GenSigSwitchedByIgnition" SG_ 1441 KL_PTC_linear_Anf 0;
BA_ "Fehlerwert" SG_ 1441 KL_PTC_linear_Anf 63;
BA_ "GenSigSendType" SG_ 1441 KL_SIH_LEH_Verteilung_HL 0;
BA_ "GenSigSwitchedByIgnition" SG_ 1441 KL_SIH_LEH_Verteilung_HL 0;
BA_ "GenSigSendType" SG_ 1441 KL_SIH_LEH_Verteilung_HR 0;
BA_ "GenSigSwitchedByIgnition" SG_ 1441 KL_SIH_LEH_Verteilung_HR 0;
BA_ "GenSigSendType" SG_ 1441 KL_SIH_Stufe_hl 0;
BA_ "GenSigSwitchedByIgnition" SG_ 1441 KL_SIH_Stufe_hl 0;
BA_ "GenSigSendType" SG_ 1441 KL_SIH_Stufe_hr 0;
BA_ "GenSigSwitchedByIgnition" SG_ 1441 KL_SIH_Stufe_hr 0;
BA_ "GenSigSendType" SG_ 1441 KL_SIL_LEL_Verteilung_HL 0;
BA_ "GenSigSwitchedByIgnition" SG_ 1441 KL_SIL_LEL_Verteilung_HL 0;
BA_ "GenSigSendType" SG_ 1441 KL_SIL_LEL_Verteilung_HR 0;
BA_ "GenSigSwitchedByIgnition" SG_ 1441 KL_SIL_LEL_Verteilung_HR 0;
BA_ "GenSigSendType" SG_ 1441 KL_SIL_Stufe_hl 0;
BA_ "GenSigSwitchedByIgnition" SG_ 1441 KL_SIL_Stufe_hl 0;
BA_ "GenSigSendType" SG_ 1441 KL_SIL_Stufe_hr 0;
BA_ "GenSigSwitchedByIgnition" SG_ 1441 KL_SIL_Stufe_hr 0;
BA_ "GenSigSendType" SG_ 1441 KL_Temp_Soll_hl 0;
BA_ "GenSigStartValue" SG_ 1441 KL_Temp_Soll_hl 31;
BA_ "GenSigSwitchedByIgnition" SG_ 1441 KL_Temp_Soll_hl 0;
BA_ "GenSigSendType" SG_ 1441 KL_Temp_Soll_hr 0;
BA_ "GenSigStartValue" SG_ 1441 KL_Temp_Soll_hr 31;
BA_ "GenSigSwitchedByIgnition" SG_ 1441 KL_Temp_Soll_hr 0;
BA_ "GenSigSendType" SG_ 1441 KL_Temp_Soll_vl 0;
BA_ "GenSigStartValue" SG_ 1441 KL_Temp_Soll_vl 31;
BA_ "GenSigSwitchedByIgnition" SG_ 1441 KL_Temp_Soll_vl 0;
BA_ "GenSigSendType" SG_ 1441 KL_Temp_Soll_vr 0;
BA_ "GenSigStartValue" SG_ 1441 KL_Temp_Soll_vr 31;
BA_ "GenSigSwitchedByIgnition" SG_ 1441 KL_Temp_Soll_vr 0;
BA_ "GenSigSendType" SG_ 2589283621 KL_ACmax_Aktiv 3;
BA_ "GenSigSwitchedByIgnition" SG_ 2589283621 KL_ACmax_Aktiv 0;
BA_ "GenSigSendType" SG_ 2589283621 KL_Defrost_Aktiv 3;
BA_ "GenSigSwitchedByIgnition" SG_ 2589283621 KL_Defrost_Aktiv 0;
BA_ "GenSigSendType" SG_ 2589283621 KL_ECO_Aktiv 3;
BA_ "GenSigSwitchedByIgnition" SG_ 2589283621 KL_ECO_Aktiv 0;
BA_ "GenSigSendType" SG_ 2589283621 KL_ECO_PRO_Aktiv 3;
BA_ "GenSigSwitchedByIgnition" SG_ 2589283621 KL_ECO_PRO_Aktiv 0;
BA_ "GenSigSendType" SG_ 2589283621 KL_Eps_Innen 3;
BA_ "GenSigStartValue" SG_ 2589283621 KL_Eps_Innen 254;
BA_ "GenSigSwitchedByIgnition" SG_ 2589283621 KL_Eps_Innen 0;
BA_ "Fehlerwert" SG_ 2589283621 KL_Eps_Innen 255;
BA_ "GenSigSendType" SG_ 2589283621 KL_FlHz_Soll_HL 3;
BA_ "GenSigSwitchedByIgnition" SG_ 2589283621 KL_FlHz_Soll_HL 0;
BA_ "GenSigSendType" SG_ 2589283621 KL_FlHz_Soll_HR 3;
BA_ "GenSigSwitchedByIgnition" SG_ 2589283621 KL_FlHz_Soll_HR 0;
BA_ "GenSigSendType" SG_ 2589283621 KL_FlHz_Soll_VL 3;
BA_ "GenSigSwitchedByIgnition" SG_ 2589283621 KL_FlHz_Soll_VL 0;
BA_ "GenSigSendType" SG_ 2589283621 KL_FlHz_Soll_VR 3;
BA_ "GenSigSwitchedByIgnition" SG_ 2589283621 KL_FlHz_Soll_VR 0;
BA_ "GenSigSendType" SG_ 2589283621 KL_Kundeneingriff_Geblaese 3;
BA_ "GenSigSwitchedByIgnition" SG_ 2589283621 KL_Kundeneingriff_Geblaese 0;
BA_ "GenSigSendType" SG_ 2589283621 KL_NV_Energie_Anf 3;
BA_ "GenSigStartValue" SG_ 2589283621 KL_NV_Energie_Anf 254;
BA_ "GenSigSwitchedByIgnition" SG_ 2589283621 KL_NV_Energie_Anf 0;
BA_ "Fehlerwert" SG_ 2589283621 KL_NV_Energie_Anf 255;
BA_ "GenSigSendType" SG_ 2589283621 KL_QBit_Sonnenintensitaet 3;
BA_ "GenSigStartValue" SG_ 2589283621 KL_QBit_Sonnenintensitaet 1;
BA_ "GenSigSwitchedByIgnition" SG_ 2589283621 KL_QBit_Sonnenintensitaet 0;
BA_ "GenSigSendType" SG_ 2589283621 KL_Sonnenintensitaet 0;
BA_ "GenSigSwitchedByIgnition" SG_ 2589283621 KL_Sonnenintensitaet 0;
BA_ "Fehlerwert" SG_ 2589283621 KL_Sonnenintensitaet 255;
BA_ "GenSigSendType" SG_ 2589283621 KL_Status_Klimastil 3;
BA_ "GenSigSwitchedByIgnition" SG_ 2589283621 KL_Status_Klimastil 0;
BA_ "GenSigSendType" SG_ 2589283621 KL_Thermischer_Bedarf 3;
BA_ "GenSigStartValue" SG_ 2589283621 KL_Thermischer_Bedarf 6;
BA_ "GenSigSwitchedByIgnition" SG_ 2589283621 KL_Thermischer_Bedarf 0;
BA_ "Fehlerwert" SG_ 2589283621 KL_Thermischer_Bedarf 7;
BA_ "GenSigSendType" SG_ 2589283621 KL_Umluft_Connect_status 3;
BA_ "GenSigSwitchedByIgnition" SG_ 2589283621 KL_Umluft_Connect_status 0;
BA_ "GenSigSendType" SG_ 2589283621 KL_ZR_Anforderung 3;
BA_ "GenSigSwitchedByIgnition" SG_ 2589283621 KL_ZR_Anforderung 0;
BA_ "GenSigSendType" SG_ 992 KL_Fehler_Fussraum_Klappen 0;
BA_ "GenSigSwitchedByIgnition" SG_ 992 KL_Fehler_Fussraum_Klappen 0;
BA_ "GenSigSendType" SG_ 992 KL_Fehler_Temp_Klappen 0;
BA_ "GenSigSwitchedByIgnition" SG_ 992 KL_Fehler_Temp_Klappen 0;
BA_ "GenSigSendType" SG_ 992 KL_Fehler_Temp_MA_Klappen 0;
BA_ "GenSigSwitchedByIgnition" SG_ 992 KL_Fehler_Temp_MA_Klappen 0;
BA_ "GenSigSendType" SG_ 992 KL_Fehler_Umluft 0;
BA_ "GenSigSwitchedByIgnition" SG_ 992 KL_Fehler_Umluft 0;
BA_ "GenSigSendType" SG_ 992 KL_Fond_Absperrventil 0;
BA_ "GenSigSwitchedByIgnition" SG_ 992 KL_Fond_Absperrventil 0;
BA_ "GenSigSendType" SG_ 992 KL_Fond_Fuss_Temp_hl 0;
BA_ "GenSigStartValue" SG_ 992 KL_Fond_Fuss_Temp_hl 1022;
BA_ "GenSigSwitchedByIgnition" SG_ 992 KL_Fond_Fuss_Temp_hl 0;
BA_ "Fehlerwert" SG_ 992 KL_Fond_Fuss_Temp_hl 1023;
BA_ "GenSigSendType" SG_ 992 KL_Fond_Fuss_Temp_hr 0;
BA_ "GenSigStartValue" SG_ 992 KL_Fond_Fuss_Temp_hr 1022;
BA_ "GenSigSwitchedByIgnition" SG_ 992 KL_Fond_Fuss_Temp_hr 0;
BA_ "Fehlerwert" SG_ 992 KL_Fond_Fuss_Temp_hr 1023;
BA_ "GenSigSendType" SG_ 992 KL_Fond_KD_Fehler 0;
BA_ "GenSigSwitchedByIgnition" SG_ 992 KL_Fond_KD_Fehler 0;
BA_ "GenSigSendType" SG_ 992 KL_MA_Temp_hl 0;
BA_ "GenSigStartValue" SG_ 992 KL_MA_Temp_hl 1022;
BA_ "GenSigSwitchedByIgnition" SG_ 992 KL_MA_Temp_hl 0;
BA_ "Fehlerwert" SG_ 992 KL_MA_Temp_hl 1023;
BA_ "GenSigSendType" SG_ 992 KL_MA_Temp_hr 0;
BA_ "GenSigStartValue" SG_ 992 KL_MA_Temp_hr 1022;
BA_ "GenSigSwitchedByIgnition" SG_ 992 KL_MA_Temp_hr 0;
BA_ "Fehlerwert" SG_ 992 KL_MA_Temp_hr 1023;
BA_ "GenSigSendType" SG_ 992 KL_RAB 0;
BA_ "GenSigSwitchedByIgnition" SG_ 992 KL_RAB 0;
BA_ "GenSigSendType" SG_ 992 KL_SH_Soll_hl 0;
BA_ "GenSigSwitchedByIgnition" SG_ 992 KL_SH_Soll_hl 0;
BA_ "GenSigSendType" SG_ 992 KL_SH_Soll_hr 0;
BA_ "GenSigSwitchedByIgnition" SG_ 992 KL_SH_Soll_hr 0;
BA_ "GenSigSendType" SG_ 992 KL_SIH_Takt_hl 0;
BA_ "GenSigSwitchedByIgnition" SG_ 992 KL_SIH_Takt_hl 0;
BA_ "GenSigSendType" SG_ 992 KL_SIH_Takt_hr 0;
BA_ "GenSigSwitchedByIgnition" SG_ 992 KL_SIH_Takt_hr 0;
BA_ "GenSigSendType" SG_ 992 KL_SL_Soll_hl 0;
BA_ "GenSigSwitchedByIgnition" SG_ 992 KL_SL_Soll_hl 0;
BA_ "GenSigSendType" SG_ 992 KL_SL_Soll_hr 0;
BA_ "GenSigSwitchedByIgnition" SG_ 992 KL_SL_Soll_hr 0;
BA_ "GenSigSendType" SG_ 1712 FS_Luftfeuchte_rel 0;
BA_ "Fehlerwert" SG_ 1712 FS_Luftfeuchte_rel 255;
BA_ "GenSigMissingSourceValue" SG_ 1712 FS_Luftfeuchte_rel 255;
BA_ "GenSigSendType" SG_ 1712 FS_ResponseError 0;
BA_ "GenSigSwitchedByIgnition" SG_ 1712 FS_ResponseError 0;
BA_ "Fehlerwert" SG_ 1712 FS_ResponseError 1;
BA_ "GenSigSendType" SG_ 1712 FS_Taupunkt 0;
BA_ "Fehlerwert" SG_ 1712 FS_Taupunkt 1023;
BA_ "GenSigMissingSourceValue" SG_ 1712 FS_Taupunkt 1023;
BA_ "GenSigSendType" SG_ 1712 FS_Temp_Scheibe 0;
BA_ "Fehlerwert" SG_ 1712 FS_Temp_Scheibe 1023;
BA_ "GenSigMissingSourceValue" SG_ 1712 FS_Temp_Scheibe 1023;
BA_ "GenSigSendType" SG_ 1712 FS_Temp_Sensor 0;
BA_ "Fehlerwert" SG_ 1712 FS_Temp_Sensor 255;
BA_ "GenSigMissingSourceValue" SG_ 1712 FS_Temp_Sensor 255;
BA_ "GenSigSendType" SG_ 1505 BCM1_Aussen_Temp_ungef 0;
BA_ "GenSigStartValue" SG_ 1505 BCM1_Aussen_Temp_ungef 254;
BA_ "GenSigSwitchedByIgnition" SG_ 1505 BCM1_Aussen_Temp_ungef 0;
BA_ "Fehlerwert" SG_ 1505 BCM1_Aussen_Temp_ungef 255;
BA_ "GenSigSendType" SG_ 1505 BCM1_FStatus_Aussentemp_ungef 0;
BA_ "GenSigStartValue" SG_ 1505 BCM1_FStatus_Aussentemp_ungef 1;
BA_ "GenSigSwitchedByIgnition" SG_ 1505 BCM1_FStatus_Aussentemp_ungef 0;
BA_ "GenSigSendType" SG_ 1505 BCM1_Kompressorstrom_ist 0;
BA_ "GenSigStartValue" SG_ 1505 BCM1_Kompressorstrom_ist 254;
BA_ "GenSigSwitchedByIgnition" SG_ 1505 BCM1_Kompressorstrom_ist 0;
BA_ "Fehlerwert" SG_ 1505 BCM1_Kompressorstrom_ist 255;
BA_ "GenSigSendType" SG_ 1505 BCM1_OBD_FStatus_ATemp 0;
BA_ "GenSigSwitchedByIgnition" SG_ 1505 BCM1_OBD_FStatus_ATemp 0;
BA_ "GenSigSendType" SG_ 1505 BCM1_PTC_stufig_Status 0;
BA_ "GenSigStartValue" SG_ 1505 BCM1_PTC_stufig_Status 6;
BA_ "GenSigSwitchedByIgnition" SG_ 1505 BCM1_PTC_stufig_Status 0;
BA_ "Fehlerwert" SG_ 1505 BCM1_PTC_stufig_Status 7;
BA_ "GenSigSendType" SG_ 1505 BCM_Heizungsabsperrventil_Status 0;
BA_ "GenSigStartValue" SG_ 1505 BCM_Heizungsabsperrventil_Status 2;
BA_ "GenSigSwitchedByIgnition" SG_ 1505 BCM_Heizungsabsperrventil_Status 0;
BA_ "Fehlerwert" SG_ 1505 BCM_Heizungsabsperrventil_Status 3;
BA_ "GenSigSendType" SG_ 1505 BCM_Heizungspumpe_Status 0;
BA_ "GenSigStartValue" SG_ 1505 BCM_Heizungspumpe_Status 2;
BA_ "GenSigSwitchedByIgnition" SG_ 1505 BCM_Heizungspumpe_Status 0;
BA_ "Fehlerwert" SG_ 1505 BCM_Heizungspumpe_Status 3;
BA_ "GenSigSendType" SG_ 1505 BCM_Kompressorkupplung_Status 0;
BA_ "GenSigStartValue" SG_ 1505 BCM_Kompressorkupplung_Status 2;
BA_ "GenSigSwitchedByIgnition" SG_ 1505 BCM_Kompressorkupplung_Status 0;
BA_ "Fehlerwert" SG_ 1505 BCM_Kompressorkupplung_Status 3;
BA_ "GenSigSendType" SG_ 605 KLR_01_BZ 0;
BA_ "GenSigFuncType" SG_ 605 KLR_01_BZ 1;
BA_ "GenSigSwitchedByIgnition" SG_ 605 KLR_01_BZ 0;
BA_ "GenSigSendType" SG_ 605 KLR_01_CRC 0;
BA_ "GenSigFuncType" SG_ 605 KLR_01_CRC 2;
BA_ "GenSigSwitchedByIgnition" SG_ 605 KLR_01_CRC 0;
BA_ "GenSigSendType" SG_ 605 KLR_Fehler 0;
BA_ "GenSigSwitchedByIgnition" SG_ 605 KLR_Fehler 0;
BA_ "Fehlerwert" SG_ 605 KLR_Fehler 1;
BA_ "GenSigSwitchedByIgnition" SG_ 605 KLR_Fehler_Codierung 0;
BA_ "Fehlerwert" SG_ 605 KLR_Fehler_Codierung 1;
BA_ "GenSigSendType" SG_ 605 KLR_Lokalaktiv 0;
BA_ "GenSigSwitchedByIgnition" SG_ 605 KLR_Lokalaktiv 0;
BA_ "GenSigSendType" SG_ 605 KLR_ResponseError 0;
BA_ "GenSigSwitchedByIgnition" SG_ 605 KLR_ResponseError 0;
BA_ "Fehlerwert" SG_ 605 KLR_ResponseError 1;
BA_ "GenSigSendType" SG_ 605 KLR_Touchauswertung 0;
BA_ "GenSigStartValue" SG_ 605 KLR_Touchauswertung 14;
BA_ "GenSigSwitchedByIgnition" SG_ 605 KLR_Touchauswertung 0;
BA_ "GenSigSendType" SG_ 605 KLR_Touchintensitaet_1 0;
BA_ "GenSigStartValue" SG_ 605 KLR_Touchintensitaet_1 254;
BA_ "GenSigSwitchedByIgnition" SG_ 605 KLR_Touchintensitaet_1 0;
BA_ "Fehlerwert" SG_ 605 KLR_Touchintensitaet_1 255;
BA_ "GenSigSendType" SG_ 605 KLR_Touchintensitaet_2 0;
BA_ "GenSigStartValue" SG_ 605 KLR_Touchintensitaet_2 254;
BA_ "GenSigSwitchedByIgnition" SG_ 605 KLR_Touchintensitaet_2 0;
BA_ "Fehlerwert" SG_ 605 KLR_Touchintensitaet_2 255;
BA_ "GenSigSendType" SG_ 605 KLR_Touchintensitaet_3 0;
BA_ "GenSigStartValue" SG_ 605 KLR_Touchintensitaet_3 254;
BA_ "GenSigSwitchedByIgnition" SG_ 605 KLR_Touchintensitaet_3 0;
BA_ "Fehlerwert" SG_ 605 KLR_Touchintensitaet_3 255;
BA_ "GenSigSendType" SG_ 2549088398 BedienDisp_vo_Abschaltstufe 0;
BA_ "GenSigSwitchedByIgnition" SG_ 2549088398 BedienDisp_vo_Abschaltstufe 0;
BA_ "GenSigSendType" SG_ 2549088398 BedienDisp_vo_KD_Fehler 0;
BA_ "GenSigSwitchedByIgnition" SG_ 2549088398 BedienDisp_vo_KD_Fehler 0;
BA_ "GenSigSendType" SG_ 2549088398 BedienDisp_vo_KompSchutz 0;
BA_ "GenSigSwitchedByIgnition" SG_ 2549088398 BedienDisp_vo_KompSchutz 0;
BA_ "GenSigSendType" SG_ 2549088398 BedienDisp_vo_Nachlauftyp 0;
BA_ "GenSigStartValue" SG_ 2549088398 BedienDisp_vo_Nachlauftyp 2;
BA_ "GenSigSwitchedByIgnition" SG_ 2549088398 BedienDisp_vo_Nachlauftyp 0;
BA_ "GenSigSendType" SG_ 2549088398 BedienDisp_vo_SNI 0;
BA_ "GenSigStartValue" SG_ 2549088398 BedienDisp_vo_SNI 142;
BA_ "GenSigSwitchedByIgnition" SG_ 2549088398 BedienDisp_vo_SNI 0;
BA_ "GenSigSendType" SG_ 2549088398 BedienDisp_vo_Transport_Mode 0;
BA_ "GenSigSwitchedByIgnition" SG_ 2549088398 BedienDisp_vo_Transport_Mode 0;
BA_ "GenSigSendType" SG_ 2549088398 KN_BedienDisp_v_BusKnockOut 0;
BA_ "GenSigSwitchedByIgnition" SG_ 2549088398 KN_BedienDisp_v_BusKnockOut 0;
BA_ "GenSigSendType" SG_ 2549088398 KN_BedienDisp_v_BusKnockOutTimer 0;
BA_ "GenSigSwitchedByIgnition" SG_ 2549088398 KN_BedienDisp_v_BusKnockOutTimer 0;
BA_ "GenSigSendType" SG_ 2549088398 KN_BedienDisp_v_ECUKnockOut 0;
BA_ "GenSigSwitchedByIgnition" SG_ 2549088398 KN_BedienDisp_v_ECUKnockOut 0;
BA_ "GenSigSendType" SG_ 2549088398 KN_BedienDisp_v_ECUKnockOutTimer 0;
BA_ "GenSigSwitchedByIgnition" SG_ 2549088398 KN_BedienDisp_v_ECUKnockOutTimer 0;
BA_ "GenSigSendType" SG_ 2549088398 NM_BedienDisp_vo_Wakeup 0;
BA_ "GenSigSwitchedByIgnition" SG_ 2549088398 NM_BedienDisp_vo_Wakeup 0;
BA_ "GenSigSendType" SG_ 2549088398 NMH_BedienDisp_vo_Lokalaktiv 0;
BA_ "GenSigSwitchedByIgnition" SG_ 2549088398 NMH_BedienDisp_vo_Lokalaktiv 0;
BA_ "GenSigSendType" SG_ 2549088398 NMH_BedienDisp_vo_Subsystemaktiv 0;
BA_ "GenSigSwitchedByIgnition" SG_ 2549088398 NMH_BedienDisp_vo_Subsystemaktiv 0;
BA_ "GenSigSendType" SG_ 2549088403 BedienSG_hi_Abschaltstufe 0;
BA_ "GenSigSwitchedByIgnition" SG_ 2549088403 BedienSG_hi_Abschaltstufe 0;
BA_ "GenSigSendType" SG_ 2549088403 BedienSG_hi_KD_Fehler 0;
BA_ "GenSigSwitchedByIgnition" SG_ 2549088403 BedienSG_hi_KD_Fehler 0;
BA_ "GenSigSendType" SG_ 2549088403 BedienSG_hi_KompSchutz 0;
BA_ "GenSigSwitchedByIgnition" SG_ 2549088403 BedienSG_hi_KompSchutz 0;
BA_ "GenSigSendType" SG_ 2549088403 BedienSG_hi_Nachlauftyp 0;
BA_ "GenSigStartValue" SG_ 2549088403 BedienSG_hi_Nachlauftyp 2;
BA_ "GenSigSwitchedByIgnition" SG_ 2549088403 BedienSG_hi_Nachlauftyp 0;
BA_ "GenSigSendType" SG_ 2549088403 BedienSG_hi_SNI 0;
BA_ "GenSigStartValue" SG_ 2549088403 BedienSG_hi_SNI 147;
BA_ "GenSigSwitchedByIgnition" SG_ 2549088403 BedienSG_hi_SNI 0;
BA_ "GenSigSendType" SG_ 2549088403 BedienSG_hi_Transport_Mode 0;
BA_ "GenSigSwitchedByIgnition" SG_ 2549088403 BedienSG_hi_Transport_Mode 0;
BA_ "GenSigSendType" SG_ 2549088403 KN_BedienSG_hi_BusKnockOut 0;
BA_ "GenSigSwitchedByIgnition" SG_ 2549088403 KN_BedienSG_hi_BusKnockOut 0;
BA_ "GenSigSendType" SG_ 2549088403 KN_BedienSG_hi_BusKnockOutTimer 0;
BA_ "GenSigSwitchedByIgnition" SG_ 2549088403 KN_BedienSG_hi_BusKnockOutTimer 0;
BA_ "GenSigSendType" SG_ 2549088403 KN_BedienSG_hi_ECUKnockOut 0;
BA_ "GenSigSwitchedByIgnition" SG_ 2549088403 KN_BedienSG_hi_ECUKnockOut 0;
BA_ "GenSigSendType" SG_ 2549088403 KN_BedienSG_hi_ECUKnockOutTimer 0;
BA_ "GenSigSwitchedByIgnition" SG_ 2549088403 KN_BedienSG_hi_ECUKnockOutTimer 0;
BA_ "GenSigSendType" SG_ 2549088403 NMH_BedienSG_hi_Lokalaktiv 0;
BA_ "GenSigSwitchedByIgnition" SG_ 2549088403 NMH_BedienSG_hi_Lokalaktiv 0;
BA_ "GenSigSendType" SG_ 2549088403 NMH_BedienSG_hi_Subsystemaktiv 0;
BA_ "GenSigSwitchedByIgnition" SG_ 2549088403 NMH_BedienSG_hi_Subsystemaktiv 0;
BA_ "GenSigSendType" SG_ 2549088403 NMH_BedienSG_hi_Wakeup 0;
BA_ "GenSigStartValue" SG_ 2549088403 NMH_BedienSG_hi_Wakeup 2;
BA_ "NWM-WakeupAllowed" SG_ 2549088403 NMH_BedienSG_hi_Wakeup 1;
BA_ "GenSigSendType" SG_ 2549088442 DDA_Abschaltstufe 0;
BA_ "GenSigSendType" SG_ 2549088442 DDA_KD_Fehler 0;
BA_ "GenSigSwitchedByIgnition" SG_ 2549088442 DDA_KD_Fehler 0;
BA_ "GenSigSendType" SG_ 2549088442 DDA_KompSchutz 0;
BA_ "GenSigSwitchedByIgnition" SG_ 2549088442 DDA_KompSchutz 0;
BA_ "GenSigSendType" SG_ 2549088442 DDA_Nachlauftyp 0;
BA_ "GenSigStartValue" SG_ 2549088442 DDA_Nachlauftyp 2;
BA_ "GenSigSwitchedByIgnition" SG_ 2549088442 DDA_Nachlauftyp 0;
BA_ "GenSigSendType" SG_ 2549088442 DDA_SNI 0;
BA_ "GenSigStartValue" SG_ 2549088442 DDA_SNI 186;
BA_ "GenSigSwitchedByIgnition" SG_ 2549088442 DDA_SNI 0;
BA_ "GenSigSendType" SG_ 2549088442 DDA_Transport_Mode 0;
BA_ "GenSigSwitchedByIgnition" SG_ 2549088442 DDA_Transport_Mode 0;
BA_ "GenSigSendType" SG_ 2549088442 KN_DDA_BusKnockOutTimer 0;
BA_ "GenSigSwitchedByIgnition" SG_ 2549088442 KN_DDA_BusKnockOutTimer 0;
BA_ "GenSigSendType" SG_ 2549088442 NM_DDA_Lokalaktiv 0;
BA_ "GenSigSwitchedByIgnition" SG_ 2549088442 NM_DDA_Lokalaktiv 0;
BA_ "GenSigSendType" SG_ 2549088442 NM_DDA_Wakeup 0;
BA_ "GenSigSwitchedByIgnition" SG_ 2549088442 NM_DDA_Wakeup 0;
BA_ "GenSigSendType" SG_ 2549088272 Gateway_Abschaltstufe 0;
BA_ "GenSigSwitchedByIgnition" SG_ 2549088272 Gateway_Abschaltstufe 0;
BA_ "GenSigSendType" SG_ 2549088272 Gateway_KompSchutz 0;
BA_ "GenSigSwitchedByIgnition" SG_ 2549088272 Gateway_KompSchutz 0;
BA_ "GenSigSendType" SG_ 2549088272 Gateway_Matrix_Generation 0;
BA_ "GenSigSwitchedByIgnition" SG_ 2549088272 Gateway_Matrix_Generation 0;
BA_ "GenSigSendType" SG_ 2549088272 Gateway_Matrix_Version 0;
BA_ "GenSigSwitchedByIgnition" SG_ 2549088272 Gateway_Matrix_Version 0;
BA_ "GenSigSendType" SG_ 2549088272 Gateway_Nachlauftyp 0;
BA_ "GenSigStartValue" SG_ 2549088272 Gateway_Nachlauftyp 2;
BA_ "GenSigSwitchedByIgnition" SG_ 2549088272 Gateway_Nachlauftyp 0;
BA_ "GenSigSendType" SG_ 2549088272 Gateway_SNI 0;
BA_ "GenSigStartValue" SG_ 2549088272 Gateway_SNI 16;
BA_ "GenSigSwitchedByIgnition" SG_ 2549088272 Gateway_SNI 0;
BA_ "GenSigSendType" SG_ 2549088272 Gateway_Transport_Mode 0;
BA_ "GenSigSwitchedByIgnition" SG_ 2549088272 Gateway_Transport_Mode 0;
BA_ "GenSigSendType" SG_ 2549088272 GW_KD_Fehler 0;
BA_ "GenSigSendType" SG_ 2549088272 NM_Gateway_Lokalaktiv 0;
BA_ "GenSigSwitchedByIgnition" SG_ 2549088272 NM_Gateway_Lokalaktiv 0;
BA_ "GenSigSendType" SG_ 2549088272 NM_Gateway_Subsystemaktiv 0;
BA_ "GenSigSendType" SG_ 2549088272 NM_Gateway_Wakeup 0;
BA_ "NWM-WakeupAllowed" SG_ 2549088272 NM_Gateway_Wakeup 1;
BA_ "GenSigSwitchedByIgnition" SG_ 2549088272 NM_Gateway_Wakeup 0;
BA_ "GenSigSendType" SG_ 2549088355 GM_Abschaltstufe 0;
BA_ "GenSigSendType" SG_ 2549088355 GM_KD_Fehler 0;
BA_ "GenSigSendType" SG_ 2549088355 GM_KompSchutz 0;
BA_ "GenSigSendType" SG_ 2549088355 GM_Lokalaktiv 0;
BA_ "GenSigSendType" SG_ 2549088355 GM_Nachlauftyp 0;
BA_ "GenSigSendType" SG_ 2549088355 GM_SNI 0;
BA_ "GenSigStartValue" SG_ 2549088355 GM_SNI 99;
BA_ "GenSigSendType" SG_ 2549088355 GM_Subsystemaktiv 0;
BA_ "GenSigSendType" SG_ 2549088355 GM_Transport_Mode 0;
BA_ "GenSigSendType" SG_ 2549088355 NM_GM_Wakeup 0;
BA_ "NWM-WakeupAllowed" SG_ 2549088355 NM_GM_Wakeup 1;
BA_ "GenSigSendType" SG_ 2549088371 Info_El_Abschaltstufe 0;
BA_ "GenSigSwitchedByIgnition" SG_ 2549088371 Info_El_Abschaltstufe 0;
BA_ "GenSigSendType" SG_ 2549088371 Info_El_KD_Fehler 0;
BA_ "GenSigSwitchedByIgnition" SG_ 2549088371 Info_El_KD_Fehler 0;
BA_ "GenSigSendType" SG_ 2549088371 Info_El_KompSchutz 0;
BA_ "GenSigSwitchedByIgnition" SG_ 2549088371 Info_El_KompSchutz 0;
BA_ "GenSigSendType" SG_ 2549088371 Info_El_Nachlauftyp 0;
BA_ "GenSigStartValue" SG_ 2549088371 Info_El_Nachlauftyp 2;
BA_ "GenSigSwitchedByIgnition" SG_ 2549088371 Info_El_Nachlauftyp 0;
BA_ "GenSigSendType" SG_ 2549088371 Info_El_SNI 0;
BA_ "GenSigStartValue" SG_ 2549088371 Info_El_SNI 115;
BA_ "GenSigSwitchedByIgnition" SG_ 2549088371 Info_El_SNI 0;
BA_ "GenSigSendType" SG_ 2549088371 Info_El_Transport_Mode 0;
BA_ "GenSigSwitchedByIgnition" SG_ 2549088371 Info_El_Transport_Mode 0;
BA_ "GenSigSendType" SG_ 2549088371 KN_Info_El_BusKnockOutTimer 0;
BA_ "GenSigStartValue" SG_ 2549088371 KN_Info_El_BusKnockOutTimer 255;
BA_ "GenSigSwitchedByIgnition" SG_ 2549088371 KN_Info_El_BusKnockOutTimer 0;
BA_ "GenSigSendType" SG_ 2549088371 NM_Info_El_Lokalaktiv 0;
BA_ "GenSigSwitchedByIgnition" SG_ 2549088371 NM_Info_El_Lokalaktiv 0;
BA_ "GenSigSendType" SG_ 2549088371 NM_Info_El_Subsystemaktiv 0;
BA_ "GenSigSwitchedByIgnition" SG_ 2549088371 NM_Info_El_Subsystemaktiv 0;
BA_ "GenSigSendType" SG_ 2549088371 NM_Info_El_Wakeup 0;
BA_ "NWM-WakeupAllowed" SG_ 2549088371 NM_Info_El_Wakeup 1;
BA_ "GenSigSwitchedByIgnition" SG_ 2549088371 NM_Info_El_Wakeup 0;
BA_ "GenSigSendType" SG_ 2549088258 NM_Sekundaer_02_Lokalaktiv 0;
BA_ "GenSigSwitchedByIgnition" SG_ 2549088258 NM_Sekundaer_02_Lokalaktiv 0;
BA_ "GenSigSendType" SG_ 2549088258 NM_Sekundaer_02_Subsystemaktiv 0;
BA_ "GenSigSwitchedByIgnition" SG_ 2549088258 NM_Sekundaer_02_Subsystemaktiv 0;
BA_ "GenSigSendType" SG_ 2549088258 NM_Sekundaer_02_Wakeup 0;
BA_ "GenSigSwitchedByIgnition" SG_ 2549088258 NM_Sekundaer_02_Wakeup 0;
BA_ "GenSigSendType" SG_ 2549088258 Sekundaer_02_Abschaltstufe 0;
BA_ "GenSigSwitchedByIgnition" SG_ 2549088258 Sekundaer_02_Abschaltstufe 0;
BA_ "GenSigSendType" SG_ 2549088258 Sekundaer_02_KD_Fehler 0;
BA_ "GenSigSwitchedByIgnition" SG_ 2549088258 Sekundaer_02_KD_Fehler 0;
BA_ "GenSigSendType" SG_ 2549088258 Sekundaer_02_KompSchutz 0;
BA_ "GenSigSwitchedByIgnition" SG_ 2549088258 Sekundaer_02_KompSchutz 0;
BA_ "GenSigSendType" SG_ 2549088258 Sekundaer_02_Nachlauftyp 0;
BA_ "GenSigStartValue" SG_ 2549088258 Sekundaer_02_Nachlauftyp 2;
BA_ "GenSigSwitchedByIgnition" SG_ 2549088258 Sekundaer_02_Nachlauftyp 0;
BA_ "GenSigSendType" SG_ 2549088258 Sekundaer_02_SNI 0;
BA_ "GenSigStartValue" SG_ 2549088258 Sekundaer_02_SNI 2;
BA_ "GenSigSwitchedByIgnition" SG_ 2549088258 Sekundaer_02_SNI 0;
BA_ "GenSigSendType" SG_ 2549088258 Sekundaer_02_Transport_Mode 0;
BA_ "GenSigSwitchedByIgnition" SG_ 2549088258 Sekundaer_02_Transport_Mode 0;
BA_ "GenSigSendType" SG_ 779 KBI_ABS_Lampe 0;
BA_ "GenSigSwitchedByIgnition" SG_ 779 KBI_ABS_Lampe 0;
BA_ "GenSigSendType" SG_ 779 KBI_Airbag_Lampe 0;
BA_ "GenSigSwitchedByIgnition" SG_ 779 KBI_Airbag_Lampe 0;
BA_ "GenSigSendType" SG_ 779 KBI_angez_Geschw 0;
BA_ "GenSigSwitchedByIgnition" SG_ 779 KBI_angez_Geschw 0;
BA_ "GenSigSendType" SG_ 779 KBI_Anzeigefehler_LDW 0;
BA_ "GenSigSwitchedByIgnition" SG_ 779 KBI_Anzeigefehler_LDW 0;
BA_ "GenSigSendType" SG_ 779 KBI_Anzeigefehler_NV 0;
BA_ "GenSigSwitchedByIgnition" SG_ 779 KBI_Anzeigefehler_NV 0;
BA_ "GenSigSendType" SG_ 779 KBI_Anzeigefehler_SWA 0;
BA_ "GenSigSwitchedByIgnition" SG_ 779 KBI_Anzeigefehler_SWA 0;
BA_ "GenSigSendType" SG_ 779 KBI_Anzeigestatus_ACC 0;
BA_ "GenSigSwitchedByIgnition" SG_ 779 KBI_Anzeigestatus_ACC 0;
BA_ "GenSigSendType" SG_ 779 KBI_Anzeigestatus_GRA 0;
BA_ "GenSigSwitchedByIgnition" SG_ 779 KBI_Anzeigestatus_GRA 0;
BA_ "Fehlerwert" SG_ 779 KBI_Anzeigestatus_GRA 3;
BA_ "GenSigSendType" SG_ 779 KBI_Anzeigestatus_LIM 0;
BA_ "GenSigSwitchedByIgnition" SG_ 779 KBI_Anzeigestatus_LIM 0;
BA_ "Fehlerwert" SG_ 779 KBI_Anzeigestatus_LIM 3;
BA_ "GenSigSendType" SG_ 779 KBI_ARA_in_Anzeige 0;
BA_ "GenSigSwitchedByIgnition" SG_ 779 KBI_ARA_in_Anzeige 0;
BA_ "GenSigSendType" SG_ 779 KBI_BKL_Lampe 0;
BA_ "GenSigSwitchedByIgnition" SG_ 779 KBI_BKL_Lampe 0;
BA_ "GenSigSendType" SG_ 779 KBI_Einheit_Tacho 0;
BA_ "GenSigSwitchedByIgnition" SG_ 779 KBI_Einheit_Tacho 0;
BA_ "GenSigSendType" SG_ 779 KBI_ESP_Lampe 0;
BA_ "GenSigSwitchedByIgnition" SG_ 779 KBI_ESP_Lampe 0;
BA_ "GenSigSendType" SG_ 779 KBI_Fehler_Anzeige_ACC 0;
BA_ "GenSigSwitchedByIgnition" SG_ 779 KBI_Fehler_Anzeige_ACC 0;
BA_ "GenSigSendType" SG_ 779 KBI_GRA_Hauptschalter 0;
BA_ "GenSigSwitchedByIgnition" SG_ 779 KBI_GRA_Hauptschalter 0;
BA_ "Fehlerwert" SG_ 779 KBI_GRA_Hauptschalter 3;
BA_ "GenSigSendType" SG_ 779 KBI_Handbremse 0;
BA_ "GenSigSwitchedByIgnition" SG_ 779 KBI_Handbremse 0;
BA_ "GenSigSendType" SG_ 779 KBI_im_Stellgliedtest 0;
BA_ "GenSigSwitchedByIgnition" SG_ 779 KBI_im_Stellgliedtest 0;
BA_ "GenSigSendType" SG_ 779 KBI_Konsistenz_ACC 0;
BA_ "GenSigSwitchedByIgnition" SG_ 779 KBI_Konsistenz_ACC 0;
BA_ "GenSigSendType" SG_ 779 KBI_Lenkung_Lampe 0;
BA_ "GenSigSwitchedByIgnition" SG_ 779 KBI_Lenkung_Lampe 0;
BA_ "GenSigSendType" SG_ 779 KBI_MFA_v_Einheit_01 0;
BA_ "GenSigSwitchedByIgnition" SG_ 779 KBI_MFA_v_Einheit_01 0;
BA_ "GenSigSendType" SG_ 779 KBI_NV_in_Anzeige 0;
BA_ "GenSigSwitchedByIgnition" SG_ 779 KBI_NV_in_Anzeige 0;
BA_ "GenSigSendType" SG_ 779 KBI_PLA_in_Anzeige 0;
BA_ "GenSigSwitchedByIgnition" SG_ 779 KBI_PLA_in_Anzeige 0;
BA_ "GenSigSendType" SG_ 779 KBI_SILA_gueltig 0;
BA_ "GenSigSwitchedByIgnition" SG_ 779 KBI_SILA_gueltig 0;
BA_ "GenSigSendType" SG_ 779 KBI_Systemstatus 0;
BA_ "GenSigSwitchedByIgnition" SG_ 779 KBI_Systemstatus 0;
BA_ "GenSigSendType" SG_ 779 KBI_Tankwarnung 0;
BA_ "GenSigSwitchedByIgnition" SG_ 779 KBI_Tankwarnung 0;
BA_ "GenSigSendType" SG_ 779 KBI_Tankwarnung_ungueltig 0;
BA_ "GenSigStartValue" SG_ 779 KBI_Tankwarnung_ungueltig 1;
BA_ "GenSigSwitchedByIgnition" SG_ 779 KBI_Tankwarnung_ungueltig 0;
BA_ "GenSigSendType" SG_ 779 KBI_Taster_Fahrwerk 0;
BA_ "GenSigSwitchedByIgnition" SG_ 779 KBI_Taster_Fahrwerk 0;
BA_ "GenSigSendType" SG_ 779 KBI_Taster_Lift 0;
BA_ "GenSigSwitchedByIgnition" SG_ 779 KBI_Taster_Lift 0;
BA_ "GenSigSendType" SG_ 779 KBI_V_Digital 0;
BA_ "GenSigSwitchedByIgnition" SG_ 779 KBI_V_Digital 0;
BA_ "GenSigSendType" SG_ 779 KBI_Vorglueh_System_Lampe 0;
BA_ "GenSigSwitchedByIgnition" SG_ 779 KBI_Vorglueh_System_Lampe 0;
BA_ "GenSigSendType" SG_ 779 Kombi_01_BZ 0;
BA_ "GenSigFuncType" SG_ 779 Kombi_01_BZ 1;
BA_ "GenSigSwitchedByIgnition" SG_ 779 Kombi_01_BZ 0;
BA_REL_ "GenSigTimeoutTime" BU_SG_REL_ BedienDisp_vo SG_ 960 ZAS_Kl_S 1000;
BA_REL_ "GenSigTimeoutTime" BU_SG_REL_ BedienDisp_vo SG_ 960 ZAS_Kl_15 1000;
BA_REL_ "GenSigTimeoutTime" BU_SG_REL_ BedienDisp_vo SG_ 960 ZAS_Kl_50_Startanforderung 1000;
BA_REL_ "GenSigTimeoutTime" BU_SG_REL_ BedienDisp_vo SG_ 960 ZAS_Kl_Infotainment 1000;
BA_REL_ "GenSigTimeoutTime" BU_SG_REL_ BedienSG_hi SG_ 497 Schluesselnr_Personalisierung 5000;
BA_REL_ "GenSigTimeoutTime" BU_SG_REL_ BedienSG_hi SG_ 960 ZAS_Kl_S 1000;
BA_REL_ "GenSigTimeoutTime" BU_SG_REL_ BedienSG_hi SG_ 960 ZAS_Kl_15 1000;
BA_REL_ "GenSigTimeoutTime" BU_SG_REL_ BedienSG_hi SG_ 960 ZAS_Kl_50_Startanforderung 1000;
BA_REL_ "GenSigTimeoutTime" BU_SG_REL_ BedienSG_hi SG_ 960 BCM_Remotestart_Betrieb 1000;
BA_REL_ "GenSigTimeoutTime" BU_SG_REL_ BedienSG_hi SG_ 960 ZAS_Kl_Infotainment 1000;
BA_REL_ "GenSigTimeoutTime" BU_SG_REL_ BedienSG_hi SG_ 1646 KL_Innen_Temp 5000;
BA_REL_ "GenSigTimeoutTime" BU_SG_REL_ BedienSG_hi SG_ 779 KBI_MFA_v_Einheit_01 500;
BA_REL_ "GenSigTimeoutTime" BU_SG_REL_ BedienSG_hi SG_ 779 KBI_V_Digital 500;
BA_REL_ "GenSigTimeoutTime" BU_SG_REL_ BedienSG_hi SG_ 779 KBI_angez_Geschw 500;
BA_REL_ "GenSigTimeoutTime" BU_SG_REL_ BedienSG_hi SG_ 779 KBI_Einheit_Tacho 500;
BA_REL_ "GenSigTimeoutTime" BU_SG_REL_ DDA SG_ 960 ZAS_Kl_15 1000;
BA_REL_ "GenSigTimeoutTime" BU_SG_REL_ Gateway SG_ 2549088398 BedienDisp_vo_Nachlauftyp 5000;
BA_REL_ "GenSigTimeoutTime" BU_SG_REL_ Gateway SG_ 2549088398 BedienDisp_vo_SNI 5000;
BA_REL_ "GenSigTimeoutTime" BU_SG_REL_ Gateway SG_ 2549088398 KN_BedienDisp_v_ECUKnockOutTimer 5000;
BA_REL_ "GenSigTimeoutTime" BU_SG_REL_ Gateway SG_ 2549088398 KN_BedienDisp_v_BusKnockOut 5000;
BA_REL_ "GenSigTimeoutTime" BU_SG_REL_ Gateway SG_ 2549088398 KN_BedienDisp_v_BusKnockOutTimer 5000;
BA_REL_ "GenSigTimeoutTime" BU_SG_REL_ Gateway SG_ 2549088398 KN_BedienDisp_v_ECUKnockOut 5000;
BA_REL_ "GenSigTimeoutTime" BU_SG_REL_ Gateway SG_ 2549088398 NMH_BedienDisp_vo_Lokalaktiv 5000;
BA_REL_ "GenSigTimeoutTime" BU_SG_REL_ Gateway SG_ 2549088398 BedienDisp_vo_KD_Fehler 2500;
BA_REL_ "GenSigTimeoutTime" BU_SG_REL_ Gateway SG_ 2549088403 BedienSG_hi_Nachlauftyp 5000;
BA_REL_ "GenSigTimeoutTime" BU_SG_REL_ Gateway SG_ 2549088403 BedienSG_hi_SNI 5000;
BA_REL_ "GenSigTimeoutTime" BU_SG_REL_ Gateway SG_ 2549088403 KN_BedienSG_hi_ECUKnockOutTimer 5000;
BA_REL_ "GenSigTimeoutTime" BU_SG_REL_ Gateway SG_ 2549088403 KN_BedienSG_hi_BusKnockOut 5000;
BA_REL_ "GenSigTimeoutTime" BU_SG_REL_ Gateway SG_ 2549088403 KN_BedienSG_hi_BusKnockOutTimer 5000;
BA_REL_ "GenSigTimeoutTime" BU_SG_REL_ Gateway SG_ 2549088403 KN_BedienSG_hi_ECUKnockOut 5000;
BA_REL_ "GenSigTimeoutTime" BU_SG_REL_ Gateway SG_ 2549088403 NMH_BedienSG_hi_Lokalaktiv 5000;
BA_REL_ "GenSigTimeoutTime" BU_SG_REL_ Gateway SG_ 2549088403 NMH_BedienSG_hi_Subsystemaktiv 5000;
BA_REL_ "GenSigTimeoutTime" BU_SG_REL_ Gateway SG_ 2549088403 BedienSG_hi_KD_Fehler 2500;
BA_REL_ "GenSigTimeoutTime" BU_SG_REL_ Gateway SG_ 2549088442 DDA_Nachlauftyp 5000;
BA_REL_ "GenSigTimeoutTime" BU_SG_REL_ Gateway SG_ 2549088442 DDA_SNI 5000;
BA_REL_ "GenSigTimeoutTime" BU_SG_REL_ Gateway SG_ 2549088442 KN_DDA_BusKnockOutTimer 5000;
BA_REL_ "GenSigTimeoutTime" BU_SG_REL_ Gateway SG_ 2549088442 NM_DDA_Lokalaktiv 5000;
BA_REL_ "GenSigTimeoutTime" BU_SG_REL_ Gateway SG_ 2549088442 DDA_KD_Fehler 2500;
BA_REL_ "GenSigTimeoutTime" BU_SG_REL_ Gateway SG_ 2549088355 GM_Nachlauftyp 5000;
BA_REL_ "GenSigTimeoutTime" BU_SG_REL_ Gateway SG_ 2549088355 GM_SNI 5000;
BA_REL_ "GenSigTimeoutTime" BU_SG_REL_ Gateway SG_ 2549088355 GM_Lokalaktiv 5000;
BA_REL_ "GenSigTimeoutTime" BU_SG_REL_ Gateway SG_ 2549088355 GM_KD_Fehler 2500;
BA_REL_ "GenSigTimeoutTime" BU_SG_REL_ Gateway SG_ 2549088371 Info_El_Nachlauftyp 5000;
BA_REL_ "GenSigTimeoutTime" BU_SG_REL_ Gateway SG_ 2549088371 Info_El_SNI 5000;
BA_REL_ "GenSigTimeoutTime" BU_SG_REL_ Gateway SG_ 2549088371 KN_Info_El_BusKnockOutTimer 5000;
BA_REL_ "GenSigTimeoutTime" BU_SG_REL_ Gateway SG_ 2549088371 NM_Info_El_Lokalaktiv 5000;
BA_REL_ "GenSigTimeoutTime" BU_SG_REL_ Gateway SG_ 2549088371 NM_Info_El_Subsystemaktiv 5000;
BA_REL_ "GenSigTimeoutTime" BU_SG_REL_ Gateway SG_ 2549088371 Info_El_KD_Fehler 2500;
BA_REL_ "GenSigTimeoutTime" BU_SG_REL_ Gateway_PAG SG_ 2549088398 BedienDisp_vo_Nachlauftyp 5000;
BA_REL_ "GenSigTimeoutTime" BU_SG_REL_ Gateway_PAG SG_ 2549088398 BedienDisp_vo_SNI 5000;
BA_REL_ "GenSigTimeoutTime" BU_SG_REL_ Gateway_PAG SG_ 2549088398 KN_BedienDisp_v_ECUKnockOutTimer 5000;
BA_REL_ "GenSigTimeoutTime" BU_SG_REL_ Gateway_PAG SG_ 2549088398 KN_BedienDisp_v_BusKnockOut 5000;
BA_REL_ "GenSigTimeoutTime" BU_SG_REL_ Gateway_PAG SG_ 2549088398 KN_BedienDisp_v_BusKnockOutTimer 5000;
BA_REL_ "GenSigTimeoutTime" BU_SG_REL_ Gateway_PAG SG_ 2549088398 KN_BedienDisp_v_ECUKnockOut 5000;
BA_REL_ "GenSigTimeoutTime" BU_SG_REL_ Gateway_PAG SG_ 2549088398 NMH_BedienDisp_vo_Lokalaktiv 5000;
BA_REL_ "GenSigTimeoutTime" BU_SG_REL_ Gateway_PAG SG_ 2549088398 BedienDisp_vo_KD_Fehler 2500;
BA_REL_ "GenSigTimeoutTime" BU_SG_REL_ Gateway_PAG SG_ 2549088403 BedienSG_hi_Nachlauftyp 5000;
BA_REL_ "GenSigTimeoutTime" BU_SG_REL_ Gateway_PAG SG_ 2549088403 BedienSG_hi_SNI 5000;
BA_REL_ "GenSigTimeoutTime" BU_SG_REL_ Gateway_PAG SG_ 2549088403 KN_BedienSG_hi_ECUKnockOutTimer 5000;
BA_REL_ "GenSigTimeoutTime" BU_SG_REL_ Gateway_PAG SG_ 2549088403 KN_BedienSG_hi_BusKnockOut 5000;
BA_REL_ "GenSigTimeoutTime" BU_SG_REL_ Gateway_PAG SG_ 2549088403 KN_BedienSG_hi_BusKnockOutTimer 5000;
BA_REL_ "GenSigTimeoutTime" BU_SG_REL_ Gateway_PAG SG_ 2549088403 KN_BedienSG_hi_ECUKnockOut 5000;
BA_REL_ "GenSigTimeoutTime" BU_SG_REL_ Gateway_PAG SG_ 2549088403 NMH_BedienSG_hi_Lokalaktiv 5000;
BA_REL_ "GenSigTimeoutTime" BU_SG_REL_ Gateway_PAG SG_ 2549088403 NMH_BedienSG_hi_Subsystemaktiv 5000;
BA_REL_ "GenSigTimeoutTime" BU_SG_REL_ Gateway_PAG SG_ 2549088403 BedienSG_hi_KD_Fehler 2500;
BA_REL_ "GenSigTimeoutTime" BU_SG_REL_ Gateway_PAG SG_ 2549088442 DDA_Nachlauftyp 5000;
BA_REL_ "GenSigTimeoutTime" BU_SG_REL_ Gateway_PAG SG_ 2549088442 DDA_SNI 5000;
BA_REL_ "GenSigTimeoutTime" BU_SG_REL_ Gateway_PAG SG_ 2549088442 KN_DDA_BusKnockOutTimer 5000;
BA_REL_ "GenSigTimeoutTime" BU_SG_REL_ Gateway_PAG SG_ 2549088442 NM_DDA_Lokalaktiv 5000;
BA_REL_ "GenSigTimeoutTime" BU_SG_REL_ Gateway_PAG SG_ 2549088442 DDA_KD_Fehler 2500;
BA_REL_ "GenSigTimeoutTime" BU_SG_REL_ Gateway_PAG SG_ 2549088371 Info_El_Nachlauftyp 5000;
BA_REL_ "GenSigTimeoutTime" BU_SG_REL_ Gateway_PAG SG_ 2549088371 Info_El_SNI 5000;
BA_REL_ "GenSigTimeoutTime" BU_SG_REL_ Gateway_PAG SG_ 2549088371 NM_Info_El_Lokalaktiv 5000;
BA_REL_ "GenSigTimeoutTime" BU_SG_REL_ Gateway_PAG SG_ 2549088371 NM_Info_El_Subsystemaktiv 5000;
BA_REL_ "GenSigTimeoutTime" BU_SG_REL_ Gateway_PAG SG_ 2549088371 Info_El_KD_Fehler 2500;
BA_REL_ "GenSigTimeoutTime" BU_SG_REL_ Gateway_PAG SG_ 2549088258 Sekundaer_02_Nachlauftyp 5000;
BA_REL_ "GenSigTimeoutTime" BU_SG_REL_ Gateway_PAG SG_ 2549088258 Sekundaer_02_SNI 5000;
BA_REL_ "GenSigTimeoutTime" BU_SG_REL_ Gateway_PAG SG_ 2549088258 Sekundaer_02_KD_Fehler 2500;
BA_REL_ "GenSigTimeoutTime" BU_SG_REL_ GurtMikrofon SG_ 960 ZAS_Kl_S 1000;
BA_REL_ "GenSigTimeoutTime" BU_SG_REL_ GurtMikrofon SG_ 960 ZAS_Kl_15 1000;
BA_REL_ "GenSigTimeoutTime" BU_SG_REL_ OTA_FC SG_ 960 ZAS_Kl_S 1000;
BA_REL_ "GenSigTimeoutTime" BU_SG_REL_ OTA_FC SG_ 960 ZAS_Kl_15 1000;
BA_REL_ "GenSigTimeoutTime" BU_SG_REL_ OTA_FC SG_ 960 ZAS_Kl_50_Startanforderung 1000;
BA_REL_ "GenSigTimeoutTime" BU_SG_REL_ OTA_FC SG_ 1646 KL_Umluft_Taste 5000;
BA_REL_ "GenSigTimeoutTime" BU_SG_REL_ OTA_FC SG_ 1646 KL_Geblaese_Status 5000;
BA_REL_ "GenSigTimeoutTime" BU_SG_REL_ OTA_FC SG_ 1646 KL_ErwVK_Anf 5000;
BA_REL_ "GenSigTimeoutTime" BU_SG_REL_ OTA_FC SG_ 1646 KL_Innen_Temp 5000;
BA_REL_ "GenSigTimeoutTime" BU_SG_REL_ OTA_FC SG_ 949 KL_AC_Schalter 5000;
BA_REL_ "GenSigTimeoutTime" BU_SG_REL_ OTA_FC SG_ 949 KL_Zustand 5000;
BA_REL_ "GenSigTimeoutTime" BU_SG_REL_ OTA_FC SG_ 949 KL_Charisma_FahrPr 5000;
BA_REL_ "GenSigTimeoutTime" BU_SG_REL_ OTA_FC SG_ 1640 KL_LRH_Taster 2000;
BA_REL_ "GenSigTimeoutTime" BU_SG_REL_ OTA_FC SG_ 1640 HSH_Taster 2000;
BA_REL_ "GenSigTimeoutTime" BU_SG_REL_ OTA_FC SG_ 1640 FSH_Taster 2000;
BA_REL_ "GenSigTimeoutTime" BU_SG_REL_ OTA_FC SG_ 1640 KL_Beschlagsgefahr 2000;
BA_REL_ "GenSigTimeoutTime" BU_SG_REL_ OTA_FC SG_ 1640 KL_SIH_Soll_li 2000;
BA_REL_ "GenSigTimeoutTime" BU_SG_REL_ OTA_FC SG_ 1640 KL_SIH_Soll_re 2000;
BA_REL_ "GenSigTimeoutTime" BU_SG_REL_ OTA_FC SG_ 1640 KL_SIL_Soll_li 2000;
BA_REL_ "GenSigTimeoutTime" BU_SG_REL_ OTA_FC SG_ 1640 KL_SIL_Soll_re 2000;
BA_REL_ "GenSigTimeoutTime" BU_SG_REL_ OTA_FC SG_ 1640 KL_Umluftklappe_Status 2000;
BA_REL_ "GenSigTimeoutTime" BU_SG_REL_ OTA_FC SG_ 2589283621 KL_Umluft_Connect_status 5000;
BA_REL_ "GenSigTimeoutTime" BU_SG_REL_ OTA_FC SG_ 2589283621 KL_ECO_PRO_Aktiv 5000;
BA_REL_ "GenSigTimeoutTime" BU_SG_REL_ OTA_FC SG_ 2589283621 KL_QBit_Sonnenintensitaet 5000;
BA_REL_ "GenSigTimeoutTime" BU_SG_REL_ OTA_FC SG_ 2589283621 KL_ZR_Anforderung 5000;
BA_REL_ "GenSigTimeoutTime" BU_SG_REL_ OTA_FC SG_ 2589283621 KL_ACmax_Aktiv 5000;
BA_REL_ "GenSigTimeoutTime" BU_SG_REL_ OTA_FC SG_ 2589283621 KL_Defrost_Aktiv 5000;
BA_REL_ "GenSigTimeoutTime" BU_SG_REL_ OTA_FC SG_ 2589283621 KL_ECO_Aktiv 5000;
BA_REL_ "GenSigTimeoutTime" BU_SG_REL_ OTA_FC SG_ 2589283621 KL_Status_Klimastil 5000;
BA_REL_ "GenSigTimeoutTime" BU_SG_REL_ OTA_FC SG_ 2589283621 KL_Kundeneingriff_Geblaese 5000;
BA_REL_ "GenSigTimeoutTime" BU_SG_REL_ OTA_FC SG_ 2589283621 KL_Thermischer_Bedarf 5000;
BA_REL_ "GenSigTimeoutTime" BU_SG_REL_ OTA_FC SG_ 2589283621 KL_Eps_Innen 5000;
BA_REL_ "GenSigTimeoutTime" BU_SG_REL_ OTA_FC SG_ 2589283621 KL_Sonnenintensitaet 5000;
BA_REL_ "GenSigTimeoutTime" BU_SG_REL_ OTA_FC SG_ 1712 FS_Taupunkt 5000;
BA_REL_ "GenSigTimeoutTime" BU_SG_REL_ OTA_FC SG_ 1712 FS_Temp_Scheibe 5000;
BA_REL_ "GenSigTimeoutTime" BU_SG_REL_ OTA_FC SG_ 1712 FS_Temp_Sensor 5000;
BA_REL_ "GenSigTimeoutTime" BU_SG_REL_ OTA_FC SG_ 1712 FS_Luftfeuchte_rel 5000;
BA_REL_ "GenSigTimeoutTime" BU_SG_REL_ OTA_FC SG_ 779 KBI_angez_Geschw 500;
BA_REL_ "GenSigTimeoutTime" BU_SG_REL_ ZR_High SG_ 497 KY_FT_Entriegelung_Autorisiert 5000;
BA_REL_ "GenSigTimeoutTime" BU_SG_REL_ ZR_High SG_ 497 KY_FT_Verriegelung_Autorisiert 5000;
BA_REL_ "GenSigTimeoutTime" BU_SG_REL_ ZR_High SG_ 497 KY_BT_Entriegelung_Autorisiert 5000;
BA_REL_ "GenSigTimeoutTime" BU_SG_REL_ ZR_High SG_ 497 KY_BT_Verriegelung_Autorisiert 5000;
BA_REL_ "GenSigTimeoutTime" BU_SG_REL_ ZR_High SG_ 497 KY_HFS_Entriegelung_Autorisiert 5000;
BA_REL_ "GenSigTimeoutTime" BU_SG_REL_ ZR_High SG_ 497 KY_HFS_Verriegelung_Autorisiert 5000;
BA_REL_ "GenSigTimeoutTime" BU_SG_REL_ ZR_High SG_ 497 KY_HBFS_Entriegelung_Autorisiert 5000;
BA_REL_ "GenSigTimeoutTime" BU_SG_REL_ ZR_High SG_ 497 KY_HBFS_Verriegelung_Autorisiert 5000;
BA_REL_ "GenSigTimeoutTime" BU_SG_REL_ ZR_High SG_ 497 KY_Front_Entr_Autorisiert 5000;
BA_REL_ "GenSigTimeoutTime" BU_SG_REL_ ZR_High SG_ 497 KY_Front_Verr_Autorisiert 5000;
BA_REL_ "GenSigTimeoutTime" BU_SG_REL_ ZR_High SG_ 497 KY_HD_Entriegelung_Autorisiert 5000;
BA_REL_ "GenSigTimeoutTime" BU_SG_REL_ ZR_High SG_ 497 KY_HD_Verriegelung_Autorisiert 5000;
BA_REL_ "GenSigTimeoutTime" BU_SG_REL_ ZR_High SG_ 497 Schluesselnr_Personalisierung 5000;
BA_REL_ "GenSigTimeoutTime" BU_SG_REL_ ZR_High SG_ 497 FFB_Joker_Taste 5000;
BA_REL_ "GenSigTimeoutTime" BU_SG_REL_ ZR_High SG_ 497 FBS_Aktivierung_Pilot_Parken 5000;
BA_REL_ "GenSigTimeoutTime" BU_SG_REL_ ZR_High SG_ 497 KY_EasyClose_Status 5000;
BA_REL_ "GenSigTimeoutTime" BU_SG_REL_ ZR_High SG_ 497 KY_HD_Auffahrt 5000;
BA_REL_ "GenSigTimeoutTime" BU_SG_REL_ ZR_High SG_ 497 KY_HD_Zufahrt 5000;
BA_REL_ "GenSigTimeoutTime" BU_SG_REL_ ZR_High SG_ 1424 KY_Keyless_Verbau 2000;
BA_REL_ "GenSigTimeoutTime" BU_SG_REL_ ZR_High SG_ 1424 KY_Keyless_Go_Verbau 2000;
BA_REL_ "GenSigTimeoutTime" BU_SG_REL_ ZR_High SG_ 1424 KY_Indikator_Mehrere_Schluessel 2000;
BA_REL_ "GenSigTimeoutTime" BU_SG_REL_ ZR_High SG_ 960 ZAS_Kl_S 1000;
BA_REL_ "GenSigTimeoutTime" BU_SG_REL_ ZR_High SG_ 960 ZAS_Kl_15 1000;
BA_REL_ "GenSigTimeoutTime" BU_SG_REL_ ZR_High SG_ 960 ZAS_Kl_50_Startanforderung 1000;
BA_REL_ "GenSigTimeoutTime" BU_SG_REL_ ZR_High SG_ 960 BCM_Remotestart_Betrieb 1000;
BA_REL_ "GenSigTimeoutTime" BU_SG_REL_ ZR_High SG_ 960 KST_Warn_P1_ZST_def 1000;
BA_REL_ "GenSigTimeoutTime" BU_SG_REL_ ZR_High SG_ 960 KST_Warn_P2_ZST_def 1000;
BA_REL_ "GenSigTimeoutTime" BU_SG_REL_ ZR_High SG_ 960 KST_Fahrerhinweis_1 1000;
BA_REL_ "GenSigTimeoutTime" BU_SG_REL_ ZR_High SG_ 960 KST_Fahrerhinweis_2 1000;
BA_REL_ "GenSigTimeoutTime" BU_SG_REL_ ZR_High SG_ 960 BCM_Ausparken_Betrieb 1000;
BA_REL_ "GenSigTimeoutTime" BU_SG_REL_ ZR_High SG_ 1420 KST_ZAT_betaetigt 5000;
BA_REL_ "GenSigTimeoutTime" BU_SG_REL_ ZR_High SG_ 1646 KL_STL_aktiv 5000;
BA_REL_ "GenSigTimeoutTime" BU_SG_REL_ ZR_High SG_ 1646 KL_STH_aktiv 5000;
BA_REL_ "GenSigTimeoutTime" BU_SG_REL_ ZR_High SG_ 1646 KL_Solarluefter_aktiv 5000;
BA_REL_ "GenSigTimeoutTime" BU_SG_REL_ ZR_High SG_ 1646 KL_Umluft_Taste 5000;
BA_REL_ "GenSigTimeoutTime" BU_SG_REL_ ZR_High SG_ 1646 KL_Geblaese_Fond_Status 5000;
BA_REL_ "GenSigTimeoutTime" BU_SG_REL_ ZR_High SG_ 1646 KL_STH_Ansteuerung 5000;
BA_REL_ "GenSigTimeoutTime" BU_SG_REL_ ZR_High SG_ 1646 KL_STH_Betriebsdauer 5000;
BA_REL_ "GenSigTimeoutTime" BU_SG_REL_ ZR_High SG_ 1646 KL_Geblaese_Status 5000;
BA_REL_ "GenSigTimeoutTime" BU_SG_REL_ ZR_High SG_ 1646 KL_Innen_Temp 5000;
BA_REL_ "GenSigTimeoutTime" BU_SG_REL_ ZR_High SG_ 1646 KL_Anf_AussenspiegelHzg 5000;
BA_REL_ "GenSigTimeoutTime" BU_SG_REL_ ZR_High SG_ 1646 KL_SIH_LEH_Verteilung_VL 5000;
BA_REL_ "GenSigTimeoutTime" BU_SG_REL_ ZR_High SG_ 1646 KL_SIH_LEL_Verteilung_VL 5000;
BA_REL_ "GenSigTimeoutTime" BU_SG_REL_ ZR_High SG_ 1646 KL_SIH_LEH_Verteilung_VR 5000;
BA_REL_ "GenSigTimeoutTime" BU_SG_REL_ ZR_High SG_ 1646 KL_SIH_LEL_Verteilung_VR 5000;
BA_REL_ "GenSigTimeoutTime" BU_SG_REL_ ZR_High SG_ 1663 KL_Mod_Display_li 5000;
BA_REL_ "GenSigTimeoutTime" BU_SG_REL_ ZR_High SG_ 1663 KL_Mod_Display_re 5000;
BA_REL_ "GenSigTimeoutTime" BU_SG_REL_ ZR_High SG_ 1663 KL_Einheiten 5000;
BA_REL_ "GenSigTimeoutTime" BU_SG_REL_ ZR_High SG_ 1663 KL_ICO2_Sensor_defekt 5000;
BA_REL_ "GenSigTimeoutTime" BU_SG_REL_ ZR_High SG_ 1663 KL_Umluft 5000;
BA_REL_ "GenSigTimeoutTime" BU_SG_REL_ ZR_High SG_ 1608 KL_AUTO_HL_Soll 5000;
BA_REL_ "GenSigTimeoutTime" BU_SG_REL_ ZR_High SG_ 1608 KL_AUTO_HR_Soll 5000;
BA_REL_ "GenSigTimeoutTime" BU_SG_REL_ ZR_High SG_ 1608 KL_Fondbedienung_aktiv 5000;
BA_REL_ "GenSigTimeoutTime" BU_SG_REL_ ZR_High SG_ 1608 KL_Status_Soll 5000;
BA_REL_ "GenSigTimeoutTime" BU_SG_REL_ ZR_High SG_ 1608 KL_Befehlszaehler_FH 5000;
BA_REL_ "GenSigTimeoutTime" BU_SG_REL_ ZR_High SG_ 1608 KL_Luftmenge_HR_Soll 5000;
BA_REL_ "GenSigTimeoutTime" BU_SG_REL_ ZR_High SG_ 1608 KL_Luftmenge_HL_Soll 5000;
BA_REL_ "GenSigTimeoutTime" BU_SG_REL_ ZR_High SG_ 1608 KL_Luftverteilung_HR_Soll 5000;
BA_REL_ "GenSigTimeoutTime" BU_SG_REL_ ZR_High SG_ 1608 KL_Luftverteilung_HL_Soll 5000;
BA_REL_ "GenSigTimeoutTime" BU_SG_REL_ ZR_High SG_ 1608 KL_SL_HL_Soll 5000;
BA_REL_ "GenSigTimeoutTime" BU_SG_REL_ ZR_High SG_ 1608 KL_SL_HR_Soll 5000;
BA_REL_ "GenSigTimeoutTime" BU_SG_REL_ ZR_High SG_ 1608 KL_SH_HR_Soll 5000;
BA_REL_ "GenSigTimeoutTime" BU_SG_REL_ ZR_High SG_ 1608 KL_SH_HL_Soll 5000;
BA_REL_ "GenSigTimeoutTime" BU_SG_REL_ ZR_High SG_ 1608 KL_Temp_HL_Soll 5000;
BA_REL_ "GenSigTimeoutTime" BU_SG_REL_ ZR_High SG_ 1608 KL_Temp_HR_Soll 5000;
BA_REL_ "GenSigTimeoutTime" BU_SG_REL_ ZR_High SG_ 1608 KL_Luftmenge_HR_max 5000;
BA_REL_ "GenSigTimeoutTime" BU_SG_REL_ ZR_High SG_ 1608 KL_Luftmenge_HL_max 5000;
BA_REL_ "GenSigTimeoutTime" BU_SG_REL_ ZR_High SG_ 1608 KL_Luftmenge_HR_offset 5000;
BA_REL_ "GenSigTimeoutTime" BU_SG_REL_ ZR_High SG_ 1608 KL_Luftmenge_HL_offset 5000;
BA_REL_ "GenSigTimeoutTime" BU_SG_REL_ ZR_High SG_ 949 KL_AC_Schalter 5000;
BA_REL_ "GenSigTimeoutTime" BU_SG_REL_ ZR_High SG_ 1640 KL_LRH_Taster 2000;
BA_REL_ "GenSigTimeoutTime" BU_SG_REL_ ZR_High SG_ 1640 KL_LRH_Stufe 2000;
BA_REL_ "GenSigTimeoutTime" BU_SG_REL_ ZR_High SG_ 1640 HSH_Taster 2000;
BA_REL_ "GenSigTimeoutTime" BU_SG_REL_ ZR_High SG_ 1640 FSH_Taster 2000;
BA_REL_ "GenSigTimeoutTime" BU_SG_REL_ ZR_High SG_ 1640 KL_Zuheizer_Freigabe 2000;
BA_REL_ "GenSigTimeoutTime" BU_SG_REL_ ZR_High SG_ 1640 KL_Beschlagsgefahr 2000;
BA_REL_ "GenSigTimeoutTime" BU_SG_REL_ ZR_High SG_ 1640 KL_SIH_Soll_li 2000;
BA_REL_ "GenSigTimeoutTime" BU_SG_REL_ ZR_High SG_ 1640 KL_SIH_Soll_re 2000;
BA_REL_ "GenSigTimeoutTime" BU_SG_REL_ ZR_High SG_ 1640 KRH_Soll_li 2000;
BA_REL_ "GenSigTimeoutTime" BU_SG_REL_ ZR_High SG_ 1640 KL_SIL_Soll_li 2000;
BA_REL_ "GenSigTimeoutTime" BU_SG_REL_ ZR_High SG_ 1640 KL_SIL_Soll_re 2000;
BA_REL_ "GenSigTimeoutTime" BU_SG_REL_ ZR_High SG_ 1640 KRH_Soll_re 2000;
BA_REL_ "GenSigTimeoutTime" BU_SG_REL_ ZR_High SG_ 1640 KL_Umluftklappe_Status 2000;
BA_REL_ "GenSigTimeoutTime" BU_SG_REL_ ZR_High SG_ 1441 KL_Temp_Soll_hl 5000;
BA_REL_ "GenSigTimeoutTime" BU_SG_REL_ ZR_High SG_ 1441 KL_Temp_Soll_hr 5000;
BA_REL_ "GenSigTimeoutTime" BU_SG_REL_ ZR_High SG_ 1441 KL_Temp_Soll_vl 5000;
BA_REL_ "GenSigTimeoutTime" BU_SG_REL_ ZR_High SG_ 1441 KL_Temp_Soll_vr 5000;
BA_REL_ "GenSigTimeoutTime" BU_SG_REL_ ZR_High SG_ 1441 KL_SIH_Stufe_hl 5000;
BA_REL_ "GenSigTimeoutTime" BU_SG_REL_ ZR_High SG_ 1441 KL_SIH_Stufe_hr 5000;
BA_REL_ "GenSigTimeoutTime" BU_SG_REL_ ZR_High SG_ 1441 KL_SIL_Stufe_hl 5000;
BA_REL_ "GenSigTimeoutTime" BU_SG_REL_ ZR_High SG_ 1441 KL_SIL_Stufe_hr 5000;
BA_REL_ "GenSigTimeoutTime" BU_SG_REL_ ZR_High SG_ 1441 KL_SIL_LEL_Verteilung_HR 5000;
BA_REL_ "GenSigTimeoutTime" BU_SG_REL_ ZR_High SG_ 1441 KL_SIL_LEL_Verteilung_HL 5000;
BA_REL_ "GenSigTimeoutTime" BU_SG_REL_ ZR_High SG_ 1441 KL_SIH_LEH_Verteilung_HR 5000;
BA_REL_ "GenSigTimeoutTime" BU_SG_REL_ ZR_High SG_ 1441 KL_SIH_LEH_Verteilung_HL 5000;
BA_REL_ "GenSigTimeoutTime" BU_SG_REL_ ZR_High SG_ 1441 KL_Frischluftklappe_Status 5000;
BA_REL_ "GenSigTimeoutTime" BU_SG_REL_ ZR_High SG_ 2589283621 KL_FlHz_Soll_VL 5000;
BA_REL_ "GenSigTimeoutTime" BU_SG_REL_ ZR_High SG_ 2589283621 KL_FlHz_Soll_HL 5000;
BA_REL_ "GenSigTimeoutTime" BU_SG_REL_ ZR_High SG_ 2589283621 KL_FlHz_Soll_VR 5000;
BA_REL_ "GenSigTimeoutTime" BU_SG_REL_ ZR_High SG_ 2589283621 KL_FlHz_Soll_HR 5000;
BA_REL_ "GenSigTimeoutTime" BU_SG_REL_ ZR_High SG_ 2589283621 KL_Umluft_Connect_status 5000;
BA_REL_ "GenSigTimeoutTime" BU_SG_REL_ ZR_High SG_ 2589283621 KL_ECO_PRO_Aktiv 5000;
BA_REL_ "GenSigTimeoutTime" BU_SG_REL_ ZR_High SG_ 2589283621 KL_ZR_Anforderung 5000;
BA_REL_ "GenSigTimeoutTime" BU_SG_REL_ ZR_High SG_ 2589283621 KL_ACmax_Aktiv 5000;
BA_REL_ "GenSigTimeoutTime" BU_SG_REL_ ZR_High SG_ 2589283621 KL_Defrost_Aktiv 5000;
BA_REL_ "GenSigTimeoutTime" BU_SG_REL_ ZR_High SG_ 2589283621 KL_ECO_Aktiv 5000;
BA_REL_ "GenSigTimeoutTime" BU_SG_REL_ ZR_High SG_ 2589283621 KL_Status_Klimastil 5000;
BA_REL_ "GenSigTimeoutTime" BU_SG_REL_ ZR_High SG_ 2589283621 KL_Kundeneingriff_Geblaese 5000;
BA_REL_ "GenSigTimeoutTime" BU_SG_REL_ ZR_High SG_ 2589283621 KL_Eps_Innen 5000;
BA_REL_ "GenSigTimeoutTime" BU_SG_REL_ ZR_High SG_ 2589283621 KL_Sonnenintensitaet 5000;
BA_REL_ "GenSigTimeoutTime" BU_SG_REL_ ZR_High SG_ 992 KL_Fond_Fuss_Temp_hl 1000;
BA_REL_ "GenSigTimeoutTime" BU_SG_REL_ ZR_High SG_ 992 KL_SL_Soll_hl 1000;
BA_REL_ "GenSigTimeoutTime" BU_SG_REL_ ZR_High SG_ 992 KL_SL_Soll_hr 1000;
BA_REL_ "GenSigTimeoutTime" BU_SG_REL_ ZR_High SG_ 992 KL_Fond_Fuss_Temp_hr 1000;
BA_REL_ "GenSigTimeoutTime" BU_SG_REL_ ZR_High SG_ 992 KL_SH_Soll_hl 1000;
BA_REL_ "GenSigTimeoutTime" BU_SG_REL_ ZR_High SG_ 992 KL_SH_Soll_hr 1000;
BA_REL_ "GenSigTimeoutTime" BU_SG_REL_ ZR_High SG_ 992 KL_MA_Temp_hl 1000;
BA_REL_ "GenSigTimeoutTime" BU_SG_REL_ ZR_High SG_ 992 KL_Fehler_Umluft 1000;
BA_REL_ "GenSigTimeoutTime" BU_SG_REL_ ZR_High SG_ 992 KL_MA_Temp_hr 1000;
BA_REL_ "GenSigTimeoutTime" BU_SG_REL_ ZR_High SG_ 992 KL_Fehler_Fussraum_Klappen 1000;
BA_REL_ "GenSigTimeoutTime" BU_SG_REL_ ZR_High SG_ 992 KL_Fehler_Temp_Klappen 1000;
BA_REL_ "GenSigTimeoutTime" BU_SG_REL_ ZR_High SG_ 992 KL_Fehler_Temp_MA_Klappen 1000;
BA_REL_ "GenSigTimeoutTime" BU_SG_REL_ ZR_High SG_ 1712 FS_Taupunkt 5000;
BA_REL_ "GenSigTimeoutTime" BU_SG_REL_ ZR_High SG_ 1712 FS_Temp_Scheibe 5000;
BA_REL_ "GenSigTimeoutTime" BU_SG_REL_ ZR_High SG_ 1712 FS_Temp_Sensor 5000;
BA_REL_ "GenSigTimeoutTime" BU_SG_REL_ ZR_High SG_ 605 KLR_Touchauswertung 5000;
BA_REL_ "GenSigTimeoutTime" BU_SG_REL_ ZR_High SG_ 779 KBI_ABS_Lampe 500;
BA_REL_ "GenSigTimeoutTime" BU_SG_REL_ ZR_High SG_ 779 KBI_ESP_Lampe 500;
BA_REL_ "GenSigTimeoutTime" BU_SG_REL_ ZR_High SG_ 779 KBI_BKL_Lampe 500;
BA_REL_ "GenSigTimeoutTime" BU_SG_REL_ ZR_High SG_ 779 KBI_Airbag_Lampe 500;
BA_REL_ "GenSigTimeoutTime" BU_SG_REL_ ZR_High SG_ 779 KBI_Vorglueh_System_Lampe 500;
BA_REL_ "GenSigTimeoutTime" BU_SG_REL_ ZR_High SG_ 779 KBI_NV_in_Anzeige 500;
BA_REL_ "GenSigTimeoutTime" BU_SG_REL_ ZR_High SG_ 779 KBI_Anzeigestatus_ACC 500;
BA_REL_ "GenSigTimeoutTime" BU_SG_REL_ ZR_High SG_ 779 KBI_Anzeigestatus_GRA 500;
BA_REL_ "GenSigTimeoutTime" BU_SG_REL_ ZR_High SG_ 779 KBI_Tankwarnung 500;
BA_REL_ "GenSigTimeoutTime" BU_SG_REL_ ZR_High SG_ 779 KBI_MFA_v_Einheit_01 500;
BA_REL_ "GenSigTimeoutTime" BU_SG_REL_ ZR_High SG_ 779 KBI_Tankwarnung_ungueltig 500;
BA_REL_ "GenSigTimeoutTime" BU_SG_REL_ ZR_High SG_ 779 KBI_V_Digital 500;
BA_REL_ "GenSigTimeoutTime" BU_SG_REL_ ZR_High SG_ 779 KBI_PLA_in_Anzeige 500;
BA_REL_ "GenSigTimeoutTime" BU_SG_REL_ ZR_High SG_ 779 KBI_ARA_in_Anzeige 500;
BA_REL_ "GenSigTimeoutTime" BU_SG_REL_ ZR_High SG_ 779 KBI_angez_Geschw 500;
BA_REL_ "GenSigTimeoutTime" BU_SG_REL_ ZR_High SG_ 779 KBI_Einheit_Tacho 500;
BA_REL_ "GenSigTimeoutTime" BU_SG_REL_ ZR_High SG_ 779 KBI_Fehler_Anzeige_ACC 500;
BA_REL_ "GenSigTimeoutTime" BU_SG_REL_ ZR_High SG_ 779 KBI_Anzeigefehler_SWA 500;
BA_REL_ "GenSigTimeoutTime" BU_SG_REL_ ZR_LIMU SG_ 1424 KY_LF_Aktiv 2000;
BA_REL_ "GenSigTimeoutTime" BU_SG_REL_ ZR_LIMU SG_ 960 Klemmen_Status_01_CRC 1000;
BA_REL_ "GenSigTimeoutTime" BU_SG_REL_ ZR_LIMU SG_ 960 Klemmen_Status_01_BZ 1000;
BA_REL_ "GenSigTimeoutTime" BU_SG_REL_ ZR_LIMU SG_ 960 RSt_Fahrerhinweise 1000;
BA_REL_ "GenSigTimeoutTime" BU_SG_REL_ ZR_LIMU SG_ 960 ZAS_Kl_S 1000;
BA_REL_ "GenSigTimeoutTime" BU_SG_REL_ ZR_LIMU SG_ 960 ZAS_Kl_15 1000;
BA_REL_ "GenSigTimeoutTime" BU_SG_REL_ ZR_LIMU SG_ 960 ZAS_Kl_X 1000;
BA_REL_ "GenSigTimeoutTime" BU_SG_REL_ ZR_LIMU SG_ 960 ZAS_Kl_50_Startanforderung 1000;
BA_REL_ "GenSigTimeoutTime" BU_SG_REL_ ZR_LIMU SG_ 960 BCM_Remotestart_Betrieb 1000;
BA_REL_ "GenSigTimeoutTime" BU_SG_REL_ ZR_LIMU SG_ 960 ZAS_Kl_Infotainment 1000;
BA_REL_ "GenSigTimeoutTime" BU_SG_REL_ ZR_LIMU SG_ 960 BCM_Remotestart_KL15_Anf 1000;
BA_REL_ "GenSigTimeoutTime" BU_SG_REL_ ZR_LIMU SG_ 960 BCM_Remotestart_MO_Start 1000;
BA_REL_ "GenSigTimeoutTime" BU_SG_REL_ ZR_LIMU SG_ 960 KST_Warn_P1_ZST_def 1000;
BA_REL_ "GenSigTimeoutTime" BU_SG_REL_ ZR_LIMU SG_ 960 KST_Warn_P2_ZST_def 1000;
BA_REL_ "GenSigTimeoutTime" BU_SG_REL_ ZR_LIMU SG_ 960 KST_Fahrerhinweis_1 1000;
BA_REL_ "GenSigTimeoutTime" BU_SG_REL_ ZR_LIMU SG_ 960 KST_Fahrerhinweis_2 1000;
BA_REL_ "GenSigTimeoutTime" BU_SG_REL_ ZR_LIMU SG_ 960 BCM_Ausparken_Betrieb 1000;
BA_REL_ "GenSigTimeoutTime" BU_SG_REL_ ZR_LIMU SG_ 960 KST_Fahrerhinweis_4 1000;
BA_REL_ "GenSigTimeoutTime" BU_SG_REL_ ZR_LIMU SG_ 960 KST_Fahrerhinweis_5 1000;
BA_REL_ "GenSigTimeoutTime" BU_SG_REL_ ZR_LIMU SG_ 960 KST_Fahrerhinweis_6 1000;
BA_REL_ "GenSigTimeoutTime" BU_SG_REL_ ZR_LIMU SG_ 1640 KL_I_Geblaese 2000;
BA_REL_ "GenSigTimeoutTime" BU_SG_REL_ ZR_LIMU SG_ 2589283621 KL_ZR_Anforderung 5000;
BA_REL_ "GenSigTimeoutTime" BU_SG_REL_ ZR_LIMU SG_ 1505 BCM1_Aussen_Temp_ungef 5000;
BA_REL_ "GenSigTimeoutTime" BU_SG_REL_ ZR_LIMU SG_ 779 KBI_Tankwarnung 500;
BA_REL_ "GenSigTimeoutTime" BU_SG_REL_ ZR_LIMU SG_ 779 KBI_MFA_v_Einheit_01 500;
BA_REL_ "GenSigTimeoutTime" BU_SG_REL_ ZR_LIMU SG_ 779 KBI_Tankwarnung_ungueltig 500;
BA_REL_ "GenSigTimeoutTime" BU_SG_REL_ ZR_LIMU SG_ 779 KBI_V_Digital 500;
BA_REL_ "GenSigTimeoutTime" BU_SG_REL_ ZR_LIMU SG_ 779 KBI_angez_Geschw 500;
BA_REL_ "GenSigTimeoutTime" BU_SG_REL_ ZR_MIB_TOP_ab_Gen3 SG_ 960 ZAS_Kl_S 1000;
BA_REL_ "GenSigTimeoutTime" BU_SG_REL_ ZR_MIB_TOP_ab_Gen3 SG_ 960 ZAS_Kl_15 1000;
BA_REL_ "GenSigTimeoutTime" BU_SG_REL_ ZR_MIB_TOP_ab_Gen3 SG_ 960 ZAS_Kl_50_Startanforderung 1000;
BA_REL_ "GenSigTimeoutTime" BU_SG_REL_ ZR_MIB_TOP_ab_Gen3 SG_ 960 BCM_Remotestart_Betrieb 1000;
BA_REL_ "GenSigTimeoutTime" BU_SG_REL_ ZR_MIB_TOP_ab_Gen3 SG_ 1640 KL_I_Geblaese 2000;
BA_REL_ "GenSigTimeoutTime" BU_SG_REL_ ZR_MIB_TOP_ab_Gen3 SG_ 2589283621 KL_ZR_Anforderung 5000;
BA_REL_ "GenSigTimeoutTime" BU_SG_REL_ ZR_MIB_TOP_ab_Gen3 SG_ 779 KBI_Tankwarnung 500;
BA_REL_ "GenSigTimeoutTime" BU_SG_REL_ ZR_MIB_TOP_ab_Gen3 SG_ 779 KBI_MFA_v_Einheit_01 500;
BA_REL_ "GenSigTimeoutTime" BU_SG_REL_ ZR_MIB_TOP_ab_Gen3 SG_ 779 KBI_Tankwarnung_ungueltig 500;
BA_REL_ "GenSigTimeoutTime" BU_SG_REL_ ZR_MIB_TOP_ab_Gen3 SG_ 779 KBI_V_Digital 500;
BA_REL_ "GenSigTimeoutTime" BU_SG_REL_ ZR_MIB_TOP_ab_Gen3 SG_ 779 KBI_angez_Geschw 500;
BA_REL_ "GenSigTimeoutTime" BU_SG_REL_ ZR_Standard SG_ 960 ZAS_Kl_S 1000;
BA_REL_ "GenSigTimeoutTime" BU_SG_REL_ ZR_Standard SG_ 960 ZAS_Kl_15 1000;
BA_REL_ "GenSigTimeoutTime" BU_SG_REL_ ZR_Standard SG_ 960 ZAS_Kl_50_Startanforderung 1000;
BA_REL_ "GenSigTimeoutTime" BU_SG_REL_ ZR_Standard SG_ 960 BCM_Remotestart_Betrieb 1000;
BA_REL_ "GenSigTimeoutTime" BU_SG_REL_ ZR_Standard SG_ 2589283621 KL_Umluft_Connect_status 5000;
BA_REL_ "GenSigTimeoutTime" BU_SG_REL_ ZR_Standard SG_ 2589283621 KL_ZR_Anforderung 5000;
BA_REL_ "GenSigTimeoutTime" BU_SG_REL_ ZR_Standard SG_ 779 KBI_Tankwarnung 500;
BA_REL_ "GenSigTimeoutTime" BU_SG_REL_ ZR_Standard SG_ 779 KBI_MFA_v_Einheit_01 500;
BA_REL_ "GenSigTimeoutTime" BU_SG_REL_ ZR_Standard SG_ 779 KBI_Tankwarnung_ungueltig 500;
BA_REL_ "GenSigTimeoutTime" BU_SG_REL_ ZR_Standard SG_ 779 KBI_V_Digital 500;
BA_REL_ "GenSigTimeoutTime" BU_SG_REL_ ZR_Standard SG_ 779 KBI_angez_Geschw 500;
VAL_ 497 KY_IDG_in_Reichweite 0 "ausser_Reichweite_bzw_nicht_ermittelbar" 1 "innerhalb_Reichweite" ;
VAL_ 497 KY_Auf_Taste 0 "Taste_nicht_betaetigt" 1 "Oeffnentaste_betaetigt" ;
VAL_ 497 KY_HDF_Taste 0 "Taste_nicht_betaetigt" 1 "HDF_Taste_am_Funkschluessel_betaetigt" ;
VAL_ 497 KY_Panik_Taste 0 "Taste_nicht_betaetigt" 1 "Panik_Taste_am_Funkschluessel_betaetigt" ;
VAL_ 497 KY_Zu_Taste 0 "Taste_nicht_betaetigt" 1 "Zu_Taste_am_Funkschluessel_betaetigt" ;
VAL_ 497 KY_FT_Entriegelung_Autorisiert 0 "kein_Keylessschluessel_erkannt" 1 "Keyless_Schluessel_erkannt_und_authorisiert" ;
VAL_ 497 KY_FT_Verriegelung_Autorisiert 0 "kein_Verriegelungssensor_erkannt" 1 "Verriegelungssensor_erkannt_und_authorisiert" ;
VAL_ 497 KY_BT_Entriegelung_Autorisiert 0 "kein_Keylessschluessel_erkannt" 1 "Keyless_Schluessel_erkannt_und_authorisiert" ;
VAL_ 497 KY_BT_Verriegelung_Autorisiert 0 "kein_Verriegelungssensor_erkannt" 1 "Verriegelungssensor_erkannt_und_authorisiert" ;
VAL_ 497 KY_HFS_Entriegelung_Autorisiert 0 "kein_Keylessschluessel_erkannt" 1 "Keyless_Schluessel_erkannt_und_authorisiert" ;
VAL_ 497 KY_HFS_Verriegelung_Autorisiert 0 "kein_Verriegelungssensor_erkannt" 1 "Verriegelungssensor_erkannt_und_authorisiert" ;
VAL_ 497 KY_HBFS_Entriegelung_Autorisiert 0 "kein_Keylessschluessel_erkannt" 1 "Keyless_Schluessel_erkannt_und_authorisiert" ;
VAL_ 497 KY_HBFS_Verriegelung_Autorisiert 0 "kein_Verriegelungssensor_erkannt" 1 "Verriegelungssensor_erkannt_und_authorisiert" ;
VAL_ 497 KY_Front_Entr_Autorisiert 0 "kein_Keylessschluessel_erkannt" 1 "Keyless_Schluessel_erkannt_und_authorisiert" ;
VAL_ 497 KY_Front_Verr_Autorisiert 0 "kein_Verriegelungssensor_erkannt" 1 "Verriegelungssensor_erkannt_und_authorisiert" ;
VAL_ 497 KY_HD_Entriegelung_Autorisiert 0 "kein_Keylessschluessel_erkannt" 1 "Keyless_Schluessel_erkannt_und_authorisiert" ;
VAL_ 497 KY_HD_Verriegelung_Autorisiert 0 "nicht_autorisiert" 1 "autorisiert" ;
VAL_ 497 KY_Bereich 0 "Bereich_0" 1 "Bereich_1" 2 "Bereich_2" 3 "Bereich_3" 4 "Bereich_4" 5 "Bereich_5" 6 "Kein_Schluessel_gefunden" 7 "Init" ;
VAL_ 497 KY_Position 0 "Position_0" 1 "Postition_1" 2 "Postition_2" 3 "Postition_3" 4 "Postition_4" 6 "Kein_Schluessel_gefunden" 7 "Init" ;
VAL_ 497 Schluesselnr_Personalisierung 1 "Schluesselnummer_eins_aktiv" 2 "Schluesselnummer_zwei_aktiv" 3 "Schluesselnummer_drei_aktiv" 4 "Schluesselnummer_vier_aktiv" 5 "Schluesselnummer_fuenf_aktiv" 6 "Schluesselnummer_sechs_aktiv" 7 "Schluesselnummer_sieben_aktiv" 8 "Schluesselnummer_acht_aktiv" 14 "Init" 15 "Fehler" ;
VAL_ 497 FFB_FDF_Taste 0 "Taste_nicht_betaetigt" 1 "FDF_Taste_am_Funkschluessel_betaetigt" ;
VAL_ 497 FFB_Joker_Taste 0 "Taste_nicht_betaetigt" 1 "Joker_Taste_an_FFFB_betaetigt" ;
VAL_ 497 FFB_Park_Taste 0 "Taste_nicht_betaetigt" 1 "Park_Taste_betaetigt" ;
VAL_ 497 FFB_Remotestart_Taste 0 "Taste_nicht_betaetigt" 1 "Remotestart_Taste_betaetigt" ;
VAL_ 497 FBS_Aktivierung_Pilot_Parken 0 "keine_Funktionsaktivierung" 1 "Aktivierung_FFB_erkannt" ;
VAL_ 497 KY_Schluessel_im_Fzg 0 "Schluessel_nicht_im_Fahrzeug" 1 "Schluessel_im_Fahrzeug" ;
VAL_ 497 KY_EasyClose_Abbruch 0 "EasyClose_kein_Abbruch" 1 "EasyClose_Abbruch" ;
VAL_ 497 KY_EasyClose_Status 0 "Lampe_AUS" 1 "Lampe_EIN" 2 "Lampe_NORMAL" 3 "Lampe_HEKTIK" 4 "Akustik_Verweigerung" ;
VAL_ 497 KY_HD_Auffahrt 0 "keine_Anforderung" 1 "HD_Auffahrt_angefordert" ;
VAL_ 497 KY_HD_Zufahrt 0 "keine_Anforderung" 1 "HD_Zufahrt_angefordert" ;
VAL_ 497 KY_LKL_1_Autorisierung 0 "Kein_Zugang_LKL_1_erkannt" 1 "Zugang_LKL_1_erkannt" ;
VAL_ 497 KY_LKL_2_Autorisierung 0 "Kein_Zugang_LKL_2_erkannt" 1 "Zugang_LKL_2_erkannt" ;
VAL_ 1424 FBS_Warn_Schluessel_Batt 0 "i.O." 1 "defekt" ;
VAL_ 1424 KY_FFB_Frequenz 0 "Init" 1 "433 MHz" 2 "315 MHz" 3 "868 MHz" ;
VAL_ 1424 KY_HF_Aktiv 0 "Funktempfang_nicht_aktiv" 1 "HF_Funkempfang_aktiv" ;
VAL_ 1424 KY_LF_Aktiv 0 "Funktempfang_nicht_aktiv" 1 "LF_Funkempfang_aktiv" ;
VAL_ 1424 KY_KYL_Fahrer_Hinweise 0 "keine_Anzeige" 1 "FZG_Zugang_Kein_Schluessel_erkannt" 2 "Schluessel_im_Innenraum_gefunden" 3 "Schluessel_im_Kofferraum_gefunden" 4 "FZG_Start_Kein_Schluessel_erkannt" 5 "FZG_Start_Kein_Schluessel_oder_NFC_erkannt" 6 "Warn_kein_NFC_erkannt" 7 "KL15_Keine_Autom_Aktivierung" ;
VAL_ 1424 KY_StartStopp_Info 0 "Motorlauf_nicht_notwendig_(Stoppfreigabe)" 1 "Motoranlauf_nicht_zwingend_notwendig_(Stoppverbot,keine_Startanforderung)" 2 "Motoranlauf_zwingend_notwendig_(Startanforderung)" 3 "Systemfehler" ;
VAL_ 1424 KY_Keyless_Verbau 0 "nicht_verbaut" 1 "verbaut" ;
VAL_ 1424 KY_Keyless_Go_Verbau 0 "nicht_verbaut" 1 "verbaut" ;
VAL_ 1424 KY_Transponder_aktiv 0 "nicht_aktiv" 1 "aktiv" ;
VAL_ 1424 KYL_Warn_kein_Schluessel 1 "kein Schluessel erkannt" ;
VAL_ 1424 KYL_Warn_Kessy_defekt 0 "Kessy_i.O." 1 "Kessy defekt" ;
VAL_ 1424 KYL_Warn_Notzuendschloss 0 "Aus" 1 "Ein" ;
VAL_ 1424 KY_Fzg_Verlassen_erkannt 0 "nicht_erkannt" 1 "erkannt" ;
VAL_ 1424 KY_Fzg_Zugang_erkannt 0 "nicht_erkannt" 1 "erkannt" ;
VAL_ 1424 KY_Indikator_Mehrere_Schluessel 0 "Init" 1 "Mehrere_Schluessel_im_Fahrzeug_gefunden" ;
VAL_ 1424 KY_NFC_Fahrer_Hinweise 0 "Init" 1 "Warn_kein_Keyless_gueltiges_NFC" 2 "Warn_gueltiges_Keyless_kein_NFC" ;
VAL_ 1424 KST_Wegstrecke_Challenge 0 "Init" ;
VAL_ 960 RSt_Fahrerhinweise 0 "Init" 1 "Fahreruebernahme_Hinweis_ZAT_Automat_ohne_Gong" 2 "Fahreruebernahme_Hinweis_ZAT_Automat_mit_Gong" 3 "Fahreruebernahme_Hinweis_ZAT_Handschalter_ohne_Gong" 4 "Fahreruebernahme_Hinweis_ZAT_Handschalter_mit_Gong" 5 "Fahreruebernahme_Hinweis_ZAS_Automat_ohne_Gong" 6 "Fahreruebernahme_Hinweis_ZAS_Automat_mit_Gong" 7 "Fahreruebernahme_Hinweis_ZAS_Handschalter_ohne_Gong" 8 "Fahreruebernahme_Hinweis_ZAS_Handschalter_mit_Gong" 9 "RemoteStart_aktiv_ohne_Gong" 10 "RemoteStart_aktiv_mit_Gong" 11 "void" 12 "void" 13 "void" 14 "void" 15 "void" ;
VAL_ 960 ZAS_Kl_S 0 "aus" 1 "S_Kontakt_ein" ;
VAL_ 960 ZAS_Kl_15 0 "aus" 1 "ein" ;
VAL_ 960 ZAS_Kl_X 0 "aus" 1 "ein" ;
VAL_ 960 ZAS_Kl_50_Startanforderung 0 "aus" 1 "KL50_ein_Startwunsch_Fahrer" ;
VAL_ 960 BCM_Remotestart_Betrieb 0 "kein_RS_Betrieb" 1 "RS_Betrieb" ;
VAL_ 960 ZAS_Kl_Infotainment 0 "inaktiv" 1 "aktiv" ;
VAL_ 960 BCM_Remotestart_KL15_Anf 0 "inaktiv" 1 "aktiv" ;
VAL_ 960 BCM_Remotestart_MO_Start 0 "nicht_angefordert" 1 "angefordert" ;
VAL_ 960 KST_Warn_P1_ZST_def 0 "nicht_defekt" 1 "defekt" ;
VAL_ 960 KST_Warn_P2_ZST_def 0 "nicht_defekt" 1 "defekt" ;
VAL_ 960 KST_Fahrerhinweis_1 0 "inaktiv" 1 "aktiv" ;
VAL_ 960 KST_Fahrerhinweis_2 0 "inaktiv" 1 "aktiv" ;
VAL_ 960 BCM_Ausparken_Betrieb 0 "kein_Betrieb" 1 "Ausparkvorgang_aktiv" ;
VAL_ 960 KST_Fahrerhinweis_4 0 "inaktiv" 1 "aktiv" ;
VAL_ 960 KST_Fahrerhinweis_5 0 "inaktiv" 1 "aktiv" ;
VAL_ 960 KST_Fahrerhinweis_6 0 "inaktiv" 1 "aktiv" ;
VAL_ 1420 KST_Txt_P_Gang 0 "Aus" 1 "Ein" ;
VAL_ 1420 KST_Txt_Panikabschaltung 0 "Aus" 1 "Ein" ;
VAL_ 1420 KST_Anf_Klemmenfreigabe_ELV 0 "nicht_angefordert" 1 "angefordert" ;
VAL_ 1420 KST_Txt_Komfortabschaltung 0 "inaktiv" 1 "aktiv" ;
VAL_ 1420 KST_ZAT_betaetigt 0 "Aus" 1 "Ein" ;
VAL_ 1420 KST_Unterdr_Zuendungsmeldung 0 "keine_Unterdr_der_Zuendungsmeldung" 1 "Unterdr_der_Zuendungsmeldung_aktiv" ;
VAL_ 1420 KST_aut_Abschaltung_Zuendung 0 "Zuendung_wird_bei_Verl_nicht_deaktiviert" 1 "Zuendung_wird_bei_Verl_deaktiviert" ;
VAL_ 1420 KST_Anf_ZV_Verriegelung 0 "inaktiv" 1 "aktiv" ;
VAL_ 1420 Relais_VoKo_angesteuert 0 "nicht_angesteuert" 1 "angesteuert" ;
VAL_ 1420 RSt_Anforderung_HMS 0 "keine_Anforderung" 1 "halten" 2 "parken" 3 "halten_Standby" 4 "anfahren" 5 "Loesen_ueber_Rampe" 6 "Parken_mit_P" ;
VAL_ 1646 KL_STL_aktiv 0 "Standlueftung_nicht_aktiv" 1 "Standlueftung_aktiv" ;
VAL_ 1646 KL_STH_aktiv 0 "Standheizung_nicht_aktiv" 1 "Standheizung_aktiv" ;
VAL_ 1646 KL_Solarluefter_aktiv 0 "Solarluefter_nicht_aktiv" 1 "Solarluefter_aktiv__auto" ;
VAL_ 1646 KL_Umluft_Taste 0 "Taste_nicht_gedrueckt" 1 "Taste_gedrueckt" ;
VAL_ 1646 KL_Geblaese_Fond_Status 0 "Geblaese_aus" 1 "Geblaesestufe_10" 2 "Geblaesestufe_20" 3 "Geblaesestufe_30" 4 "Geblaesestufe_40" 5 "Geblaesestufe_50" 6 "Geblaesestufe_60" 7 "Geblaesestufe_70" 8 "Geblaesestufe_80" 9 "Geblaesestufe_90" 10 "Geblaesestufe_100" 14 "Init" 15 "Fehler" ;
VAL_ 1646 KL_STH_Ansteuerung 0 "Aus" 1 "Ein" 2 "Ein_mit_Motorvorwaermung" 3 "Heizleistung_reduziert" ;
VAL_ 1646 KL_Magnetventil 0 "Aus" 1 "Ein" ;
VAL_ 1646 KL_WaPu 0 "Wasserpumpe_aus" 1 "Wasserpumpe_aktiv" ;
VAL_ 1646 KL_Geblaese_Status 0 "Geblaese_aus" 1 "Geblaesestufe_10" 2 "Geblaesestufe_20" 3 "Geblaesestufe_30" 4 "Geblaesestufe_40" 5 "Geblaesestufe_50" 6 "Geblaesestufe_60" 7 "Geblaesestufe_70" 8 "Geblaesestufe_80" 9 "Geblaesestufe_90" 10 "Geblaesestufe_100" 14 "Init" 15 "Fehler" ;
VAL_ 1646 KL_Restwaerme_aktiv 0 "inaktiv" 1 "aktiv" ;
VAL_ 1646 KL_Kompressorkupplung 0 "oeffnen" 1 "schliessen" ;
VAL_ 1646 KL_BCmE_Livetip_Freigabe 0 "Anzeige_Livetip_nicht_zulaessig" 1 "Anzeige_Livetip_zulaessig" ;
VAL_ 1646 KL_HYB_ASV_hinten_schliessen_Anf 0 "keine_Anforderung" 1 "Ventil_schliessen" ;
VAL_ 1646 KL_HYB_ASV_vorne_schliessen_Anf 0 "keine_Anforderung" 1 "Ventil_schliessen" ;
VAL_ 1646 KL_ErwVK_Zusatzrelais 0 "nicht_angefordert" 1 "angefordert" ;
VAL_ 1646 KL_Status_Beduftung 0 "inaktiv" 1 "aktiv" ;
VAL_ 1646 KL_Status_Ionisator_Front 0 "inaktiv" 1 "aktiv" ;
VAL_ 1646 KL_STH_Timer_Status 0 "TimerInaktiv" 1 "TimerAktiv" ;
VAL_ 1646 KL_ErwVK_Anf 0 "nicht_angefordert" 1 "angefordert" ;
VAL_ 1646 KL_Innen_Temp 253 "nicht_verbaut" 254 "nicht_verfuegbar" 255 "Fehler" ;
VAL_ 1646 KL_I_Geblaese_Fond 255 "Fehler" ;
VAL_ 1646 KL_Anf_AussenspiegelHzg 0 "nicht_angefordert" 1 "angefordert" ;
VAL_ 1646 KL_Heizkreisventilstellung 0 "Init" 1 "Ventilstellung_gem_Anforderung" 2 "Ventilstellung_abweichend_Anf" 3 "Fehler" ;
VAL_ 1646 KL_FSH_Automatikbetrieb 0 "aus" 1 "angefordert_durch_Regelung" ;
VAL_ 1646 KL_SIH_LEH_Verteilung_VL 0 "gleichmaessige_Verteilung" 1 "Sitz_Prio_Hoch" 2 "Sitz_Prio_Mittel" 3 "Sitz_Prio_Niedrig" 4 "Lehne_Prio_Niedrig" 5 "Lehne_Prio_Mittel" 6 "Lehne_Prio_Hoch" ;
VAL_ 1646 KL_SIH_LEL_Verteilung_VL 0 "gleichmaessige_Verteilung" 1 "Sitz_Prio_Hoch" 2 "Sitz_Prio_Mittel" 3 "Sitz_Prio_Niedrig" 4 "Lehne_Prio_Niedrig" 5 "Lehne_Prio_Mittel" 6 "Lehne_Prio_Hoch" ;
VAL_ 1646 KL_SIH_LEH_Verteilung_VR 0 "gleichmaessige_Verteilung" 1 "Sitz_Prio_Hoch" 2 "Sitz_Prio_Mittel" 3 "Sitz_Prio_Niedrig" 4 "Lehne_Prio_Niedrig" 5 "Lehne_Prio_Mittel" 6 "Lehne_Prio_Hoch" ;
VAL_ 1646 KL_SIH_LEL_Verteilung_VR 0 "gleichmaessige_Verteilung" 1 "Sitz_Prio_Hoch" 2 "Sitz_Prio_Mittel" 3 "Sitz_Prio_Niedrig" 4 "Lehne_Prio_Niedrig" 5 "Lehne_Prio_Mittel" 6 "Lehne_Prio_Hoch" ;
VAL_ 1663 KL_Mod_Display_li 0 "Solltemperatur" 1 "Luftverteilung" 2 "Sitzheizung" 3 "Sitzlueftung" 4 "Luftmenge" 9 "OBD" 10 "Display_off" ;
VAL_ 1663 KL_Mod_Display_re 0 "Solltemperatur" 1 "Luftverteilung" 2 "Sitzheizung" 3 "Sitzlueftung" 4 "Luftmenge" 9 "OBD" 10 "Display_off" ;
VAL_ 1663 KL_Fondbed_vorne_aktiv 0 "nicht_aktiv" 1 "Bedienung_von_vorne_ist_aktiv" ;
VAL_ 1663 KL_Fond_re_reduziert 1 "Leistungsreduzierung" ;
VAL_ 1663 KL_Fond_li_reduziert 1 "Leistungsreduzierung" ;
VAL_ 1663 KL_Absperrventil_Fond 0 "nicht_ansteuern" 1 "ansteuern" ;
VAL_ 1663 KL_SH_HL_Lastabschaltung 0 "keine_Einschraenkung" 1 "Taktung" 2 "Abschaltung" ;
VAL_ 1663 KL_SH_HR_Lastabschaltung 0 "keine_Einschraenkung" 1 "Taktung" 2 "Abschaltung" ;
VAL_ 1663 KL_Sollausblastemp_HL 1023 "Fehler" ;
VAL_ 1663 KL_Einheiten 0 "°C" 1 "°F" ;
VAL_ 1663 KL_Kindersicherung 0 "nicht_aktiv" 1 "aktiv" ;
VAL_ 1663 KL_Heizverbraucher_aus 0 "keine_Einschraenkung" 1 "Heizverbraucher_deaktivieren" ;
VAL_ 1663 KL_Heizverbraucher_Notaus 0 "keine_Einschraenkung" 1 "Heizverbraucher_sofort_deaktivieren" ;
VAL_ 1663 KL_Gebl_Verst_Abs_Modus 0 "Aus" 1 "Ein" ;
VAL_ 1663 KL_Sollausblastemp_HR 1023 "Fehler" ;
VAL_ 1663 KL_ICO2_Sensor_defekt 0 "Init" 1 "nicht_defekt" 2 "defekt" 3 "CO2_Warnung" ;
VAL_ 1663 KL_Umluft 254 "Init" 255 "Fehler" ;
VAL_ 1608 KL_AUTO_HL_Soll 0 "AUTO_nicht_aktiv" 1 "AUTO_aktiv" ;
VAL_ 1608 KL_AUTO_HR_Soll 0 "AUTO_nicht_aktiv" 1 "AUTO_aktiv" ;
VAL_ 1608 KL_AC_Fond_Soll 0 "AC_nicht_aktiv" 1 "AC_aktiv" ;
VAL_ 1608 KL_Fondbedienung_aktiv 0 "nicht_aktiv" 1 "aktiv" ;
VAL_ 1608 KL_Status_Soll 0 "AUS" 1 "EIN" ;
VAL_ 1608 KL_Luftverteilung_HR_Soll 0 "MA" 1 "Fussraum" 2 "PfostenB" 3 "MA+Fuß" 4 "MA+PfostenB" 5 "Fuß+PfostenB" 6 "MA+Fuß+PfostenB" 7 "AUTO-LV" ;
VAL_ 1608 KL_Luftverteilung_HL_Soll 0 "MA" 1 "Fussraum" 2 "PfostenB" 3 "MA+Fuß" 4 "MA+PfostenB" 5 "Fuß+PfostenB" 6 "MA+Fuß+PfostenB" 7 "AUTO-LV" ;
VAL_ 949 KL_Drehz_Anh 0 "keine_Anhebung" 1 "Drehzahlanhebung_vom_Motor_angefordert" ;
VAL_ 949 KL_Vorwarn_Komp_ein 0 "Init" 1 "Vorwarnung_Kompressor_ein" ;
VAL_ 949 KL_AC_Schalter 0 "aus" 1 "ein" ;
VAL_ 949 KL_Komp_Moment_alt 1 "veraltet_bzw_Ermittlung_des_Moments_nicht_moeglich__zB_keine_Drehzahl_kein_Kaeltemitteldruck" ;
VAL_ 949 KL_Vorwarn_Zuheizer_ein 0 "keine_Vorwarnung" 1 "Vorwarnung_Zuheizer_ein" ;
VAL_ 949 KL_Zustand 0 "Aus" 1 "Ein" ;
VAL_ 949 KL_Kompressorkupplung_linear 253 "volle_Ansteuerung" 254 "Init__nicht_bedient" ;
VAL_ 949 KL_Charisma_FahrPr 0 "keine_Funktion" 1 "Programm_1" 2 "Programm_2" 3 "Programm_3" 4 "Programm_4" 5 "Programm_5" 6 "Programm_6" 7 "Programm_7" 8 "Programm_8" 9 "Programm_9" 10 "Programm_10" 11 "Programm_11" 12 "Programm_12" 13 "Programm_13" 14 "Programm_14" 15 "Programm_15" ;
VAL_ 949 KL_Charisma_Status 0 "Init" 1 "verfuegbar" 2 "nicht_verfuegbar" 3 "asynchron_durch_Fahrerwunsch" ;
VAL_ 949 KL_nachtr_Stopp_Anf 0 "nicht_angefordert" 1 "angefordert" ;
VAL_ 949 KL_T_Charge 0 "Taster_nicht_betaetigt" 1 "Taster_betaetigt" ;
VAL_ 949 KL_Last_Kompr 255 "Fehler" ;
VAL_ 949 KL_Spannungs_Anf 0 "keine_Anforderung" 1 "Anforderung_Stufe_1" 2 "Anforderung_Stufe_2" 3 "Anforderung_Stufe_3" ;
VAL_ 949 KL_Thermomanagement 0 "keine_Freigabe_TMM__max_Heizbedarf" 1 "kleine_Freigabe_TMM" 2 "mittlere_Freigabe_TMM" 3 "volle_Freigabe_TMM__kein_Heizbedarf" ;
VAL_ 949 KL_StartStopp_Info 0 "Motorlauf_nicht_notwendig_(Stoppfreigabe)" 1 "Motoranlauf_nicht_zwingend_notwendig_(Stoppverbot,keine_Startanforderung)" 2 "Motoranlauf_zwingend_notwendig_(Startanforderung)" 3 "Systemfehler" ;
VAL_ 949 KL_Freilauf_Info 0 "Freilauf_freigegeben" 1 "Uebergang_in_Freilauf_unzulaessig" 2 "Freilauf_nicht_freigegeben_Abbruch" 3 "Freilauf_Anforderung" ;
VAL_ 949 KL_Anf_KL 255 "Fehler" ;
VAL_ 949 KL_el_Zuheizer_Stufe 0 "Aus" 1 "Stufe_1" 2 "Stufe_2" 3 "Stufe_3" ;
VAL_ 949 KL_Ausstattung_Klima 0 "Heizung_elektrisch" 1 "Klimamanuell_elektrisch" 2 "Climatic__1_Zone" 3 "Climatronic__1_Zone" 4 "Climatronic__2_Zonen" 5 "Climatronic__3_Zonen" 6 "Climatronic__4_Zonen" 7 "reserviert" ;
VAL_ 949 KL_Variante_Standheizung 0 "Wasserstandheizung_60_min_Laufzeit" 1 "Luftstandheizung_120_min_Laufzeit" 2 "Wasserstandheizung_120_min_Laufzeit" 3 "Wasser_und_Luftstandheizung_120_min_Laufzeit" ;
VAL_ 1640 KL_LRH_Taster 0 "nicht_betaetigt" 1 "betaetigt" ;
VAL_ 1640 KL_LRH_Stufe 0 "Stufe_niedrig" 1 "Stufe_mittel" 2 "Stufe_hoch" 3 "AUS" ;
VAL_ 1640 HSH_Taster 0 "nicht_betaetigt" 1 "short_push" 2 "long_push" 3 "tbd" ;
VAL_ 1640 FSH_Taster 0 "nicht_betaetigt" 1 "betaetigt" ;
VAL_ 1640 KL_Zuheizer_Freigabe 0 "keine_Freigabe_Zuheizer" 1 "Zuheizerfreigabe" ;
VAL_ 1640 KL_Beschlagsgefahr 0 "keine_Beschlagsgefahr" 1 "Beschlagsgefahr" ;
VAL_ 1640 KRH_Soll_li 0 "aus" 1 "Stufe_1" 2 "Stufe_2" 3 "Stufe_3" ;
VAL_ 1640 KRH_Soll_re 0 "aus" 1 "Stufe_1" 2 "Stufe_2" 3 "Stufe_3" ;
VAL_ 1640 KL_Geblspng_Soll 0 "0V_Motorspannung" 252 "0V_sofort_Abschalten" 253 "0V_senken_mit_Rampe" 254 "reserviert" 255 "Fehler" ;
VAL_ 1640 KL_Geblspng_Fond_Soll 0 "0V_Motorspannung" 252 "0V_sofort_Abschalten" 253 "0V_senken_mit_Rampe" 254 "reserviert" 255 "Fehler" ;
VAL_ 1640 KL_I_Geblaese 255 "Fehler" ;
VAL_ 1640 KL_Kompressorstrom_soll 1022 "Init" 1023 "Fehler" ;
VAL_ 1640 KL_Umluftklappe_Status 0 "Frischluft" 1 "Teilumluft_10" 2 "Teilumluft_20" 3 "Teilumluft_30" 4 "Teilumluft_40" 5 "Teilumluft_50" 6 "Teilumluft_60" 7 "Teilumluft_70" 8 "Teilumluft_80" 9 "Teilumluft_90" 10 "Umluft" 14 "Init" 15 "Fehler" ;
VAL_ 1640 KL_PTC_Verbauinfo 0 "kein_PTC" 1 "600W_geschaltet" 2 "1000W_geschaltet" 3 "1400W_LIN" ;
VAL_ 1441 KL_Temp_Soll_hl 30 "Klima_OFF" 31 "Init" ;
VAL_ 1441 KL_Temp_Soll_hr 30 "Klima_OFF" 31 "Init" ;
VAL_ 1441 KL_Temp_Soll_vl 30 "Klima_OFF" 31 "Init" ;
VAL_ 1441 KL_Temp_Soll_vr 30 "Klima_OFF" 31 "Init" ;
VAL_ 1441 KL_SIH_Stufe_hl 7 "nicht_verbaut" ;
VAL_ 1441 KL_SIH_Stufe_hr 7 "nicht_verbaut" ;
VAL_ 1441 KL_SIL_Stufe_hl 7 "nicht_verbaut" ;
VAL_ 1441 KL_SIL_Stufe_hr 7 "nicht_verbaut" ;
VAL_ 1441 KL_SIL_LEL_Verteilung_HR 0 "gleichmaessige_Verteilung" 1 "Sitz_Prio_Hoch" 2 "Sitz_Prio_Mittel" 3 "Sitz_Prio_Niedrig" 4 "Lehne_Prio_Niedrig" 5 "Lehne_Prio_Mittel" 6 "Lehne_Prio_Hoch" ;
VAL_ 1441 KL_SIL_LEL_Verteilung_HL 0 "gleichmaessige_Verteilung" 1 "Sitz_Prio_Hoch" 2 "Sitz_Prio_Mittel" 3 "Sitz_Prio_Niedrig" 4 "Lehne_Prio_Niedrig" 5 "Lehne_Prio_Mittel" 6 "Lehne_Prio_Hoch" ;
VAL_ 1441 KL_SIH_LEH_Verteilung_HR 0 "gleichmaessige_Verteilung" 1 "Sitz_Prio_Hoch" 2 "Sitz_Prio_Mittel" 3 "Sitz_Prio_Niedrig" 4 "Lehne_Prio_Niedrig" 5 "Lehne_Prio_Mittel" 6 "Lehne_Prio_Hoch" ;
VAL_ 1441 KL_PTC_linear_Anf 0 "Init" 63 "Fehler" ;
VAL_ 1441 KL_SIH_LEH_Verteilung_HL 0 "gleichmaessige_Verteilung" 1 "Sitz_Prio_Hoch" 2 "Sitz_Prio_Mittel" 3 "Sitz_Prio_Niedrig" 4 "Lehne_Prio_Niedrig" 5 "Lehne_Prio_Mittel" 6 "Lehne_Prio_Hoch" ;
VAL_ 1441 KL_Frischluftklappe_Status 126 "Init" 127 "Fehler" ;
VAL_ 2589283621 KL_NV_Energie_Anf 254 "Init" 255 "Fehler" ;
VAL_ 2589283621 KL_Umluft_Connect_status 0 "Keine_Umluft" 1 "Umluft_Kundenwunsch" 2 "Umluft_AQS" 3 "Umluft_Backend_Empfehlung" 4 "Umluft_Navi_Daten" ;
VAL_ 2589283621 KL_ECO_PRO_Aktiv 0 "inaktiv" 1 "aktiv" ;
VAL_ 2589283621 KL_QBit_Sonnenintensitaet 0 "gueltiger_Wert" 1 "Ersatz_Init_oder_Fehlerwert" ;
VAL_ 2589283621 KL_ZR_Anforderung 0 "init" 1 "inaktiv" 2 "aktiv" 3 "reserviert" ;
VAL_ 2589283621 KL_ACmax_Aktiv 0 "inaktiv" 1 "aktiv" ;
VAL_ 2589283621 KL_Defrost_Aktiv 0 "inaktiv" 1 "aktiv" ;
VAL_ 2589283621 KL_ECO_Aktiv 0 "inaktiv" 1 "aktiv" ;
VAL_ 2589283621 KL_Status_Klimastil 0 "Modus_1" 1 "Modus_2" 2 "Modus_3" 3 "Modus_4" ;
VAL_ 2589283621 KL_Kundeneingriff_Geblaese 0 "Kein_Kundeneingriff_Geblaese" 1 "Kundeneingriff_Geblaese_aktiv" ;
VAL_ 2589283621 KL_Thermischer_Bedarf 0 "Aus" 1 "Heizen" 2 "Nachlauf_Heizen" 3 "Lueften" 4 "Kuehlen" 6 "Init" 7 "Fehler" ;
VAL_ 2589283621 KL_Eps_Innen 254 "Init" 255 "Fehler" ;
VAL_ 2589283621 KL_Sonnenintensitaet 255 "Fehler" ;
VAL_ 992 KL_Fond_Fuss_Temp_hl 1022 "Init" 1023 "Fehler" ;
VAL_ 992 KL_Fond_Fuss_Temp_hr 1022 "Init" 1023 "Fehler" ;
VAL_ 992 KL_MA_Temp_hl 1022 "Init" 1023 "Fehler" ;
VAL_ 992 KL_SIH_Takt_hl 0 "Aus" 1 "Ein" ;
VAL_ 992 KL_SIH_Takt_hr 0 "Aus" 1 "Ein" ;
VAL_ 992 KL_Fehler_Umluft 0 "Umluftklappe_iO" 1 "Umluftklappe_niO" ;
VAL_ 992 KL_RAB 0 "keine_Auswirkung_auf_Klimasystem" 1 "Fehler_hat_Auswirkung_auf_die_Klimatisierung" ;
VAL_ 992 KL_Fond_Absperrventil 0 "nicht angesteuert" 1 "wird angesteuert" ;
VAL_ 992 KL_Fond_KD_Fehler 0 "kein_KD_Fehler" 1 "KD_Fehler" ;
VAL_ 992 KL_MA_Temp_hr 1022 "Init" 1023 "Fehler" ;
VAL_ 992 KL_Fehler_Fussraum_Klappen 0 "kein_Fehler" 1 "Fehler_Fuss_li" 2 "Fehler_Fuss_re" 3 "Beide_Klappen_defekt" ;
VAL_ 992 KL_Fehler_Temp_Klappen 0 "kein_Fehler" 1 "Fehler_Temp_li" 2 "Fehler_Temp_re" 3 "Beide_Klappen_defekt" ;
VAL_ 992 KL_Fehler_Temp_MA_Klappen 0 "kein_Fehler" 1 "Fehler_MA_li" 2 "Fehler_MA_re" 3 "Beide_Klappen_defekt" ;
VAL_ 1712 FS_Taupunkt 0 "nicht verfuegbar" 1023 "Fehler" ;
VAL_ 1712 FS_ResponseError 0 "normal" 1 "Fehler" ;
VAL_ 1712 FS_Temp_Scheibe 0 "nicht verfuegbar" 1023 "Fehler" ;
VAL_ 1712 FS_Temp_Sensor 0 "nicht verfuegbar" 255 "Fehler" ;
VAL_ 1712 FS_Luftfeuchte_rel 0 "nicht verfuegbar" 255 "Fehler" ;
VAL_ 1505 BCM1_Aussen_Temp_ungef 253 "nicht_verbaut" 254 "Initwert" 255 "Fehler" ;
VAL_ 1505 BCM_Heizungsabsperrventil_Status 0 "HAV_offen" 1 "HAV_geschlossen" 2 "Init_oder_nicht_verbaut" 3 "Fehler" ;
VAL_ 1505 BCM_Heizungspumpe_Status 0 "Pumpe_aus" 1 "Pumpe_aktiv_und_Stauts_iO" 2 "Init_oder_nicht_verbaut" 3 "Fehler" ;
VAL_ 1505 BCM_Kompressorkupplung_Status 0 "Kupplung_offen" 1 "Kupplung_geschlossen" 2 "Init_oder_nicht_verbaut" 3 "Fehler" ;
VAL_ 1505 BCM1_PTC_stufig_Status 0 "Aus" 1 "Stufe_1_aktiv" 2 "Stufe_2_aktiv" 3 "Stufe_3_aktiv" 6 "Init_oder_nicht_verbaut" 7 "Fehler" ;
VAL_ 1505 BCM1_FStatus_Aussentemp_ungef 0 "iO" 1 "niO" ;
VAL_ 1505 BCM1_Kompressorstrom_ist 254 "Init, bzw. nicht verfuegbar" 255 "Fehler" ;
VAL_ 1505 BCM1_OBD_FStatus_ATemp 0 "kein Fehler / Init / nicht verbaut" 1 "KS- (Kurzschluss nach minus)" 2 "KS+ (Kurzschluss nach plus)" 3 "OC (Leitungsunterbrechung)" 4 "OOR+ (Signal zu gross)" 5 "OOR- (Signal zu klein)" 6 "RC+ (Signal unplausibel zu gross)" 7 "RC- (Signal unplausibel zu klein)" 8 "KS+/OC (Kurzschluss nach plus/Unterbrechung)" 9 "KS-/OC  (Kurzschluss nach minus/Unterbrechung)" 10 "KS-/KS+  (Kurzschluss nach minus/plus)" 11 "KS-/KS+/OC (Kurzschluss nach minus/plus/Unterbrechung)" 12 "frei" 13 "frei" 14 "frei" 15 "frei" ;
VAL_ 605 KLR_Fehler 0 "kein_Fehler" 1 "Fehler" ;
VAL_ 605 KLR_ResponseError 0 "normal" 1 "Fehler" ;
VAL_ 605 KLR_Lokalaktiv 0 "war_nicht_lokal_aktiv" 1 "war_lokal_aktiv" ;
VAL_ 605 KLR_Fehler_Codierung 0 "Kein_Fehler" 1 "Fehler" ;
VAL_ 605 KLR_Touchintensitaet_1 251 "Kalibrierung" 252 "nicht_verfuegbar" 253 "res" 254 "Init" 255 "Fehler" ;
VAL_ 605 KLR_Touchintensitaet_2 251 "Kalibrierung" 252 "nicht_verfuegbar" 253 "res" 254 "Init" 255 "Fehler" ;
VAL_ 605 KLR_Touchintensitaet_3 251 "Kalibrierung" 252 "nicht_verfuegbar" 253 "res" 254 "Init" 255 "Fehler" ;
VAL_ 605 KLR_Touchauswertung 0 "Keine_Beruehrung" 1 "Leicht_beruehrt_innen" 2 "Leicht_beruehrt_links" 3 "Leicht_beruehrt_rechts" 4 "Leicht_beruehrt_links_rechts" 5 "Leicht_umgriffen_links" 6 "Leicht_umgriffen_rechts" 7 "Leicht_umgriffen_links_rechts" 8 "Stark_umgriffen_links" 9 "Stark_umgriffen_rechts" 10 "Stark_umgriffen_links_rechts" 11 "res" 12 "res" 13 "Kalibrierung" 14 "Init" 15 "Fehler_Touchauswertung" ;
VAL_ 2549088398 BedienDisp_vo_KompSchutz 0 "inaktiv" 1 "aktiv" ;
VAL_ 2549088398 BedienDisp_vo_Abschaltstufe 0 "keine_Einschraenkung" 1 "Funktionseinschraenkung" ;
VAL_ 2549088398 BedienDisp_vo_Transport_Mode 0 "keine_Einschraenkung" 1 "Funktionseinschraenkung" ;
VAL_ 2549088398 BedienDisp_vo_Nachlauftyp 0 "Komm_bei_KL15_EIN" 1 "Komm_nach_KL15_AUS" 2 "Komm_bei_KL15_AUS" ;
VAL_ 2549088398 BedienDisp_vo_SNI 142 "BedienDisp_vo" ;
VAL_ 2549088398 KN_BedienDisp_v_ECUKnockOutTimer 63 "ECUKnockOut_deaktiviert" ;
VAL_ 2549088398 KN_BedienDisp_v_BusKnockOut 0 "Funktion_nicht_ausgeloest" 1 "Veto_aktiv" 2 "Funktion_ausgeloest" 3 "Funktion_deaktiviert" ;
VAL_ 2549088398 KN_BedienDisp_v_BusKnockOutTimer 255 "BusKnockOut_deaktiviert" ;
VAL_ 2549088398 NM_BedienDisp_vo_Wakeup 0 "Peripherie_Wakeup__Ursache_nicht_bekannt" 1 "Bus_Wakeup" 2 "KL15_HW" 3 "Restwaerme_Menuauswahl" 4 "SAD_Taster" ;
VAL_ 2549088398 KN_BedienDisp_v_ECUKnockOut 0 "Funktion_nicht_ausgeloest" 1 "Veto_war_aktiv" 2 "Funktion_ausgeloest" 3 "Funktion_deaktiviert" ;
VAL_ 2549088398 NMH_BedienDisp_vo_Lokalaktiv 0 "war_nicht_lokal_aktiv" 1 "war_lokal_aktiv" ;
VAL_ 2549088398 NMH_BedienDisp_vo_Subsystemaktiv 0 "Subsystem_war_nicht_lokalaktiv" 1 "war_lokalaktiv" ;
VAL_ 2549088398 BedienDisp_vo_KD_Fehler 0 "kein_KD_Fehler" 1 "KD_Fehler" ;
VAL_ 2549088403 BedienSG_hi_KompSchutz 0 "inaktiv" 1 "aktiv" ;
VAL_ 2549088403 BedienSG_hi_Abschaltstufe 0 "keine_Einschraenkung" 1 "Funktionseinschraenkung" ;
VAL_ 2549088403 BedienSG_hi_Transport_Mode 0 "keine_Einschraenkung" 1 "Funktionseinschraenkung" ;
VAL_ 2549088403 BedienSG_hi_Nachlauftyp 0 "Komm_bei_KL15_EIN" 1 "Komm_nach_KL15_AUS" 2 "Komm_bei_KL15_AUS" ;
VAL_ 2549088403 BedienSG_hi_SNI 147 "BedienSG_hi" ;
VAL_ 2549088403 KN_BedienSG_hi_ECUKnockOutTimer 63 "ECUKnockOut_deaktiviert" ;
VAL_ 2549088403 KN_BedienSG_hi_BusKnockOut 0 "Funktion_nicht_ausgeloest" 1 "Veto_aktiv" 2 "Funktion_ausgeloest" 3 "Funktion_deaktiviert" ;
VAL_ 2549088403 KN_BedienSG_hi_BusKnockOutTimer 255 "BusKnockOut_deaktiviert" ;
VAL_ 2549088403 NMH_BedienSG_hi_Wakeup 0 "Peripherie_Wakeup__Ursache_nicht_bekannt" 1 "Bus_Wakeup" 2 "KL15_HW" ;
VAL_ 2549088403 KN_BedienSG_hi_ECUKnockOut 0 "Funktion_nicht_ausgeloest" 1 "Veto_war_aktiv" 2 "Funktion_ausgeloest" 3 "Funktion_deaktiviert" ;
VAL_ 2549088403 NMH_BedienSG_hi_Lokalaktiv 0 "war_nicht_lokal_aktiv" 1 "war_lokal_aktiv" ;
VAL_ 2549088403 NMH_BedienSG_hi_Subsystemaktiv 0 "Subsystem_war_nicht_lokalaktiv" 1 "war_lokalaktiv" ;
VAL_ 2549088403 BedienSG_hi_KD_Fehler 0 "kein_KD_Fehler" 1 "KD_Fehler" ;
VAL_ 2549088442 DDA_KompSchutz 0 "inaktiv" 1 "aktiv" ;
VAL_ 2549088442 DDA_Abschaltstufe 0 "keine_Einschraenkung" 1 "Funktionseinschraenkung" ;
VAL_ 2549088442 DDA_Transport_Mode 0 "keine_Einschraenkung" 1 "Funktionseinschraenkung" ;
VAL_ 2549088442 DDA_Nachlauftyp 0 "Komm_bei_KL15_EIN" 1 "Komm_nach_KL15_AUS" 2 "Komm_bei_KL15_AUS" ;
VAL_ 2549088442 DDA_SNI 186 "DDA" ;
VAL_ 2549088442 KN_DDA_BusKnockOutTimer 255 "BusKnockOut_deaktiviert" ;
VAL_ 2549088442 NM_DDA_Wakeup 0 "Peripherie_Wakeup__Ursache_nicht_bekannt" 1 "Bus_Wakeup" 2 "KL15_HW" 3 "Bluetoothverbindung_aktiv" ;
VAL_ 2549088442 NM_DDA_Lokalaktiv 0 "war_nicht_Lokalaktiv" 1 "war_Lokalaktiv" ;
VAL_ 2549088442 DDA_KD_Fehler 0 "kein_KD_Fehler" 1 "KD_Fehler" ;
VAL_ 2549088272 Gateway_KompSchutz 0 "inaktiv" 1 "aktiv" ;
VAL_ 2549088272 Gateway_Abschaltstufe 0 "keine_Einschraenkung" 1 "Funktionseinschraenkung" ;
VAL_ 2549088272 Gateway_Transport_Mode 0 "keine_Einschraenkung" 1 "Funktionseinschraenkung" ;
VAL_ 2549088272 Gateway_Nachlauftyp 0 "Komm_bei_KL15_EIN" 1 "Komm_nach_KL15_AUS" 2 "Komm_bei_KL15_AUS" ;
VAL_ 2549088272 Gateway_SNI 16 "Gateway" ;
VAL_ 2549088272 NM_Gateway_Wakeup 0 "Peripherie_Wakeup__Ursache_nicht_bekannt" 1 "Bus_Wakeup" 2 "KL15_HW" 3 "ACAN_Wakeup" 4 "FCAN_Wakeup" 5 "KCAN_Wakeup" 6 "ICAN_Wakeup" 7 "DiagCAN_Wakeup" 8 "ECAN_Wakeup" 9 "Energie_LIN_Wakeup" 10 "Bedien_LIN_Wakeup" 11 "HybridCAN_Wakeup" 12 "Flexray_Wakeup" 13 "MFL_WakeUp" 14 "Ethernet" 15 "DCAN_Wakeup" 16 "K2CAN_Wakeup" 17 "CCAN" 18 "AFSCAN_Wakeup" 32 "FlexRay_Branch1_WakeUp" 33 "FlexRay_Branch2_WakeUp" 34 "FlexRay_Branch3_WakeUp" 35 "FlexRay_Branch4_WakeUp" 36 "FlexRay_Branch5_WakeUp" 37 "FlexRay_Branch6_WakeUp" 38 "FlexRay_Branch7_WakeUp" 39 "FlexRay_Branch8_WakeUp" 40 "FlexRay_Branch9_WakeUp" 41 "FlexRay_Branch10_WakeUp" 42 "FlexRay_Branch11_WakeUp" 43 "FlexRay_Branch12_WakeUp" 44 "FlexRay_Branch13_WakeUp" 45 "FlexRay_Branch14_WakeUp" 46 "FlexRay_Branch15_WakeUp" 47 "FlexRay_Branch16_WakeUp" 128 "Energiemanagement" 129 "Funktionswakeup_OBDC" 130 "Hochvoltenergiemanagement" 131 "CWU_empfangen" 132 "Fuer_Bus_relevanten_FC_empfangen" 133 "OnlineDienst_empfangen" 134 "HV_Aktivieren" 135 "HV_Deaktivieren" 136 "VTS_Suche_DriverCard" 137 "VTS_Hupen_Blinken" 138 "Remote_Vehicle_Status" 139 "Plug_and_Charge" 140 "VTS_Wakeup_Infotainment" 141 "EMHLR" 142 "NFcGW_fordert_OTA_FC_an" 143 "Komponentenschutz" 144 "UserStateServer" 145 "Dimmung" 146 "Kessy" 147 "StandardAussenlicht" 148 "ParkKoordinator" 149 "HVLMDynamicChargingPOI" 150 "HVLMChargingManagementServer" 151 "HVLMExtendedChargingMonitoring" 152 "Zentralverriegelung" 153 "FunctionOnDemand" 154 "IAA" 155 "StandKlimatisierung" 156 "RealTimeMonitor" 157 "Klemmensteuerung" ;
VAL_ 2549088272 NM_Gateway_Lokalaktiv 0 "war_nicht_lokal_aktiv" 1 "war_lokal_aktiv" ;
VAL_ 2549088272 NM_Gateway_Subsystemaktiv 0 "Subsystem_war_nicht_lokalaktiv" 1 "war_lokalaktiv" ;
VAL_ 2549088272 GW_KD_Fehler 0 "kein_KD_Fehler" 1 "KD_Fehler" ;
VAL_ 2549088355 GM_KompSchutz 0 "inaktiv" 1 "aktiv" ;
VAL_ 2549088355 GM_Abschaltstufe 0 "keine_Einschraenkung" 1 "Funktionseinschraenkung" ;
VAL_ 2549088355 GM_Transport_Mode 0 "keine_Einschraenkung" 1 "Funktionseinschraenkung" ;
VAL_ 2549088355 GM_Nachlauftyp 0 "Komm_bei_KL15_EIN" 1 "Komm_nach_KL15_AUS" 2 "Komm_bei_KL15_AUS" ;
VAL_ 2549088355 GM_SNI 99 "GM" ;
VAL_ 2549088355 NM_GM_Wakeup 0 "Peripherie_Wakeup__Ursache_nicht_bekannt" 1 "Bus_Wakeup" 2 "KL15_HW" ;
VAL_ 2549088355 GM_Lokalaktiv 0 "war_nicht_lokal_aktiv" 1 "war_lokal_aktiv" ;
VAL_ 2549088355 GM_Subsystemaktiv 0 "Subsystem_war_nicht_lokalaktiv" 1 "war_lokalaktiv" ;
VAL_ 2549088355 GM_KD_Fehler 0 "kein_KD_Fehler" 1 "KD_Fehler" ;
VAL_ 2549088371 Info_El_KompSchutz 0 "inaktiv" 1 "aktiv" ;
VAL_ 2549088371 Info_El_Abschaltstufe 0 "keine_Einschraenkung" 1 "Funktionseinschraenkung" ;
VAL_ 2549088371 Info_El_Transport_Mode 0 "keine_Einschraenkung" 1 "Funktionseinschraenkung" ;
VAL_ 2549088371 Info_El_Nachlauftyp 0 "Komm_bei_KL15_EIN" 1 "Komm_nach_KL15_AUS" 2 "Komm_bei_KL15_AUS" ;
VAL_ 2549088371 Info_El_SNI 115 "Info_El" ;
VAL_ 2549088371 KN_Info_El_BusKnockOutTimer 255 "BusKnockOut_deaktiviert" ;
VAL_ 2549088371 NM_Info_El_Wakeup 0 "Peripherie_Wakeup__Ursache_nicht_bekannt" 1 "Bus_Wakeup" 2 "KL15_HW" 3 "Eject_Button" 4 "Remote_Lock_Unlock" 5 "Remote_Standheizung" 128 "WakeUp_Lock_Anf" 129 "Display_On_Anf" 130 "HMI_OnlineUpdate" ;
VAL_ 2549088371 NM_Info_El_Lokalaktiv 0 "war_nicht_lokal_aktiv" 1 "war_lokal_aktiv" ;
VAL_ 2549088371 NM_Info_El_Subsystemaktiv 0 "Subsystem_war_nicht_lokalaktiv" 1 "war_lokalaktiv" ;
VAL_ 2549088371 Info_El_KD_Fehler 0 "Kein KD_Fehler" 1 "KD_Fehler" ;
VAL_ 2549088258 Sekundaer_02_KompSchutz 0 "inaktiv" 1 "aktiv" ;
VAL_ 2549088258 Sekundaer_02_Abschaltstufe 0 "keine_Einschraenkung" 1 "Funktionseinschraenkung" ;
VAL_ 2549088258 Sekundaer_02_Transport_Mode 0 "keine_Einschraenkung" 1 "Funktionseinschraenkung" ;
VAL_ 2549088258 Sekundaer_02_Nachlauftyp 0 "Komm_bei_KL15_EIN" 1 "Komm_nach_KL15_AUS" 2 "Komm_bei_KL15_AUS" ;
VAL_ 2549088258 Sekundaer_02_SNI 2 "Sekundaer_02" ;
VAL_ 2549088258 NM_Sekundaer_02_Wakeup 0 "Peripherie_Wakeup__Ursache_nicht_bekannt" 1 "Bus_Wakeup" 2 "KL15_HW" ;
VAL_ 2549088258 NM_Sekundaer_02_Lokalaktiv 0 "war_nicht_lokal_aktiv" 1 "war_lokal_aktiv" ;
VAL_ 2549088258 NM_Sekundaer_02_Subsystemaktiv 0 "Subsystem_war_nicht_lokalaktiv" 1 "war_lokalaktiv" ;
VAL_ 2549088258 Sekundaer_02_KD_Fehler 0 "kein_KD_Fehler" 1 "KD_Fehler" ;
VAL_ 779 KBI_ABS_Lampe 0 "ABS Lampe aus" 1 "ABS Lampe ein" ;
VAL_ 779 KBI_ESP_Lampe 0 "ESP Lampe aus" 1 "ESP Lampe ein" ;
VAL_ 779 KBI_BKL_Lampe 0 "BKL aus" 1 "BKL ein" ;
VAL_ 779 KBI_Airbag_Lampe 0 "Airbag Lampe aus" 1 "Airbag Lampe ein" ;
VAL_ 779 KBI_SILA_gueltig 0 "ungueltig" 1 "gueltig" ;
VAL_ 779 KBI_Vorglueh_System_Lampe 0 "Lampe aus" 1 "Lampe ein" ;
VAL_ 779 KBI_NV_in_Anzeige 0 "NV_nicht_in_Anzeige" 1 "NV_in_Anzeige" ;
VAL_ 779 KBI_Anzeigestatus_ACC 0 "keine_ACC_Anzeige" 1 "ACC_Anzeige_aktiv" ;
VAL_ 779 KBI_Anzeigestatus_GRA 0 "nicht_vorhanden" 1 "Anzeigemoeglichkeit_vorhanden" 2 "reserviert" 3 "Fehler" ;
VAL_ 779 KBI_Tankwarnung 0 "Lampe aus" 1 "Lampe ein" ;
VAL_ 779 KBI_MFA_v_Einheit_01 0 "kmh" 1 "mph" ;
VAL_ 779 KBI_im_Stellgliedtest 0 "kein Stellgliedtest" 1 "Kombi im Stellgliedtest" ;
VAL_ 779 KBI_Anzeigefehler_LDW 0 "nicht vorhanden bzw. unterstützt" 1 "Anzeige iO" 2 "Anzeigefehler" 3 "nicht definiert" ;
VAL_ 779 KBI_Tankwarnung_ungueltig 0 "KBI_Tankwarnung_gueltig" 1 "KBI_Tankwarnung_ungueltig" ;
VAL_ 779 KBI_Handbremse 0 "nicht_angezogen" 1 "angezogen" ;
VAL_ 779 KBI_PLA_in_Anzeige 0 "PLA_nicht_in_Anzeige" 1 "PLA_in_Anzeige" ;
VAL_ 779 KBI_Anzeigefehler_NV 0 "kein_Anzeigefehler" 1 "Anzeigefehler" ;
VAL_ 779 KBI_Anzeigestatus_LIM 0 "nicht_vorhanden" 1 "Anzeigemoeglichkeit_vorhanden" 2 "reserviert" 3 "Fehler" ;
VAL_ 779 KBI_ARA_in_Anzeige 0 "ARA nicht in Anzeige" 1 "ARA in Anzeige" ;
VAL_ 779 KBI_Taster_Lift 0 "nicht_betaetigt" 1 "betaetigt" ;
VAL_ 779 KBI_Taster_Fahrwerk 0 "nicht_betaetigt" 1 "betaetigt" ;
VAL_ 779 KBI_GRA_Hauptschalter 0 "Init" 1 "Hauptschalter_aus" 2 "Hauptschalter_ein" 3 "Fehler" ;
VAL_ 779 KBI_Einheit_Tacho 0 "km/h" 1 "mph" ;
VAL_ 779 KBI_Konsistenz_ACC 0 "ACC Botschaft konsistent" 1 "ACC Botschaft inkonsistent" ;
VAL_ 779 KBI_Fehler_Anzeige_ACC 0 " iO" 1 "Anzeigefehler ACC" ;
VAL_ 779 KBI_Anzeigefehler_SWA 0 "nicht vorhanden bzw. unterstützt" 1 "Anzeige iO" 2 "Anzeigefehler" 3 "nicht definiert" ;
VAL_ 779 KBI_Systemstatus 0 "KBI_IO" 1 "KBI_System_Failure" ;
